VERSION ""

NS_ :

BS_:

BU_: VMCU TECU OBDScanT2 IC3 EMS ECUspare2 ECUspare1 DACU CIOM BBM

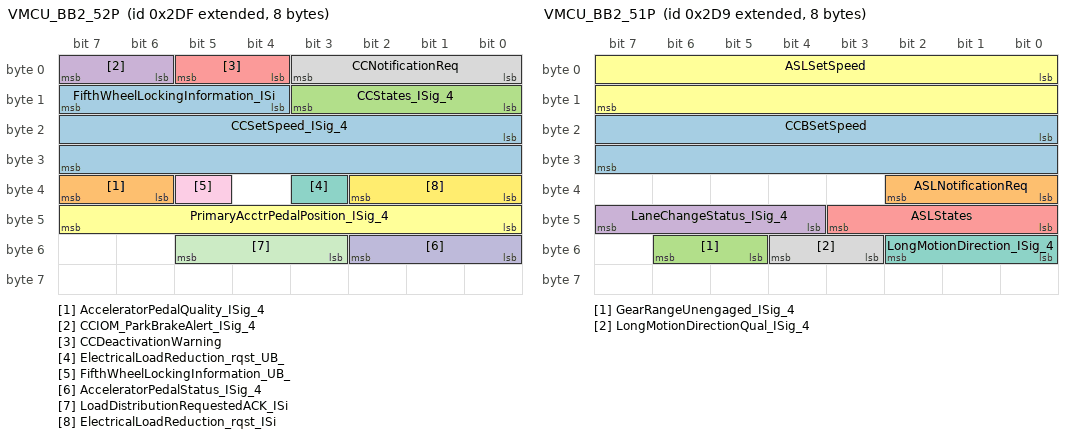
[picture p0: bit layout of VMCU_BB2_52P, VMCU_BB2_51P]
BO_ 2147484383 VMCU_BB2_52P: 8 VMCU
 SG_ CCSetSpeed_ISig_4 : 16|16@1+ (0.00390625,0) [0|255.99609375] "Km_per_h"  TECU,BBM,DACU,IC3
 SG_ AcceleratorPedalQuality_ISig_4 : 38|2@1+ (1,0) [0|0] ""  BBM,IC3
 SG_ CCStates_ISig_4 : 8|4@1+ (1,0) [0|0] ""  CIOM,DACU,IC3,BBM
 SG_ CCIOM_ParkBrakeAlert_ISig_4 : 6|2@1+ (1,0) [0|0] ""  IC3
 SG_ CCDeactivationWarning : 4|2@1+ (1,0) [0|0] ""  DACU
 SG_ PrimaryAcctrPedalPosition_ISig_4 : 40|8@1+ (0.4,0) [0|102] "Percent"  BBM
 SG_ ElectricalLoadReduction_rqst_UB_ : 35|1@1+ (1,0) [0|0] ""  CIOM
 SG_ CCNotificationReq : 0|4@1+ (1,0) [0|0] ""  IC3
 SG_ FifthWheelLockingInformation_UB_ : 37|1@1+ (1,0) [0|0] ""  BBM,IC3
 SG_ AcceleratorPedalStatus_ISig_4 : 48|3@1+ (1,0) [0|0] ""  CIOM,BBM
 SG_ LoadDistributionRequestedACK_ISi : 51|3@1+ (1,0) [0|0] ""  CIOM
 SG_ ElectricalLoadReduction_rqst_ISi : 32|3@1+ (1,0) [0|0] ""  CIOM
 SG_ FifthWheelLockingInformation_ISi : 12|4@1+ (1,0) [0|0] ""  BBM,IC3

BO_ 2147484377 VMCU_BB2_51P: 8 VMCU
 SG_ CCBSetSpeed : 16|16@1+ (0.00390625,0) [0|255.99609375] "Km_per_h"  DACU,TECU
 SG_ ASLNotificationReq : 32|3@1+ (1,0) [0|0] ""  IC3
 SG_ GearRangeUnengaged_ISig_4 : 53|2@1+ (1,0) [0|0] ""  IC3
 SG_ LaneChangeStatus_ISig_4 : 44|4@1+ (1,0) [0|0] ""  DACU,IC3
 SG_ ASLStates : 40|4@1+ (1,0) [0|0] ""  CIOM,IC3
 SG_ ASLSetSpeed : 0|16@1+ (0.00390625,0) [0|255.99609375] "Km_per_h"  IC3
 SG_ LongMotionDirection_ISig_4 : 48|3@1+ (1,0) [0|0] ""  BBM,CIOM
 SG_ LongMotionDirectionQual_ISig_4 : 51|2@1+ (1,0) [0|0] ""  CIOM

BO_ 2147484624 VMCU_BB2_34S_FCM: 8 CIOM
 SG_ VMCU_BB2_34S_FCS : 0|64@1+ (1,0) [0|0] ""  VMCU

BO_ 2147484621 VMCU_BB2_34S: 16 VMCU
 SG_ KeyID_KeyAuthEncrypted : 0|128@1+ (1,0) [0|0] ""  CIOM

BO_ 2147485066 VMCU_BB2_33S_FCM: 8 IC3
 SG_ VMCU_BB2_33S_FCS : 0|64@1+ (1,0) [0|0] ""  VMCU

BO_ 2147485065 VMCU_BB2_33S: 230 VMCU
 SG_ MaintInfoGrp_MaintOption30 : 52|4@1+ (1,0) [0|0] ""  IC3
 SG_ MaintInfoGrp_Unit36 : 363|3@1+ (1,0) [0|0] ""  IC3
 SG_ MaintInfoGrp_MaintOption33 : 40|4@1+ (1,0) [0|0] ""  IC3
 SG_ MaintInfoGrp_ResetAuthorized32 : 506|2@1+ (1,0) [0|0] ""  IC3
 SG_ MaintInfoGrp_Status10 : 395|3@1+ (1,0) [0|0] ""  IC3
 SG_ MaintInfoGrp_Unit2 : 459|3@1+ (1,0) [0|0] ""  IC3
 SG_ MaintInfoGrp_Unit14 : 160|3@1+ (1,0) [0|0] ""  IC3
 SG_ MaintInfoGrp_ResetAuthorized28 : 486|2@1+ (1,0) [0|0] ""  IC3
 SG_ MaintInfoGrp_ResetAuthorized10 : 510|2@1+ (1,0) [0|0] ""  IC3
 SG_ MaintInfoGrp_Status31 : 368|3@1+ (1,0) [0|0] ""  IC3
 SG_ MaintInfoGrp_Unit32 : 427|3@1+ (1,0) [0|0] ""  IC3
 SG_ MaintInfoGrp_Status15 : 251|3@1+ (1,0) [0|0] ""  IC3
 SG_ MaintInfoGrp_Supported19 : 278|2@1+ (1,0) [0|0] ""  IC3
 SG_ MaintInfoGrp_Unit34 : 312|3@1+ (1,0) [0|0] ""  IC3
 SG_ MaintInfoGrp_Data17 : 816|32@1+ (1,0) [0|4294967295] ""  IC3
 SG_ MaintInfoGrp_Unit26 : 179|3@1+ (1,0) [0|0] ""  IC3
 SG_ MaintInfoGrp_Data24 : 848|32@1+ (1,0) [0|4294967295] ""  IC3
 SG_ MaintInfoGrp_ResetAuthorized24 : 502|2@1+ (1,0) [0|0] ""  IC3
 SG_ MaintInfoGrp_ResetAuthorized34 : 454|2@1+ (1,0) [0|0] ""  IC3
 SG_ MaintInfoGrp_Unit28 : 176|3@1+ (1,0) [0|0] ""  IC3
 SG_ MaintInfoGrp_Status26 : 219|3@1+ (1,0) [0|0] ""  IC3
 SG_ MaintInfoGrp_Unit10 : 352|3@1+ (1,0) [0|0] ""  IC3
 SG_ MaintInfoGrp_Data12 : 1616|32@1+ (1,0) [0|4294967295] ""  IC3
 SG_ MaintInfoGrp_ResetAuthorized38 : 230|2@1+ (1,0) [0|0] ""  IC3
 SG_ MaintInfoGrp_MaintOption14 : 128|4@1+ (1,0) [0|0] ""  IC3
 SG_ MaintInfoGrp_MaintOption17 : 0|4@1+ (1,0) [0|0] ""  IC3
 SG_ MaintInfoGrp_Status33 : 360|3@1+ (1,0) [0|0] ""  IC3
 SG_ MaintInfoGrp_Unit6 : 203|3@1+ (1,0) [0|0] ""  IC3
 SG_ MaintInfoGrp_Supported7 : 504|2@1+ (1,0) [0|0] ""  IC3
 SG_ MaintInfoGrp_Status7 : 240|3@1+ (1,0) [0|0] ""  IC3
 SG_ MaintInfoGrp_ResetAuthorized2 : 462|2@1+ (1,0) [0|0] ""  IC3
 SG_ MaintInfoGrp_MaintOption27 : 44|4@1+ (1,0) [0|0] ""  IC3
 SG_ MaintInfoGrp_Supported36 : 492|2@1+ (1,0) [0|0] ""  IC3
 SG_ MaintInfoGrp_Unit22 : 171|3@1+ (1,0) [0|0] ""  IC3
 SG_ MaintInfoGrp_Unit18 : 315|3@1+ (1,0) [0|0] ""  IC3
 SG_ MaintInfoGrp_MaintOption28 : 96|4@1+ (1,0) [0|0] ""  IC3
 SG_ MaintInfoGrp_Supported18 : 526|2@1+ (1,0) [0|0] ""  IC3
 SG_ MaintInfoGrp_Status22 : 304|3@1+ (1,0) [0|0] ""  IC3
 SG_ MaintInfoGrp_Status30 : 200|3@1+ (1,0) [0|0] ""  IC3
 SG_ MaintInfoGrp_Status20 : 467|3@1+ (1,0) [0|0] ""  IC3
 SG_ MaintInfoGrp_Status38 : 419|3@1+ (1,0) [0|0] ""  IC3
 SG_ MaintInfoGrp_Data38 : 688|32@1+ (1,0) [0|4294967295] ""  IC3
 SG_ MaintInfoGrp_ResetAuthorized7 : 190|2@1+ (1,0) [0|0] ""  IC3
 SG_ MaintInfoGrp_Data19 : 1104|32@1+ (1,0) [0|4294967295] ""  IC3
 SG_ MaintInfoGrp_ResetAuthorized19 : 438|2@1+ (1,0) [0|0] ""  IC3
 SG_ MaintInfoGrp_ResetAuthorized12 : 542|2@1+ (1,0) [0|0] ""  IC3
 SG_ MaintInfoGrp_MaintOption8 : 108|4@1+ (1,0) [0|0] ""  IC3
 SG_ MaintInfoGrp_MaintOption9 : 56|4@1+ (1,0) [0|0] ""  IC3
 SG_ MaintInfoGrp_ResetAuthorized13 : 522|2@1+ (1,0) [0|0] ""  IC3
 SG_ MaintInfoGrp_Unit31 : 283|3@1+ (1,0) [0|0] ""  IC3
 SG_ MaintInfoGrp_Status2 : 400|3@1+ (1,0) [0|0] ""  IC3
 SG_ MaintInfoGrp_ResetAuthorized5 : 206|2@1+ (1,0) [0|0] ""  IC3
 SG_ MaintInfoGrp_Supported33 : 350|2@1+ (1,0) [0|0] ""  IC3
 SG_ MaintInfoGrp_Unit7 : 256|3@1+ (1,0) [0|0] ""  IC3
 SG_ MaintInfoGrp_Supported34 : 524|2@1+ (1,0) [0|0] ""  IC3
 SG_ MaintInfoGrp_Data16 : 1392|32@1+ (1,0) [0|4294967295] ""  IC3
 SG_ MaintInfoGrp_Unit19 : 299|3@1+ (1,0) [0|0] ""  IC3
 SG_ MaintInfoGrp_ResetAuthorized21 : 494|2@1+ (1,0) [0|0] ""  IC3
 SG_ MaintInfoGrp_ResetAuthorized31 : 552|2@1+ (1,0) [0|0] ""  IC3
 SG_ MaintInfoGrp_Data28 : 1488|32@1+ (1,0) [0|4294967295] ""  IC3
 SG_ MaintInfoGrp_ResetAuthorized3 : 374|2@1+ (1,0) [0|0] ""  IC3
 SG_ MaintInfoGrp_MaintOption34 : 12|4@1+ (1,0) [0|0] ""  IC3
 SG_ MaintInfoGrp_Status21 : 475|3@1+ (1,0) [0|0] ""  IC3
 SG_ MaintInfoGrp_Unit21 : 235|3@1+ (1,0) [0|0] ""  IC3
 SG_ MaintInfoGrp_MaintOption24 : 116|4@1+ (1,0) [0|0] ""  IC3
 SG_ MaintInfoGrp_Data26 : 976|32@1+ (1,0) [0|4294967295] ""  IC3
 SG_ MaintInfoGrp_Data37 : 752|32@1+ (1,0) [0|4294967295] ""  IC3
 SG_ MaintInfoGrp_Data35 : 1136|32@1+ (1,0) [0|4294967295] ""  IC3
 SG_ MaintInfoGrp_Supported17 : 222|2@1+ (1,0) [0|0] ""  IC3
 SG_ MaintInfoGrp_ResetAuthorized17 : 546|2@1+ (1,0) [0|0] ""  IC3
 SG_ MaintInfoGrp_Unit25 : 248|3@1+ (1,0) [0|0] ""  IC3
 SG_ MaintInfoGrp_Unit37 : 344|3@1+ (1,0) [0|0] ""  IC3
 SG_ MaintInfoGrp_MaintOption2 : 60|4@1+ (1,0) [0|0] ""  IC3
 SG_ MaintInfoGrp_Supported21 : 406|2@1+ (1,0) [0|0] ""  IC3
 SG_ MaintInfoGrp_ResetAuthorized16 : 270|2@1+ (1,0) [0|0] ""  IC3
 SG_ MaintInfoGrp_Supported15 : 528|2@1+ (1,0) [0|0] ""  IC3
 SG_ MaintInfoGrp_ResetAuthorized9 : 540|2@1+ (1,0) [0|0] ""  IC3
 SG_ MaintInfoGrp_MaintOption18 : 36|4@1+ (1,0) [0|0] ""  IC3
 SG_ MaintInfoGrp_Data14 : 1456|32@1+ (1,0) [0|4294967295] ""  IC3
 SG_ MaintInfoGrp_Data8 : 1808|32@1+ (1,0) [0|4294967295] ""  IC3
 SG_ MaintInfoGrp_Supported29 : 484|2@1+ (1,0) [0|0] ""  IC3
 SG_ MaintInfoGrp_ResetAuthorized39 : 558|2@1+ (1,0) [0|0] ""  IC3
 SG_ MaintInfoGrp_Supported32 : 358|2@1+ (1,0) [0|0] ""  IC3
 SG_ MaintInfoGrp_Data33 : 1328|32@1+ (1,0) [0|4294967295] ""  IC3
 SG_ MaintInfoGrp_ResetAuthorized35 : 550|2@1+ (1,0) [0|0] ""  IC3
 SG_ MaintInfoGrp_Data30 : 880|32@1+ (1,0) [0|4294967295] ""  IC3
 SG_ MaintInfoGrp_ResetAuthorized29 : 534|2@1+ (1,0) [0|0] ""  IC3
 SG_ MaintInfoGrp_Supported35 : 310|2@1+ (1,0) [0|0] ""  IC3
 SG_ MaintInfoGrp_ResetAuthorized4 : 530|2@1+ (1,0) [0|0] ""  IC3
 SG_ MaintInfoGrp_Data10 : 624|32@1+ (1,0) [0|4294967295] ""  IC3
 SG_ MaintInfoGrp_Data9 : 1584|32@1+ (1,0) [0|4294967295] ""  IC3
 SG_ MaintInfoGrp_Unit1 : 328|3@1+ (1,0) [0|0] ""  IC3
 SG_ MaintInfoGrp_MaintOption7 : 104|4@1+ (1,0) [0|0] ""  IC3
 SG_ MaintInfoGrp_Supported24 : 390|2@1+ (1,0) [0|0] ""  IC3
 SG_ MaintInfoGrp_Supported25 : 514|2@1+ (1,0) [0|0] ""  IC3
 SG_ MaintInfoGrp_Unit15 : 339|3@1+ (1,0) [0|0] ""  IC3
 SG_ MaintInfoGrp_Supported1 : 446|2@1+ (1,0) [0|0] ""  IC3
 SG_ MaintInfoGrp_ResetAuthorized11 : 254|2@1+ (1,0) [0|0] ""  IC3
 SG_ MaintInfoGrp_Supported13 : 238|2@1+ (1,0) [0|0] ""  IC3
 SG_ MaintInfoGrp_Supported10 : 490|2@1+ (1,0) [0|0] ""  IC3
 SG_ MaintInfoGrp_Data2 : 720|32@1+ (1,0) [0|4294967295] ""  IC3
 SG_ MaintInfoGrp_Unit16 : 243|3@1+ (1,0) [0|0] ""  IC3
 SG_ MaintInfoGrp_MaintOption35 : 144|4@1+ (1,0) [0|0] ""  IC3
 SG_ MaintInfoGrp_MaintOption22 : 156|4@1+ (1,0) [0|0] ""  IC3
 SG_ MaintInfoGrp_MaintOption12 : 8|4@1+ (1,0) [0|0] ""  IC3
 SG_ MaintInfoGrp_Supported9 : 342|2@1+ (1,0) [0|0] ""  IC3
 SG_ MaintInfoGrp_Supported31 : 512|2@1+ (1,0) [0|0] ""  IC3
 SG_ MaintInfoGrp_MaintOption37 : 100|4@1+ (1,0) [0|0] ""  IC3
 SG_ MaintInfoGrp_MaintOption13 : 120|4@1+ (1,0) [0|0] ""  IC3
 SG_ MaintInfoGrp_ResetAuthorized22 : 538|2@1+ (1,0) [0|0] ""  IC3
 SG_ MaintInfoGrp_Status14 : 259|3@1+ (1,0) [0|0] ""  IC3
 SG_ MaintInfoGrp_Status18 : 424|3@1+ (1,0) [0|0] ""  IC3
 SG_ MaintInfoGrp_Unit17 : 187|3@1+ (1,0) [0|0] ""  IC3
 SG_ MaintInfoGrp_Unit12 : 224|3@1+ (1,0) [0|0] ""  IC3
 SG_ MaintInfoGrp_Data22 : 1552|32@1+ (1,0) [0|4294967295] ""  IC3
 SG_ MaintInfoGrp_Supported27 : 262|2@1+ (1,0) [0|0] ""  IC3
 SG_ MaintInfoGrp_Unit4 : 163|3@1+ (1,0) [0|0] ""  IC3
 SG_ MaintInfoGrp_Data13 : 656|32@1+ (1,0) [0|4294967295] ""  IC3
 SG_ MaintInfoGrp_Status27 : 355|3@1+ (1,0) [0|0] ""  IC3
 SG_ MaintInfoGrp_MaintOption29 : 124|4@1+ (1,0) [0|0] ""  IC3
 SG_ MaintInfoGrp_Unit9 : 435|3@1+ (1,0) [0|0] ""  IC3
 SG_ MaintInfoGrp_Unit13 : 387|3@1+ (1,0) [0|0] ""  IC3
 SG_ MaintInfoGrp_Data25 : 560|32@1+ (1,0) [0|4294967295] ""  IC3
 SG_ MaintInfoGrp_Unit3 : 472|3@1+ (1,0) [0|0] ""  IC3
 SG_ MaintInfoGrp_MaintOption15 : 148|4@1+ (1,0) [0|0] ""  IC3
 SG_ MaintInfoGrp_ResetAuthorized15 : 508|2@1+ (1,0) [0|0] ""  IC3
 SG_ MaintInfoGrp_MaintOption11 : 68|4@1+ (1,0) [0|0] ""  IC3
 SG_ MaintInfoGrp_MaintOption25 : 112|4@1+ (1,0) [0|0] ""  IC3
 SG_ MaintInfoGrp_Supported16 : 174|2@1+ (1,0) [0|0] ""  IC3
 SG_ MaintInfoGrp_Supported23 : 544|2@1+ (1,0) [0|0] ""  IC3
 SG_ MaintInfoGrp_Status13 : 267|3@1+ (1,0) [0|0] ""  IC3
 SG_ MaintInfoGrp_Status17 : 307|3@1+ (1,0) [0|0] ""  IC3
 SG_ MaintInfoGrp_Unit8 : 275|3@1+ (1,0) [0|0] ""  IC3
 SG_ MaintInfoGrp_MaintOption38 : 64|4@1+ (1,0) [0|0] ""  IC3
 SG_ MaintInfoGrp_Data4 : 1040|32@1+ (1,0) [0|4294967295] ""  IC3
 SG_ MaintInfoGrp_Supported2 : 198|2@1+ (1,0) [0|0] ""  IC3
 SG_ MaintInfoGrp_ResetAuthorized0 : 516|2@1+ (1,0) [0|0] ""  IC3
 SG_ MaintInfoGrp_Supported5 : 478|2@1+ (1,0) [0|0] ""  IC3
 SG_ MaintInfoGrp_Status6 : 336|3@1+ (1,0) [0|0] ""  IC3
 SG_ MaintInfoGrp_Unit5 : 411|3@1+ (1,0) [0|0] ""  IC3
 SG_ MaintInfoGrp_Data0 : 592|32@1+ (1,0) [0|4294967295] ""  IC3
 SG_ MaintInfoGrp_Data29 : 1776|32@1+ (1,0) [0|4294967295] ""  IC3
 SG_ MaintInfoGrp_Supported28 : 498|2@1+ (1,0) [0|0] ""  IC3
 SG_ MaintInfoGrp_Status32 : 371|3@1+ (1,0) [0|0] ""  IC3
 SG_ MaintInfoGrp_MaintOption0 : 152|4@1+ (1,0) [0|0] ""  IC3
 SG_ MaintInfoGrp_ResetAuthorized25 : 480|2@1+ (1,0) [0|0] ""  IC3
 SG_ MaintInfoGrp_MaintOption32 : 28|4@1+ (1,0) [0|0] ""  IC3
 SG_ MaintInfoGrp_Unit11 : 464|3@1+ (1,0) [0|0] ""  IC3
 SG_ MaintInfoGrp_Data39 : 912|32@1+ (1,0) [0|4294967295] ""  IC3
 SG_ MaintInfoGrp_MaintOption4 : 80|4@1+ (1,0) [0|0] ""  IC3
 SG_ MaintInfoGrp_Supported38 : 302|2@1+ (1,0) [0|0] ""  IC3
 SG_ MaintInfoGrp_MaintOption1 : 136|4@1+ (1,0) [0|0] ""  IC3
 SG_ MaintInfoGrp_Supported30 : 182|2@1+ (1,0) [0|0] ""  IC3
 SG_ MaintInfoGrp_ResetAuthorized33 : 496|2@1+ (1,0) [0|0] ""  IC3
 SG_ MaintInfoGrp_Status0 : 392|3@1+ (1,0) [0|0] ""  IC3
 SG_ MaintInfoGrp_ResetAuthorized20 : 334|2@1+ (1,0) [0|0] ""  IC3
 SG_ MaintInfoGrp_Unit33 : 232|3@1+ (1,0) [0|0] ""  IC3
 SG_ MaintInfoGrp_Supported26 : 500|2@1+ (1,0) [0|0] ""  IC3
 SG_ MaintInfoGrp_ResetAuthorized6 : 532|2@1+ (1,0) [0|0] ""  IC3
 SG_ MaintInfoGrp_Data18 : 1648|32@1+ (1,0) [0|4294967295] ""  IC3
 SG_ MaintInfoGrp_Status16 : 432|3@1+ (1,0) [0|0] ""  IC3
 SG_ MaintInfoGrp_ResetAuthorized18 : 294|2@1+ (1,0) [0|0] ""  IC3
 SG_ MaintInfoGrp_Status4 : 168|3@1+ (1,0) [0|0] ""  IC3
 SG_ MaintInfoGrp_Data3 : 1072|32@1+ (1,0) [0|4294967295] ""  IC3
 SG_ MaintInfoGrp_MaintOption20 : 140|4@1+ (1,0) [0|0] ""  IC3
 SG_ MaintInfoGrp_ResetAuthorized30 : 166|2@1+ (1,0) [0|0] ""  IC3
 SG_ MaintInfoGrp_ResetAuthorized23 : 520|2@1+ (1,0) [0|0] ""  IC3
 SG_ MaintInfoGrp_Unit30 : 408|3@1+ (1,0) [0|0] ""  IC3
 SG_ MaintInfoGrp_Data20 : 944|32@1+ (1,0) [0|4294967295] ""  IC3
 SG_ MaintInfoGrp_MaintOption23 : 132|4@1+ (1,0) [0|0] ""  IC3
 SG_ MaintInfoGrp_Data23 : 1680|32@1+ (1,0) [0|4294967295] ""  IC3
 SG_ MaintInfoGrp_Unit20 : 376|3@1+ (1,0) [0|0] ""  IC3
 SG_ MaintInfoGrp_MaintOption10 : 76|4@1+ (1,0) [0|0] ""  IC3
 SG_ MaintInfoGrp_Status39 : 443|3@1+ (1,0) [0|0] ""  IC3
 SG_ MaintInfoGrp_Data21 : 1424|32@1+ (1,0) [0|4294967295] ""  IC3
 SG_ MaintInfoGrp_Status3 : 451|3@1+ (1,0) [0|0] ""  IC3
 SG_ MaintInfoGrp_Data5 : 784|32@1+ (1,0) [0|4294967295] ""  IC3
 SG_ MaintInfoGrp_ResetAuthorized26 : 556|2@1+ (1,0) [0|0] ""  IC3
 SG_ MaintInfoGrp_Supported12 : 366|2@1+ (1,0) [0|0] ""  IC3
 SG_ MaintInfoGrp_Data32 : 1296|32@1+ (1,0) [0|4294967295] ""  IC3
 SG_ MaintInfoGrp_Status29 : 323|3@1+ (1,0) [0|0] ""  IC3
 SG_ MaintInfoGrp_ResetAuthorized37 : 246|2@1+ (1,0) [0|0] ""  IC3
 SG_ MaintInfoGrp_Status36 : 379|3@1+ (1,0) [0|0] ""  IC3
 SG_ MaintInfoGrp_Supported22 : 326|2@1+ (1,0) [0|0] ""  IC3
 SG_ MaintInfoGrp_Status35 : 331|3@1+ (1,0) [0|0] ""  IC3
 SG_ MaintInfoGrp_Data7 : 1360|32@1+ (1,0) [0|4294967295] ""  IC3
 SG_ MaintInfoGrp_MaintOption26 : 48|4@1+ (1,0) [0|0] ""  IC3
 SG_ MaintInfoGrp_Status23 : 403|3@1+ (1,0) [0|0] ""  IC3
 SG_ MaintInfoGrp_Unit35 : 192|3@1+ (1,0) [0|0] ""  IC3
 SG_ MaintInfoGrp_Supported6 : 398|2@1+ (1,0) [0|0] ""  IC3
 SG_ MaintInfoGrp_Data34 : 1008|32@1+ (1,0) [0|4294967295] ""  IC3
 SG_ MaintInfoGrp_Unit27 : 416|3@1+ (1,0) [0|0] ""  IC3
 SG_ MaintInfoGrp_MaintOption19 : 72|4@1+ (1,0) [0|0] ""  IC3
 SG_ MaintInfoGrp_ResetAuthorized14 : 214|2@1+ (1,0) [0|0] ""  IC3
 SG_ MaintInfoGrp_Status34 : 272|3@1+ (1,0) [0|0] ""  IC3
 SG_ MaintInfoGrp_Supported37 : 286|2@1+ (1,0) [0|0] ""  IC3
 SG_ MaintInfoGrp_MaintOption3 : 20|4@1+ (1,0) [0|0] ""  IC3
 SG_ MaintInfoGrp_Status1 : 384|3@1+ (1,0) [0|0] ""  IC3
 SG_ MaintInfoGrp_Data1 : 1200|32@1+ (1,0) [0|4294967295] ""  IC3
 SG_ MaintInfoGrp_Status25 : 296|3@1+ (1,0) [0|0] ""  IC3
 SG_ MaintInfoGrp_ResetAuthorized1 : 318|2@1+ (1,0) [0|0] ""  IC3
 SG_ MaintInfoGrp_ResetAuthorized27 : 518|2@1+ (1,0) [0|0] ""  IC3
 SG_ MaintInfoGrp_ResetAuthorized36 : 470|2@1+ (1,0) [0|0] ""  IC3
 SG_ MaintInfoGrp_Status28 : 347|3@1+ (1,0) [0|0] ""  IC3
 SG_ MaintInfoGrp_Status24 : 280|3@1+ (1,0) [0|0] ""  IC3
 SG_ MaintInfoGrp_MaintOption31 : 32|4@1+ (1,0) [0|0] ""  IC3
 SG_ MaintInfoGrp_Supported20 : 482|2@1+ (1,0) [0|0] ""  IC3
 SG_ MaintInfoGrp_Unit38 : 195|3@1+ (1,0) [0|0] ""  IC3
 SG_ MaintInfoGrp_Unit24 : 448|3@1+ (1,0) [0|0] ""  IC3
 SG_ MaintInfoGrp_Data15 : 1264|32@1+ (1,0) [0|4294967295] ""  IC3
 SG_ MaintInfoGrp_Status37 : 440|3@1+ (1,0) [0|0] ""  IC3
 SG_ MaintInfoGrp_Supported39 : 414|2@1+ (1,0) [0|0] ""  IC3
 SG_ MaintInfoGrp_MaintOption39 : 4|4@1+ (1,0) [0|0] ""  IC3
 SG_ MaintInfoGrp_Supported4 : 430|2@1+ (1,0) [0|0] ""  IC3
 SG_ MaintInfoGrp_Supported3 : 536|2@1+ (1,0) [0|0] ""  IC3
 SG_ MaintInfoGrp_Data6 : 1520|32@1+ (1,0) [0|4294967295] ""  IC3
 SG_ MaintInfoGrp_Unit39 : 320|3@1+ (1,0) [0|0] ""  IC3
 SG_ MaintInfoGrp_Status5 : 291|3@1+ (1,0) [0|0] ""  IC3
 SG_ MaintInfoGrp_Data36 : 1232|32@1+ (1,0) [0|4294967295] ""  IC3
 SG_ MaintInfoGrp_MaintOption6 : 84|4@1+ (1,0) [0|0] ""  IC3
 SG_ MaintInfoGrp_Status11 : 211|3@1+ (1,0) [0|0] ""  IC3
 SG_ MaintInfoGrp_Status19 : 216|3@1+ (1,0) [0|0] ""  IC3
 SG_ MaintInfoGrp_Status9 : 288|3@1+ (1,0) [0|0] ""  IC3
 SG_ MaintInfoGrp_Supported11 : 548|2@1+ (1,0) [0|0] ""  IC3
 SG_ MaintInfoGrp_Data27 : 1168|32@1+ (1,0) [0|4294967295] ""  IC3
 SG_ MaintInfoGrp_Data31 : 1744|32@1+ (1,0) [0|4294967295] ""  IC3
 SG_ MaintInfoGrp_MaintOption36 : 16|4@1+ (1,0) [0|0] ""  IC3
 SG_ MaintInfoGrp_ResetAuthorized8 : 422|2@1+ (1,0) [0|0] ""  IC3
 SG_ MaintInfoGrp_MaintOption21 : 92|4@1+ (1,0) [0|0] ""  IC3
 SG_ MaintInfoGrp_Unit23 : 227|3@1+ (1,0) [0|0] ""  IC3
 SG_ MaintInfoGrp_MaintOption5 : 88|4@1+ (1,0) [0|0] ""  IC3
 SG_ MaintInfoGrp_MaintOption16 : 24|4@1+ (1,0) [0|0] ""  IC3
 SG_ MaintInfoGrp_Unit29 : 208|3@1+ (1,0) [0|0] ""  IC3
 SG_ MaintInfoGrp_Status12 : 184|3@1+ (1,0) [0|0] ""  IC3
 SG_ MaintInfoGrp_Supported0 : 554|2@1+ (1,0) [0|0] ""  IC3
 SG_ MaintInfoGrp_Status8 : 456|3@1+ (1,0) [0|0] ""  IC3
 SG_ MaintInfoGrp_Data11 : 1712|32@1+ (1,0) [0|4294967295] ""  IC3
 SG_ MaintInfoGrp_Unit0 : 264|3@1+ (1,0) [0|0] ""  IC3
 SG_ MaintInfoGrp_Supported14 : 488|2@1+ (1,0) [0|0] ""  IC3
 SG_ MaintInfoGrp_Supported8 : 382|2@1+ (1,0) [0|0] ""  IC3

BO_ 2147484995 VMCU_BB2_32S_FCM: 8 CIOM
 SG_ VMCU_BB2_32S_FCS : 0|64@1+ (1,0) [0|0] ""  VMCU

BO_ 2147484993 VMCU_BB2_32S: 11 VMCU
 SG_ ECU2VIN_stat_ISig_4 : 0|88@1+ (1,0) [0|0] ""  CIOM

BO_ 2147485021 VMCU_BB2_31S_FCM: 8 CIOM
 SG_ VMCU_BB2_31S_FCS : 0|64@1+ (1,0) [0|0] ""  VMCU

BO_ 2147485020 VMCU_BB2_31S: 11 VMCU
 SG_ ECU1VIN_stat : 0|88@1+ (1,0) [0|0] ""  CIOM

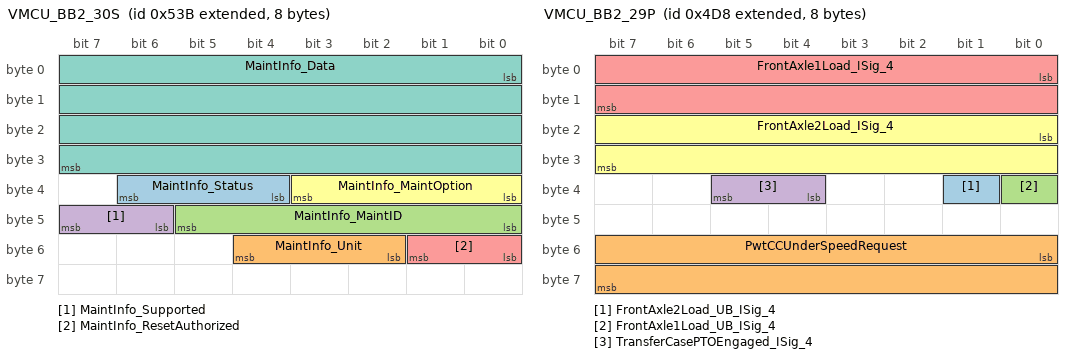
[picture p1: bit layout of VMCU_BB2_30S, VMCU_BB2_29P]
BO_ 2147484987 VMCU_BB2_30S: 8 VMCU
 SG_ MaintInfo_Status : 36|3@1+ (1,0) [0|0] ""  IC3
 SG_ MaintInfo_Unit : 50|3@1+ (1,0) [0|0] ""  IC3
 SG_ MaintInfo_MaintID : 40|6@1+ (1,0) [0|0] ""  IC3
 SG_ MaintInfo_Supported : 46|2@1+ (1,0) [0|0] ""  IC3
 SG_ MaintInfo_ResetAuthorized : 48|2@1+ (1,0) [0|0] ""  IC3
 SG_ MaintInfo_MaintOption : 32|4@1+ (1,0) [0|0] ""  IC3
 SG_ MaintInfo_Data : 0|32@1+ (1,0) [0|4294967295] ""  IC3

BO_ 2147484888 VMCU_BB2_29P: 8 VMCU
 SG_ FrontAxle2Load_UB_ISig_4 : 33|1@1+ (1,0) [0|0] ""  TECU,BBM,DACU,IC3
 SG_ PwtCCUnderSpeedRequest : 48|16@1+ (0.00390625,0) [0|255.99609375] "Km_per_h"  TECU
 SG_ FrontAxle1Load_UB_ISig_4 : 32|1@1+ (1,0) [0|0] ""  TECU,DACU,IC3,BBM
 SG_ TransferCasePTOEngaged_ISig_4 : 36|2@1+ (1,0) [0|0] ""  CIOM
 SG_ FrontAxle1Load_ISig_4 : 0|16@1+ (0.5,0) [0|32767.5] "kg"  DACU,TECU,BBM
 SG_ FrontAxle2Load_ISig_4 : 16|16@1+ (0.5,0) [0|32767.5] "kg"  DACU,BBM,TECU

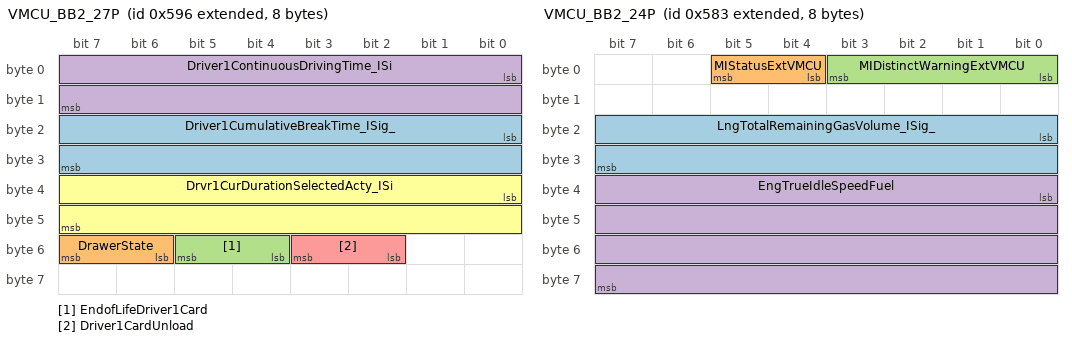
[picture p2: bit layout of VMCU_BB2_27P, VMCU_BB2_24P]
BO_ 2147485078 VMCU_BB2_27P: 8 VMCU
 SG_ Driver1CumulativeBreakTime_ISig_ : 16|16@1+ (1,0) [0|65535] "min"  IC3
 SG_ DrawerState : 54|2@1+ (1,0) [0|0] ""  IC3
 SG_ EndofLifeDriver1Card : 52|2@1+ (1,0) [0|0] ""  IC3
 SG_ Driver1ContinuousDrivingTime_ISi : 0|16@1+ (1,0) [0|65535] "min"  IC3
 SG_ Driver1CardUnload : 50|2@1+ (1,0) [0|0] ""  IC3
 SG_ Drvr1CurDurationSelectedActy_ISi : 32|16@1+ (1,0) [0|65535] "min"  IC3

BO_ 2147485061 VMCU_BB2_26P: 8 VMCU
 SG_ FuelConsumptionPTO : 32|32@1+ (0.01,0) [0|42949672.95] "l"  IC3
 SG_ AtLeastOnePTOActivationTime_ISig : 0|32@1+ (1,0) [0|4294967295] "s"  IC3,BBM

BO_ 2147485060 VMCU_BB2_25P: 8 VMCU
 SG_ EngineGreenAreaOutFuel_ISig_4 : 0|32@1+ (0.01,0) [0|42949672.95] "l"  IC3
 SG_ CCTime : 32|32@1+ (1,0) [0|4294967295] "s"  IC3

BO_ 2147485059 VMCU_BB2_24P: 8 VMCU
 SG_ LngTotalRemainingGasVolume_ISig_ : 16|16@1+ (1,0) [0|65535] "kg"  IC3
 SG_ MIStatusExtVMCU : 4|2@1+ (1,0) [0|0] ""  EMS
 SG_ MIDistinctWarningExtVMCU : 0|4@1+ (1,0) [0|0] ""  EMS
 SG_ EngTrueIdleSpeedFuel : 32|32@1+ (0.01,0) [0|42949672.95] "l"  IC3

BO_ 2147485036 VMCU_BB2_23P: 8 VMCU
 SG_ FuelConsumptionVehicleStopped : 32|32@1+ (0.01,0) [0|42949672.95] "l"  IC3
 SG_ FuelConsumptionVehicleRunning_IS : 0|32@1+ (0.01,0) [0|42949672.95] "l"  IC3

BO_ 2147485037 VMCU_BB2_22P: 8 VMCU
 SG_ AdBlueConsumptVehicleRunning : 0|32@1+ (0.01,0) [0|42949672.95] "l"  IC3
 SG_ AdBlueConsumptVehicleStopped : 32|32@1+ (0.01,0) [0|42949672.95] "l"  IC3

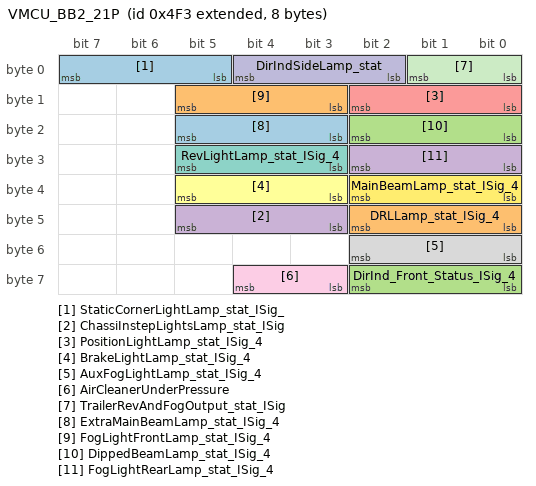
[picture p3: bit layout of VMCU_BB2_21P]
BO_ 2147484915 VMCU_BB2_21P: 8 VMCU
 SG_ StaticCornerLightLamp_stat_ISig_ : 5|3@1+ (1,0) [0|0] ""  IC3
 SG_ DRLLamp_stat_ISig_4 : 40|3@1+ (1,0) [0|0] ""  IC3
 SG_ DirInd_Front_Status_ISig_4 : 56|3@1+ (1,0) [0|0] ""  IC3
 SG_ ChassiInstepLightsLamp_stat_ISig : 43|3@1+ (1,0) [0|0] ""  IC3
 SG_ PositionLightLamp_stat_ISig_4 : 8|3@1+ (1,0) [0|0] ""  IC3
 SG_ BrakeLightLamp_stat_ISig_4 : 35|3@1+ (1,0) [0|0] ""  IC3
 SG_ RevLightLamp_stat_ISig_4 : 27|3@1+ (1,0) [0|0] ""  IC3
 SG_ AuxFogLightLamp_stat_ISig_4 : 48|3@1+ (1,0) [0|0] ""  IC3
 SG_ AirCleanerUnderPressure : 59|2@1+ (1,0) [0|0] ""  IC3
 SG_ DirIndSideLamp_stat : 2|3@1+ (1,0) [0|0] ""  IC3
 SG_ TrailerRevAndFogOutput_stat_ISig : 0|2@1+ (1,0) [0|0] ""  IC3
 SG_ MainBeamLamp_stat_ISig_4 : 32|3@1+ (1,0) [0|0] ""  IC3
 SG_ ExtraMainBeamLamp_stat_ISig_4 : 19|3@1+ (1,0) [0|0] ""  IC3
 SG_ FogLightFrontLamp_stat_ISig_4 : 11|3@1+ (1,0) [0|0] ""  IC3
 SG_ DippedBeamLamp_stat_ISig_4 : 16|3@1+ (1,0) [0|0] ""  IC3
 SG_ FogLightRearLamp_stat_ISig_4 : 24|3@1+ (1,0) [0|0] ""  IC3

CM_ SG_ 2147484383 CCSetSpeed_ISig_4 "65024 - 65279 Error ; 65280 - 65535 Not available";
CM_ SG_ 2147484377 CCBSetSpeed "65024 - 65279 Error ; 65280 - 65535 Not available";
CM_ SG_ 2147484377 ASLSetSpeed "65024 - 65279 Error ; 65280 - 65535 Not available";
CM_ SG_ 2147484888 FrontAxle1Load_ISig_4 "65024 - 65279 Error ; 65280 - 65535 Not available";
CM_ SG_ 2147484888 FrontAxle2Load_ISig_4 "65024 - 65279 Error ; 65280 - 65535 Not available";
CM_ SG_ 2147485078 Driver1CumulativeBreakTime_ISig_ "65024 - 65279 Error ; 65280 - 65535 Not available";
CM_ SG_ 2147485078 Driver1ContinuousDrivingTime_ISi "65024 - 65279 Error ; 65280 - 65535 Not available";
CM_ SG_ 2147485078 Drvr1CurDurationSelectedActy_ISi "65024 - 65279 Error ; 65280 - 65535 Not available";
CM_ SG_ 2147485061 AtLeastOnePTOActivationTime_ISig "4294967295 Not available";
CM_ SG_ 2147485060 EngineGreenAreaOutFuel_ISig_4 "4294967295 Not available";
CM_ SG_ 2147485060 CCTime "4294967295 Not available";
CM_ SG_ 2147485059 EngTrueIdleSpeedFuel "4294967295 Not available";
CM_ SG_ 2147485036 FuelConsumptionVehicleStopped "4294967295 Not available";
CM_ SG_ 2147485036 FuelConsumptionVehicleRunning_IS "4294967295 Not available";
CM_ SG_ 2147485037 AdBlueConsumptVehicleRunning "4294967295 Not available";
CM_ SG_ 2147485037 AdBlueConsumptVehicleStopped "4294967295 Not available";
BA_DEF_ BO_  "GenMsgStartDelayTime" INT 0 0;
BA_DEF_ BO_  "GenMsgDelayTime" INT 0 0;
BA_DEF_ BO_  "GenMsgCycleTime" INT 0 0;
BA_DEF_ BO_  "GenMsgSendType" ENUM  "Cyclic","NotUsed","NotUsed","NotUsed","NotUsed","NotUsed","NotUsed","IfActive","NoMsgSendType","NotUsed";
BA_DEF_ SG_  "GenSigStartValue" INT 0 0;
BA_DEF_ SG_  "GenSigCycleTimeActive" INT 0 0;
BA_DEF_ SG_  "GenSigCycleTime" INT 0 0;
BA_DEF_ SG_  "GenSigSendType" ENUM  "Cyclic","OnWrite","OnWriteWithRepetition","OnChange","OnChangeWithRepetition","IfActive","IfActiveWithRepetition","NoSigSendType","NotUsed","NotUsed","NotUsed","NotUsed","NotUsed";
BA_DEF_ BO_  "VFrameFormat" ENUM  "StandardCAN","ExtendedCAN","reserved","J1939PG";
BA_DEF_ SG_  "SigType" ENUM  "Default","Range","RangeSigned","ASCII","Discrete","Control","ReferencePGN","DTC","StringDelimiter","StringLength","StringLengthControl";
BA_DEF_ SG_  "SeToolVersion_SIGNAL" STRING ;
BA_DEF_ SG_  "SeToolUniqueID_SIGNAL" STRING ;
BA_DEF_ SG_  "SeToolOwnerSigGroup_SIGNAL" STRING ;
BA_DEF_ SG_  "SeToolOwnerSigGroupID_SIGNAL" STRING ;
BA_DEF_ SG_  "SeToolName_SIGNAL" STRING ;
BA_DEF_ SG_  "SeToolItemID_SIGNAL" STRING ;
BA_DEF_ SG_  "SeToolAncestorID_SIGNAL" STRING ;
BA_DEF_ SG_  "Platform_VMCU1_Sig" ENUM  "No","Yes";
BA_DEF_ BO_  "NmAsrMessage" ENUM  "No","Yes";
BA_DEF_ SG_  "NeedsUpdateBit" ENUM  "No","Yes";
BA_DEF_ SG_  "MmAnSignal" ENUM  "No","Yes";
BA_DEF_ SG_  "GenSigMaxLatency" INT 0 65535;
BA_DEF_ SG_  "GenSigILSupport" ENUM  "Yes","No";
BA_DEF_ BO_  "GenMsgRequestable" INT 0 1;
BA_DEF_ BO_  "GenMsgILSupport" ENUM  "No","Yes";
BA_DEF_ BO_  "DiagUUDTResponse" ENUM  "No","Yes";
BA_DEF_ BO_  "DiagState" ENUM  "No","Yes";
BA_DEF_ BO_  "DiagResponse" ENUM  "No","Yes";
BA_DEF_ BO_  "DiagRequest" ENUM  "No","Yes";
BA_DEF_ BO_  "DiagConnection" HEX 0 65535;
BA_DEF_ BO_  "CanTpSTmin" INT 0 255;
BA_DEF_ BO_  "CanTpFcFrameId" HEX 0 2147483647;
BA_DEF_ BO_  "CanTpBs" INT 0 255;
BA_DEF_ SG_  "SystemSignalLongSymbol" STRING ;
BA_DEF_REL_ BU_SG_REL_  "GenSigTimeoutTime" INT 0 65535;
BA_DEF_REL_ BU_SG_REL_  "GenSigFirstTimeoutTime" INT 0 65535;
BA_DEF_DEF_  "GenMsgStartDelayTime" 0;
BA_DEF_DEF_  "GenMsgDelayTime" 0;
BA_DEF_DEF_  "GenMsgCycleTime" 0;
BA_DEF_DEF_  "GenMsgSendType" "Cyclic";
BA_DEF_DEF_  "GenSigStartValue" 0;
BA_DEF_DEF_  "GenSigCycleTimeActive" 0;
BA_DEF_DEF_  "GenSigCycleTime" 0;
BA_DEF_DEF_  "GenSigSendType" "Cyclic";
BA_DEF_DEF_  "VFrameFormat" "ExtendedCAN";
BA_DEF_DEF_  "SigType" "Default";
BA_DEF_DEF_  "SeToolVersion_SIGNAL" "";
BA_DEF_DEF_  "SeToolUniqueID_SIGNAL" "";
BA_DEF_DEF_  "SeToolOwnerSigGroup_SIGNAL" "";
BA_DEF_DEF_  "SeToolOwnerSigGroupID_SIGNAL" "";
BA_DEF_DEF_  "SeToolName_SIGNAL" "";
BA_DEF_DEF_  "SeToolItemID_SIGNAL" "";
BA_DEF_DEF_  "SeToolAncestorID_SIGNAL" "";
BA_DEF_DEF_  "Platform_VMCU1_Sig" "No";
BA_DEF_DEF_  "NmAsrMessage" "No";
BA_DEF_DEF_  "NeedsUpdateBit" "No";
BA_DEF_DEF_  "MmAnSignal" "No";
BA_DEF_DEF_  "GenSigMaxLatency" 0;
BA_DEF_DEF_  "GenSigILSupport" "Yes";
BA_DEF_DEF_  "GenMsgRequestable" 1;
BA_DEF_DEF_  "GenMsgILSupport" "Yes";
BA_DEF_DEF_  "DiagUUDTResponse" "No";
BA_DEF_DEF_  "DiagState" "No";
BA_DEF_DEF_  "DiagResponse" "No";
BA_DEF_DEF_  "DiagRequest" "No";
BA_DEF_DEF_  "DiagConnection" 0;
BA_DEF_DEF_  "CanTpSTmin" 0;
BA_DEF_DEF_  "CanTpFcFrameId" 2147483647;
BA_DEF_DEF_  "CanTpBs" 255;
BA_DEF_DEF_REL_ "GenSigTimeoutTime" 0;
BA_DEF_DEF_REL_ "GenSigFirstTimeoutTime" 0;
BA_DEF_DEF_  "SystemSignalLongSymbol" "";
BA_ "GenMsgCycleTime" BO_ 2147484383 35;
BA_ "GenMsgCycleTime" BO_ 2147484377 30;
BA_ "GenMsgStartDelayTime" BO_ 2147484377 15;
BA_ "GenMsgILSupport" BO_ 2147484624 0;
BA_ "GenMsgSendType" BO_ 2147484624 8;
BA_ "CanTpFcFrameId" BO_ 2147484621 976;
BA_ "GenMsgSendType" BO_ 2147484621 8;
BA_ "GenMsgDelayTime" BO_ 2147484621 80;
BA_ "CanTpSTmin" BO_ 2147485066 5;
BA_ "GenMsgILSupport" BO_ 2147485066 0;
BA_ "GenMsgSendType" BO_ 2147485066 8;
BA_ "CanTpFcFrameId" BO_ 2147485065 1418;
BA_ "CanTpSTmin" BO_ 2147485065 5;
BA_ "GenMsgSendType" BO_ 2147485065 8;
BA_ "GenMsgDelayTime" BO_ 2147485065 2500;
BA_ "GenMsgStartDelayTime" BO_ 2147485065 50;
BA_ "GenMsgILSupport" BO_ 2147484995 0;
BA_ "GenMsgSendType" BO_ 2147484995 8;
BA_ "CanTpFcFrameId" BO_ 2147484993 1347;
BA_ "GenMsgSendType" BO_ 2147484993 8;
BA_ "GenMsgDelayTime" BO_ 2147484993 110;
BA_ "GenMsgILSupport" BO_ 2147485021 0;
BA_ "GenMsgSendType" BO_ 2147485021 8;
BA_ "CanTpFcFrameId" BO_ 2147485020 1373;
BA_ "GenMsgSendType" BO_ 2147485020 8;
BA_ "GenMsgDelayTime" BO_ 2147485020 110;
BA_ "GenMsgSendType" BO_ 2147484987 8;
BA_ "GenMsgDelayTime" BO_ 2147484987 80;
BA_ "GenMsgStartDelayTime" BO_ 2147484987 50;
BA_ "GenMsgCycleTime" BO_ 2147484888 250;
BA_ "GenMsgStartDelayTime" BO_ 2147484888 25;
BA_ "GenMsgCycleTime" BO_ 2147485078 1000;
BA_ "GenMsgStartDelayTime" BO_ 2147485078 295;
BA_ "GenMsgCycleTime" BO_ 2147485061 1000;
BA_ "GenMsgStartDelayTime" BO_ 2147485061 390;
BA_ "GenMsgCycleTime" BO_ 2147485060 1000;
BA_ "GenMsgStartDelayTime" BO_ 2147485060 485;
BA_ "GenMsgCycleTime" BO_ 2147485059 1000;
BA_ "GenMsgStartDelayTime" BO_ 2147485059 580;
BA_ "GenMsgCycleTime" BO_ 2147485036 1000;
BA_ "GenMsgStartDelayTime" BO_ 2147485036 675;
BA_ "GenMsgCycleTime" BO_ 2147485037 1000;
BA_ "GenMsgStartDelayTime" BO_ 2147485037 770;
BA_ "GenMsgCycleTime" BO_ 2147484915 250;
BA_ "GenMsgStartDelayTime" BO_ 2147484915 90;
BA_ "GenSigCycleTime" SG_ 2147484383 CCSetSpeed_ISig_4 100;
BA_ "GenSigCycleTimeActive" SG_ 2147484383 CCSetSpeed_ISig_4 100;
BA_ "GenSigStartValue" SG_ 2147484383 CCSetSpeed_ISig_4 65535;
BA_ "GenSigMaxLatency" SG_ 2147484383 CCSetSpeed_ISig_4 40;
BA_ "Platform_VMCU1_Sig" SG_ 2147484383 CCSetSpeed_ISig_4 1;
BA_ "GenSigCycleTime" SG_ 2147484383 AcceleratorPedalQuality_ISig_4 100;
BA_ "GenSigCycleTimeActive" SG_ 2147484383 AcceleratorPedalQuality_ISig_4 100;
BA_ "GenSigStartValue" SG_ 2147484383 AcceleratorPedalQuality_ISig_4 3;
BA_ "Platform_VMCU1_Sig" SG_ 2147484383 AcceleratorPedalQuality_ISig_4 1;
BA_ "GenSigCycleTime" SG_ 2147484383 CCStates_ISig_4 100;
BA_ "GenSigCycleTimeActive" SG_ 2147484383 CCStates_ISig_4 100;
BA_ "GenSigStartValue" SG_ 2147484383 CCStates_ISig_4 15;
BA_ "GenSigMaxLatency" SG_ 2147484383 CCStates_ISig_4 40;
BA_ "Platform_VMCU1_Sig" SG_ 2147484383 CCStates_ISig_4 1;
BA_ "GenSigCycleTime" SG_ 2147484383 CCIOM_ParkBrakeAlert_ISig_4 100;
BA_ "GenSigCycleTimeActive" SG_ 2147484383 CCIOM_ParkBrakeAlert_ISig_4 100;
BA_ "GenSigStartValue" SG_ 2147484383 CCIOM_ParkBrakeAlert_ISig_4 3;
BA_ "Platform_VMCU1_Sig" SG_ 2147484383 CCIOM_ParkBrakeAlert_ISig_4 1;
BA_ "GenSigCycleTime" SG_ 2147484383 CCDeactivationWarning 100;
BA_ "GenSigCycleTimeActive" SG_ 2147484383 CCDeactivationWarning 100;
BA_ "GenSigStartValue" SG_ 2147484383 CCDeactivationWarning 3;
BA_ "GenSigMaxLatency" SG_ 2147484383 CCDeactivationWarning 40;
BA_ "Platform_VMCU1_Sig" SG_ 2147484383 CCDeactivationWarning 1;
BA_ "SeToolAncestorID_SIGNAL" SG_ 2147484383 CCDeactivationWarning "x0000001D04184560";
BA_ "SeToolItemID_SIGNAL" SG_ 2147484383 CCDeactivationWarning "x0000001D043C571E";
BA_ "SeToolName_SIGNAL" SG_ 2147484383 CCDeactivationWarning "CCDeactivationWarning";
BA_ "SeToolVersion_SIGNAL" SG_ 2147484383 CCDeactivationWarning "2";
BA_ "GenSigCycleTime" SG_ 2147484383 PrimaryAcctrPedalPosition_ISig_4 100;
BA_ "GenSigCycleTimeActive" SG_ 2147484383 PrimaryAcctrPedalPosition_ISig_4 100;
BA_ "GenSigStartValue" SG_ 2147484383 PrimaryAcctrPedalPosition_ISig_4 255;
BA_ "Platform_VMCU1_Sig" SG_ 2147484383 PrimaryAcctrPedalPosition_ISig_4 1;
BA_ "GenSigSendType" SG_ 2147484383 ElectricalLoadReduction_rqst_UB_ 7;
BA_ "Platform_VMCU1_Sig" SG_ 2147484383 ElectricalLoadReduction_rqst_UB_ 1;
BA_ "SystemSignalLongSymbol" SG_ 2147484383 ElectricalLoadReduction_rqst_UB_ "ElectricalLoadReduction_rqst_UB_ISig_4";
BA_ "GenSigCycleTime" SG_ 2147484383 CCNotificationReq 100;
BA_ "GenSigCycleTimeActive" SG_ 2147484383 CCNotificationReq 100;
BA_ "GenSigStartValue" SG_ 2147484383 CCNotificationReq 15;
BA_ "GenSigMaxLatency" SG_ 2147484383 CCNotificationReq 40;
BA_ "Platform_VMCU1_Sig" SG_ 2147484383 CCNotificationReq 1;
BA_ "SeToolAncestorID_SIGNAL" SG_ 2147484383 CCNotificationReq "x0000001D0418455E";
BA_ "SeToolItemID_SIGNAL" SG_ 2147484383 CCNotificationReq "x0000001D043A835E";
BA_ "SeToolName_SIGNAL" SG_ 2147484383 CCNotificationReq "CCInformationMessageRequest";
BA_ "SeToolVersion_SIGNAL" SG_ 2147484383 CCNotificationReq "3";
BA_ "GenSigSendType" SG_ 2147484383 FifthWheelLockingInformation_UB_ 7;
BA_ "Platform_VMCU1_Sig" SG_ 2147484383 FifthWheelLockingInformation_UB_ 1;
BA_ "SystemSignalLongSymbol" SG_ 2147484383 FifthWheelLockingInformation_UB_ "FifthWheelLockingInformation_UB_ISig_4";
BA_ "GenSigCycleTime" SG_ 2147484383 AcceleratorPedalStatus_ISig_4 100;
BA_ "GenSigCycleTimeActive" SG_ 2147484383 AcceleratorPedalStatus_ISig_4 100;
BA_ "GenSigStartValue" SG_ 2147484383 AcceleratorPedalStatus_ISig_4 7;
BA_ "Platform_VMCU1_Sig" SG_ 2147484383 AcceleratorPedalStatus_ISig_4 1;
BA_ "GenSigCycleTime" SG_ 2147484383 LoadDistributionRequestedACK_ISi 100;
BA_ "GenSigCycleTimeActive" SG_ 2147484383 LoadDistributionRequestedACK_ISi 100;
BA_ "GenSigStartValue" SG_ 2147484383 LoadDistributionRequestedACK_ISi 7;
BA_ "Platform_VMCU1_Sig" SG_ 2147484383 LoadDistributionRequestedACK_ISi 1;
BA_ "SystemSignalLongSymbol" SG_ 2147484383 LoadDistributionRequestedACK_ISi "LoadDistributionRequestedACK_ISig_4";
BA_ "GenSigCycleTime" SG_ 2147484383 ElectricalLoadReduction_rqst_ISi 100;
BA_ "GenSigCycleTimeActive" SG_ 2147484383 ElectricalLoadReduction_rqst_ISi 100;
BA_ "GenSigStartValue" SG_ 2147484383 ElectricalLoadReduction_rqst_ISi 7;
BA_ "NeedsUpdateBit" SG_ 2147484383 ElectricalLoadReduction_rqst_ISi 1;
BA_ "Platform_VMCU1_Sig" SG_ 2147484383 ElectricalLoadReduction_rqst_ISi 1;
BA_ "SystemSignalLongSymbol" SG_ 2147484383 ElectricalLoadReduction_rqst_ISi "ElectricalLoadReduction_rqst_ISig_4";
BA_ "GenSigCycleTime" SG_ 2147484383 FifthWheelLockingInformation_ISi 100;
BA_ "GenSigCycleTimeActive" SG_ 2147484383 FifthWheelLockingInformation_ISi 100;
BA_ "GenSigStartValue" SG_ 2147484383 FifthWheelLockingInformation_ISi 15;
BA_ "GenSigMaxLatency" SG_ 2147484383 FifthWheelLockingInformation_ISi 112;
BA_ "NeedsUpdateBit" SG_ 2147484383 FifthWheelLockingInformation_ISi 1;
BA_ "Platform_VMCU1_Sig" SG_ 2147484383 FifthWheelLockingInformation_ISi 1;
BA_ "SystemSignalLongSymbol" SG_ 2147484383 FifthWheelLockingInformation_ISi "FifthWheelLockingInformation_ISig_4";
BA_ "GenSigCycleTime" SG_ 2147484377 CCBSetSpeed 100;
BA_ "GenSigCycleTimeActive" SG_ 2147484377 CCBSetSpeed 100;
BA_ "GenSigStartValue" SG_ 2147484377 CCBSetSpeed 65535;
BA_ "GenSigMaxLatency" SG_ 2147484377 CCBSetSpeed 34;
BA_ "Platform_VMCU1_Sig" SG_ 2147484377 CCBSetSpeed 1;
BA_ "GenSigCycleTime" SG_ 2147484377 ASLNotificationReq 100;
BA_ "GenSigCycleTimeActive" SG_ 2147484377 ASLNotificationReq 100;
BA_ "GenSigStartValue" SG_ 2147484377 ASLNotificationReq 7;
BA_ "GenSigMaxLatency" SG_ 2147484377 ASLNotificationReq 34;
BA_ "Platform_VMCU1_Sig" SG_ 2147484377 ASLNotificationReq 1;
BA_ "GenSigCycleTime" SG_ 2147484377 GearRangeUnengaged_ISig_4 100;
BA_ "GenSigCycleTimeActive" SG_ 2147484377 GearRangeUnengaged_ISig_4 100;
BA_ "GenSigStartValue" SG_ 2147484377 GearRangeUnengaged_ISig_4 3;
BA_ "Platform_VMCU1_Sig" SG_ 2147484377 GearRangeUnengaged_ISig_4 1;
BA_ "GenSigCycleTime" SG_ 2147484377 LaneChangeStatus_ISig_4 100;
BA_ "GenSigCycleTimeActive" SG_ 2147484377 LaneChangeStatus_ISig_4 100;
BA_ "GenSigStartValue" SG_ 2147484377 LaneChangeStatus_ISig_4 15;
BA_ "Platform_VMCU1_Sig" SG_ 2147484377 LaneChangeStatus_ISig_4 1;
BA_ "GenSigCycleTime" SG_ 2147484377 ASLStates 100;
BA_ "GenSigCycleTimeActive" SG_ 2147484377 ASLStates 100;
BA_ "GenSigStartValue" SG_ 2147484377 ASLStates 15;
BA_ "GenSigMaxLatency" SG_ 2147484377 ASLStates 34;
BA_ "Platform_VMCU1_Sig" SG_ 2147484377 ASLStates 1;
BA_ "GenSigCycleTime" SG_ 2147484377 ASLSetSpeed 100;
BA_ "GenSigCycleTimeActive" SG_ 2147484377 ASLSetSpeed 100;
BA_ "GenSigStartValue" SG_ 2147484377 ASLSetSpeed 65535;
BA_ "GenSigMaxLatency" SG_ 2147484377 ASLSetSpeed 34;
BA_ "Platform_VMCU1_Sig" SG_ 2147484377 ASLSetSpeed 1;
BA_ "GenSigCycleTime" SG_ 2147484377 LongMotionDirection_ISig_4 20;
BA_ "GenSigCycleTimeActive" SG_ 2147484377 LongMotionDirection_ISig_4 100;
BA_ "GenSigStartValue" SG_ 2147484377 LongMotionDirection_ISig_4 7;
BA_ "Platform_VMCU1_Sig" SG_ 2147484377 LongMotionDirection_ISig_4 1;
BA_ "GenSigCycleTime" SG_ 2147484377 LongMotionDirectionQual_ISig_4 20;
BA_ "GenSigCycleTimeActive" SG_ 2147484377 LongMotionDirectionQual_ISig_4 100;
BA_ "GenSigStartValue" SG_ 2147484377 LongMotionDirectionQual_ISig_4 3;
BA_ "Platform_VMCU1_Sig" SG_ 2147484377 LongMotionDirectionQual_ISig_4 1;
BA_ "GenSigSendType" SG_ 2147484624 VMCU_BB2_34S_FCS 7;
BA_ "Platform_VMCU1_Sig" SG_ 2147484624 VMCU_BB2_34S_FCS 1;
BA_ "GenSigSendType" SG_ 2147484621 KeyID_KeyAuthEncrypted 1;
BA_ "GenSigMaxLatency" SG_ 2147484621 KeyID_KeyAuthEncrypted 100;
BA_ "Platform_VMCU1_Sig" SG_ 2147484621 KeyID_KeyAuthEncrypted 1;
BA_ "GenSigSendType" SG_ 2147485066 VMCU_BB2_33S_FCS 7;
BA_ "Platform_VMCU1_Sig" SG_ 2147485066 VMCU_BB2_33S_FCS 1;
BA_ "GenSigSendType" SG_ 2147485065 MaintInfoGrp_MaintOption30 1;
BA_ "GenSigStartValue" SG_ 2147485065 MaintInfoGrp_MaintOption30 15;
BA_ "GenSigMaxLatency" SG_ 2147485065 MaintInfoGrp_MaintOption30 3000;
BA_ "Platform_VMCU1_Sig" SG_ 2147485065 MaintInfoGrp_MaintOption30 1;
BA_ "GenSigSendType" SG_ 2147485065 MaintInfoGrp_Unit36 1;
BA_ "GenSigStartValue" SG_ 2147485065 MaintInfoGrp_Unit36 7;
BA_ "GenSigMaxLatency" SG_ 2147485065 MaintInfoGrp_Unit36 3000;
BA_ "Platform_VMCU1_Sig" SG_ 2147485065 MaintInfoGrp_Unit36 1;
BA_ "GenSigSendType" SG_ 2147485065 MaintInfoGrp_MaintOption33 1;
BA_ "GenSigStartValue" SG_ 2147485065 MaintInfoGrp_MaintOption33 15;
BA_ "GenSigMaxLatency" SG_ 2147485065 MaintInfoGrp_MaintOption33 3000;
BA_ "Platform_VMCU1_Sig" SG_ 2147485065 MaintInfoGrp_MaintOption33 1;
BA_ "GenSigSendType" SG_ 2147485065 MaintInfoGrp_ResetAuthorized32 1;
BA_ "GenSigStartValue" SG_ 2147485065 MaintInfoGrp_ResetAuthorized32 3;
BA_ "GenSigMaxLatency" SG_ 2147485065 MaintInfoGrp_ResetAuthorized32 3000;
BA_ "Platform_VMCU1_Sig" SG_ 2147485065 MaintInfoGrp_ResetAuthorized32 1;
BA_ "GenSigSendType" SG_ 2147485065 MaintInfoGrp_Status10 1;
BA_ "GenSigStartValue" SG_ 2147485065 MaintInfoGrp_Status10 7;
BA_ "GenSigMaxLatency" SG_ 2147485065 MaintInfoGrp_Status10 3000;
BA_ "Platform_VMCU1_Sig" SG_ 2147485065 MaintInfoGrp_Status10 1;
BA_ "GenSigSendType" SG_ 2147485065 MaintInfoGrp_Unit2 1;
BA_ "GenSigStartValue" SG_ 2147485065 MaintInfoGrp_Unit2 7;
BA_ "GenSigMaxLatency" SG_ 2147485065 MaintInfoGrp_Unit2 3000;
BA_ "Platform_VMCU1_Sig" SG_ 2147485065 MaintInfoGrp_Unit2 1;
BA_ "GenSigSendType" SG_ 2147485065 MaintInfoGrp_Unit14 1;
BA_ "GenSigStartValue" SG_ 2147485065 MaintInfoGrp_Unit14 7;
BA_ "GenSigMaxLatency" SG_ 2147485065 MaintInfoGrp_Unit14 3000;
BA_ "Platform_VMCU1_Sig" SG_ 2147485065 MaintInfoGrp_Unit14 1;
BA_ "GenSigSendType" SG_ 2147485065 MaintInfoGrp_ResetAuthorized28 1;
BA_ "GenSigStartValue" SG_ 2147485065 MaintInfoGrp_ResetAuthorized28 3;
BA_ "GenSigMaxLatency" SG_ 2147485065 MaintInfoGrp_ResetAuthorized28 3000;
BA_ "Platform_VMCU1_Sig" SG_ 2147485065 MaintInfoGrp_ResetAuthorized28 1;
BA_ "GenSigSendType" SG_ 2147485065 MaintInfoGrp_ResetAuthorized10 1;
BA_ "GenSigStartValue" SG_ 2147485065 MaintInfoGrp_ResetAuthorized10 3;
BA_ "GenSigMaxLatency" SG_ 2147485065 MaintInfoGrp_ResetAuthorized10 3000;
BA_ "Platform_VMCU1_Sig" SG_ 2147485065 MaintInfoGrp_ResetAuthorized10 1;
BA_ "GenSigSendType" SG_ 2147485065 MaintInfoGrp_Status31 1;
BA_ "GenSigStartValue" SG_ 2147485065 MaintInfoGrp_Status31 7;
BA_ "GenSigMaxLatency" SG_ 2147485065 MaintInfoGrp_Status31 3000;
BA_ "Platform_VMCU1_Sig" SG_ 2147485065 MaintInfoGrp_Status31 1;
BA_ "GenSigSendType" SG_ 2147485065 MaintInfoGrp_Unit32 1;
BA_ "GenSigStartValue" SG_ 2147485065 MaintInfoGrp_Unit32 7;
BA_ "GenSigMaxLatency" SG_ 2147485065 MaintInfoGrp_Unit32 3000;
BA_ "Platform_VMCU1_Sig" SG_ 2147485065 MaintInfoGrp_Unit32 1;
BA_ "GenSigSendType" SG_ 2147485065 MaintInfoGrp_Status15 1;
BA_ "GenSigStartValue" SG_ 2147485065 MaintInfoGrp_Status15 7;
BA_ "GenSigMaxLatency" SG_ 2147485065 MaintInfoGrp_Status15 3000;
BA_ "Platform_VMCU1_Sig" SG_ 2147485065 MaintInfoGrp_Status15 1;
BA_ "GenSigSendType" SG_ 2147485065 MaintInfoGrp_Supported19 1;
BA_ "GenSigStartValue" SG_ 2147485065 MaintInfoGrp_Supported19 3;
BA_ "GenSigMaxLatency" SG_ 2147485065 MaintInfoGrp_Supported19 3000;
BA_ "Platform_VMCU1_Sig" SG_ 2147485065 MaintInfoGrp_Supported19 1;
BA_ "GenSigSendType" SG_ 2147485065 MaintInfoGrp_Unit34 1;
BA_ "GenSigStartValue" SG_ 2147485065 MaintInfoGrp_Unit34 7;
BA_ "GenSigMaxLatency" SG_ 2147485065 MaintInfoGrp_Unit34 3000;
BA_ "Platform_VMCU1_Sig" SG_ 2147485065 MaintInfoGrp_Unit34 1;
BA_ "GenSigSendType" SG_ 2147485065 MaintInfoGrp_Data17 1;
BA_ "GenSigStartValue" SG_ 2147485065 MaintInfoGrp_Data17 4294967295;
BA_ "GenSigMaxLatency" SG_ 2147485065 MaintInfoGrp_Data17 3000;
BA_ "Platform_VMCU1_Sig" SG_ 2147485065 MaintInfoGrp_Data17 1;
BA_ "GenSigSendType" SG_ 2147485065 MaintInfoGrp_Unit26 1;
BA_ "GenSigStartValue" SG_ 2147485065 MaintInfoGrp_Unit26 7;
BA_ "GenSigMaxLatency" SG_ 2147485065 MaintInfoGrp_Unit26 3000;
BA_ "Platform_VMCU1_Sig" SG_ 2147485065 MaintInfoGrp_Unit26 1;
BA_ "GenSigSendType" SG_ 2147485065 MaintInfoGrp_Data24 1;
BA_ "GenSigStartValue" SG_ 2147485065 MaintInfoGrp_Data24 4294967295;
BA_ "GenSigMaxLatency" SG_ 2147485065 MaintInfoGrp_Data24 3000;
BA_ "Platform_VMCU1_Sig" SG_ 2147485065 MaintInfoGrp_Data24 1;
BA_ "GenSigSendType" SG_ 2147485065 MaintInfoGrp_ResetAuthorized24 1;
BA_ "GenSigStartValue" SG_ 2147485065 MaintInfoGrp_ResetAuthorized24 3;
BA_ "GenSigMaxLatency" SG_ 2147485065 MaintInfoGrp_ResetAuthorized24 3000;
BA_ "Platform_VMCU1_Sig" SG_ 2147485065 MaintInfoGrp_ResetAuthorized24 1;
BA_ "GenSigSendType" SG_ 2147485065 MaintInfoGrp_ResetAuthorized34 1;
BA_ "GenSigStartValue" SG_ 2147485065 MaintInfoGrp_ResetAuthorized34 3;
BA_ "GenSigMaxLatency" SG_ 2147485065 MaintInfoGrp_ResetAuthorized34 3000;
BA_ "Platform_VMCU1_Sig" SG_ 2147485065 MaintInfoGrp_ResetAuthorized34 1;
BA_ "GenSigSendType" SG_ 2147485065 MaintInfoGrp_Unit28 1;
BA_ "GenSigStartValue" SG_ 2147485065 MaintInfoGrp_Unit28 7;
BA_ "GenSigMaxLatency" SG_ 2147485065 MaintInfoGrp_Unit28 3000;
BA_ "Platform_VMCU1_Sig" SG_ 2147485065 MaintInfoGrp_Unit28 1;
BA_ "GenSigSendType" SG_ 2147485065 MaintInfoGrp_Status26 1;
BA_ "GenSigStartValue" SG_ 2147485065 MaintInfoGrp_Status26 7;
BA_ "GenSigMaxLatency" SG_ 2147485065 MaintInfoGrp_Status26 3000;
BA_ "Platform_VMCU1_Sig" SG_ 2147485065 MaintInfoGrp_Status26 1;
BA_ "GenSigSendType" SG_ 2147485065 MaintInfoGrp_Unit10 1;
BA_ "GenSigStartValue" SG_ 2147485065 MaintInfoGrp_Unit10 7;
BA_ "GenSigMaxLatency" SG_ 2147485065 MaintInfoGrp_Unit10 3000;
BA_ "Platform_VMCU1_Sig" SG_ 2147485065 MaintInfoGrp_Unit10 1;
BA_ "GenSigSendType" SG_ 2147485065 MaintInfoGrp_Data12 1;
BA_ "GenSigStartValue" SG_ 2147485065 MaintInfoGrp_Data12 4294967295;
BA_ "GenSigMaxLatency" SG_ 2147485065 MaintInfoGrp_Data12 3000;
BA_ "Platform_VMCU1_Sig" SG_ 2147485065 MaintInfoGrp_Data12 1;
BA_ "GenSigSendType" SG_ 2147485065 MaintInfoGrp_ResetAuthorized38 1;
BA_ "GenSigStartValue" SG_ 2147485065 MaintInfoGrp_ResetAuthorized38 3;
BA_ "GenSigMaxLatency" SG_ 2147485065 MaintInfoGrp_ResetAuthorized38 3000;
BA_ "Platform_VMCU1_Sig" SG_ 2147485065 MaintInfoGrp_ResetAuthorized38 1;
BA_ "GenSigSendType" SG_ 2147485065 MaintInfoGrp_MaintOption14 1;
BA_ "GenSigStartValue" SG_ 2147485065 MaintInfoGrp_MaintOption14 15;
BA_ "GenSigMaxLatency" SG_ 2147485065 MaintInfoGrp_MaintOption14 3000;
BA_ "Platform_VMCU1_Sig" SG_ 2147485065 MaintInfoGrp_MaintOption14 1;
BA_ "GenSigSendType" SG_ 2147485065 MaintInfoGrp_MaintOption17 1;
BA_ "GenSigStartValue" SG_ 2147485065 MaintInfoGrp_MaintOption17 15;
BA_ "GenSigMaxLatency" SG_ 2147485065 MaintInfoGrp_MaintOption17 3000;
BA_ "Platform_VMCU1_Sig" SG_ 2147485065 MaintInfoGrp_MaintOption17 1;
BA_ "GenSigSendType" SG_ 2147485065 MaintInfoGrp_Status33 1;
BA_ "GenSigStartValue" SG_ 2147485065 MaintInfoGrp_Status33 7;
BA_ "GenSigMaxLatency" SG_ 2147485065 MaintInfoGrp_Status33 3000;
BA_ "Platform_VMCU1_Sig" SG_ 2147485065 MaintInfoGrp_Status33 1;
BA_ "GenSigSendType" SG_ 2147485065 MaintInfoGrp_Unit6 1;
BA_ "GenSigStartValue" SG_ 2147485065 MaintInfoGrp_Unit6 7;
BA_ "GenSigMaxLatency" SG_ 2147485065 MaintInfoGrp_Unit6 3000;
BA_ "Platform_VMCU1_Sig" SG_ 2147485065 MaintInfoGrp_Unit6 1;
BA_ "GenSigSendType" SG_ 2147485065 MaintInfoGrp_Supported7 1;
BA_ "GenSigStartValue" SG_ 2147485065 MaintInfoGrp_Supported7 3;
BA_ "GenSigMaxLatency" SG_ 2147485065 MaintInfoGrp_Supported7 3000;
BA_ "Platform_VMCU1_Sig" SG_ 2147485065 MaintInfoGrp_Supported7 1;
BA_ "GenSigSendType" SG_ 2147485065 MaintInfoGrp_Status7 1;
BA_ "GenSigStartValue" SG_ 2147485065 MaintInfoGrp_Status7 7;
BA_ "GenSigMaxLatency" SG_ 2147485065 MaintInfoGrp_Status7 3000;
BA_ "Platform_VMCU1_Sig" SG_ 2147485065 MaintInfoGrp_Status7 1;
BA_ "GenSigSendType" SG_ 2147485065 MaintInfoGrp_ResetAuthorized2 1;
BA_ "GenSigStartValue" SG_ 2147485065 MaintInfoGrp_ResetAuthorized2 3;
BA_ "GenSigMaxLatency" SG_ 2147485065 MaintInfoGrp_ResetAuthorized2 3000;
BA_ "Platform_VMCU1_Sig" SG_ 2147485065 MaintInfoGrp_ResetAuthorized2 1;
BA_ "GenSigSendType" SG_ 2147485065 MaintInfoGrp_MaintOption27 1;
BA_ "GenSigStartValue" SG_ 2147485065 MaintInfoGrp_MaintOption27 15;
BA_ "GenSigMaxLatency" SG_ 2147485065 MaintInfoGrp_MaintOption27 3000;
BA_ "Platform_VMCU1_Sig" SG_ 2147485065 MaintInfoGrp_MaintOption27 1;
BA_ "GenSigSendType" SG_ 2147485065 MaintInfoGrp_Supported36 1;
BA_ "GenSigStartValue" SG_ 2147485065 MaintInfoGrp_Supported36 3;
BA_ "GenSigMaxLatency" SG_ 2147485065 MaintInfoGrp_Supported36 3000;
BA_ "Platform_VMCU1_Sig" SG_ 2147485065 MaintInfoGrp_Supported36 1;
BA_ "GenSigSendType" SG_ 2147485065 MaintInfoGrp_Unit22 1;
BA_ "GenSigStartValue" SG_ 2147485065 MaintInfoGrp_Unit22 7;
BA_ "GenSigMaxLatency" SG_ 2147485065 MaintInfoGrp_Unit22 3000;
BA_ "Platform_VMCU1_Sig" SG_ 2147485065 MaintInfoGrp_Unit22 1;
BA_ "GenSigSendType" SG_ 2147485065 MaintInfoGrp_Unit18 1;
BA_ "GenSigStartValue" SG_ 2147485065 MaintInfoGrp_Unit18 7;
BA_ "GenSigMaxLatency" SG_ 2147485065 MaintInfoGrp_Unit18 3000;
BA_ "Platform_VMCU1_Sig" SG_ 2147485065 MaintInfoGrp_Unit18 1;
BA_ "GenSigSendType" SG_ 2147485065 MaintInfoGrp_MaintOption28 1;
BA_ "GenSigStartValue" SG_ 2147485065 MaintInfoGrp_MaintOption28 15;
BA_ "GenSigMaxLatency" SG_ 2147485065 MaintInfoGrp_MaintOption28 3000;
BA_ "Platform_VMCU1_Sig" SG_ 2147485065 MaintInfoGrp_MaintOption28 1;
BA_ "GenSigSendType" SG_ 2147485065 MaintInfoGrp_Supported18 1;
BA_ "GenSigStartValue" SG_ 2147485065 MaintInfoGrp_Supported18 3;
BA_ "GenSigMaxLatency" SG_ 2147485065 MaintInfoGrp_Supported18 3000;
BA_ "Platform_VMCU1_Sig" SG_ 2147485065 MaintInfoGrp_Supported18 1;
BA_ "GenSigSendType" SG_ 2147485065 MaintInfoGrp_Status22 1;
BA_ "GenSigStartValue" SG_ 2147485065 MaintInfoGrp_Status22 7;
BA_ "GenSigMaxLatency" SG_ 2147485065 MaintInfoGrp_Status22 3000;
BA_ "Platform_VMCU1_Sig" SG_ 2147485065 MaintInfoGrp_Status22 1;
BA_ "GenSigSendType" SG_ 2147485065 MaintInfoGrp_Status30 1;
BA_ "GenSigStartValue" SG_ 2147485065 MaintInfoGrp_Status30 7;
BA_ "GenSigMaxLatency" SG_ 2147485065 MaintInfoGrp_Status30 3000;
BA_ "Platform_VMCU1_Sig" SG_ 2147485065 MaintInfoGrp_Status30 1;
BA_ "GenSigSendType" SG_ 2147485065 MaintInfoGrp_Status20 1;
BA_ "GenSigStartValue" SG_ 2147485065 MaintInfoGrp_Status20 7;
BA_ "GenSigMaxLatency" SG_ 2147485065 MaintInfoGrp_Status20 3000;
BA_ "Platform_VMCU1_Sig" SG_ 2147485065 MaintInfoGrp_Status20 1;
BA_ "GenSigSendType" SG_ 2147485065 MaintInfoGrp_Status38 1;
BA_ "GenSigStartValue" SG_ 2147485065 MaintInfoGrp_Status38 7;
BA_ "GenSigMaxLatency" SG_ 2147485065 MaintInfoGrp_Status38 3000;
BA_ "Platform_VMCU1_Sig" SG_ 2147485065 MaintInfoGrp_Status38 1;
BA_ "GenSigSendType" SG_ 2147485065 MaintInfoGrp_Data38 1;
BA_ "GenSigStartValue" SG_ 2147485065 MaintInfoGrp_Data38 4294967295;
BA_ "GenSigMaxLatency" SG_ 2147485065 MaintInfoGrp_Data38 3000;
BA_ "Platform_VMCU1_Sig" SG_ 2147485065 MaintInfoGrp_Data38 1;
BA_ "GenSigSendType" SG_ 2147485065 MaintInfoGrp_ResetAuthorized7 1;
BA_ "GenSigStartValue" SG_ 2147485065 MaintInfoGrp_ResetAuthorized7 3;
BA_ "GenSigMaxLatency" SG_ 2147485065 MaintInfoGrp_ResetAuthorized7 3000;
BA_ "Platform_VMCU1_Sig" SG_ 2147485065 MaintInfoGrp_ResetAuthorized7 1;
BA_ "GenSigSendType" SG_ 2147485065 MaintInfoGrp_Data19 1;
BA_ "GenSigStartValue" SG_ 2147485065 MaintInfoGrp_Data19 4294967295;
BA_ "GenSigMaxLatency" SG_ 2147485065 MaintInfoGrp_Data19 3000;
BA_ "Platform_VMCU1_Sig" SG_ 2147485065 MaintInfoGrp_Data19 1;
BA_ "GenSigSendType" SG_ 2147485065 MaintInfoGrp_ResetAuthorized19 1;
BA_ "GenSigStartValue" SG_ 2147485065 MaintInfoGrp_ResetAuthorized19 3;
BA_ "GenSigMaxLatency" SG_ 2147485065 MaintInfoGrp_ResetAuthorized19 3000;
BA_ "Platform_VMCU1_Sig" SG_ 2147485065 MaintInfoGrp_ResetAuthorized19 1;
BA_ "GenSigSendType" SG_ 2147485065 MaintInfoGrp_ResetAuthorized12 1;
BA_ "GenSigStartValue" SG_ 2147485065 MaintInfoGrp_ResetAuthorized12 3;
BA_ "GenSigMaxLatency" SG_ 2147485065 MaintInfoGrp_ResetAuthorized12 3000;
BA_ "Platform_VMCU1_Sig" SG_ 2147485065 MaintInfoGrp_ResetAuthorized12 1;
BA_ "GenSigSendType" SG_ 2147485065 MaintInfoGrp_MaintOption8 1;
BA_ "GenSigStartValue" SG_ 2147485065 MaintInfoGrp_MaintOption8 15;
BA_ "GenSigMaxLatency" SG_ 2147485065 MaintInfoGrp_MaintOption8 3000;
BA_ "Platform_VMCU1_Sig" SG_ 2147485065 MaintInfoGrp_MaintOption8 1;
BA_ "GenSigSendType" SG_ 2147485065 MaintInfoGrp_MaintOption9 1;
BA_ "GenSigStartValue" SG_ 2147485065 MaintInfoGrp_MaintOption9 15;
BA_ "GenSigMaxLatency" SG_ 2147485065 MaintInfoGrp_MaintOption9 3000;
BA_ "Platform_VMCU1_Sig" SG_ 2147485065 MaintInfoGrp_MaintOption9 1;
BA_ "GenSigSendType" SG_ 2147485065 MaintInfoGrp_ResetAuthorized13 1;
BA_ "GenSigStartValue" SG_ 2147485065 MaintInfoGrp_ResetAuthorized13 3;
BA_ "GenSigMaxLatency" SG_ 2147485065 MaintInfoGrp_ResetAuthorized13 3000;
BA_ "Platform_VMCU1_Sig" SG_ 2147485065 MaintInfoGrp_ResetAuthorized13 1;
BA_ "GenSigSendType" SG_ 2147485065 MaintInfoGrp_Unit31 1;
BA_ "GenSigStartValue" SG_ 2147485065 MaintInfoGrp_Unit31 7;
BA_ "GenSigMaxLatency" SG_ 2147485065 MaintInfoGrp_Unit31 3000;
BA_ "Platform_VMCU1_Sig" SG_ 2147485065 MaintInfoGrp_Unit31 1;
BA_ "GenSigSendType" SG_ 2147485065 MaintInfoGrp_Status2 1;
BA_ "GenSigStartValue" SG_ 2147485065 MaintInfoGrp_Status2 7;
BA_ "GenSigMaxLatency" SG_ 2147485065 MaintInfoGrp_Status2 3000;
BA_ "Platform_VMCU1_Sig" SG_ 2147485065 MaintInfoGrp_Status2 1;
BA_ "GenSigSendType" SG_ 2147485065 MaintInfoGrp_ResetAuthorized5 1;
BA_ "GenSigStartValue" SG_ 2147485065 MaintInfoGrp_ResetAuthorized5 3;
BA_ "GenSigMaxLatency" SG_ 2147485065 MaintInfoGrp_ResetAuthorized5 3000;
BA_ "Platform_VMCU1_Sig" SG_ 2147485065 MaintInfoGrp_ResetAuthorized5 1;
BA_ "GenSigSendType" SG_ 2147485065 MaintInfoGrp_Supported33 1;
BA_ "GenSigStartValue" SG_ 2147485065 MaintInfoGrp_Supported33 3;
BA_ "GenSigMaxLatency" SG_ 2147485065 MaintInfoGrp_Supported33 3000;
BA_ "Platform_VMCU1_Sig" SG_ 2147485065 MaintInfoGrp_Supported33 1;
BA_ "GenSigSendType" SG_ 2147485065 MaintInfoGrp_Unit7 1;
BA_ "GenSigStartValue" SG_ 2147485065 MaintInfoGrp_Unit7 7;
BA_ "GenSigMaxLatency" SG_ 2147485065 MaintInfoGrp_Unit7 3000;
BA_ "Platform_VMCU1_Sig" SG_ 2147485065 MaintInfoGrp_Unit7 1;
BA_ "GenSigSendType" SG_ 2147485065 MaintInfoGrp_Supported34 1;
BA_ "GenSigStartValue" SG_ 2147485065 MaintInfoGrp_Supported34 3;
BA_ "GenSigMaxLatency" SG_ 2147485065 MaintInfoGrp_Supported34 3000;
BA_ "Platform_VMCU1_Sig" SG_ 2147485065 MaintInfoGrp_Supported34 1;
BA_ "GenSigSendType" SG_ 2147485065 MaintInfoGrp_Data16 1;
BA_ "GenSigStartValue" SG_ 2147485065 MaintInfoGrp_Data16 4294967295;
BA_ "GenSigMaxLatency" SG_ 2147485065 MaintInfoGrp_Data16 3000;
BA_ "Platform_VMCU1_Sig" SG_ 2147485065 MaintInfoGrp_Data16 1;
BA_ "GenSigSendType" SG_ 2147485065 MaintInfoGrp_Unit19 1;
BA_ "GenSigStartValue" SG_ 2147485065 MaintInfoGrp_Unit19 7;
BA_ "GenSigMaxLatency" SG_ 2147485065 MaintInfoGrp_Unit19 3000;
BA_ "Platform_VMCU1_Sig" SG_ 2147485065 MaintInfoGrp_Unit19 1;
BA_ "GenSigSendType" SG_ 2147485065 MaintInfoGrp_ResetAuthorized21 1;
BA_ "GenSigStartValue" SG_ 2147485065 MaintInfoGrp_ResetAuthorized21 3;
BA_ "GenSigMaxLatency" SG_ 2147485065 MaintInfoGrp_ResetAuthorized21 3000;
BA_ "Platform_VMCU1_Sig" SG_ 2147485065 MaintInfoGrp_ResetAuthorized21 1;
BA_ "GenSigSendType" SG_ 2147485065 MaintInfoGrp_ResetAuthorized31 1;
BA_ "GenSigStartValue" SG_ 2147485065 MaintInfoGrp_ResetAuthorized31 3;
BA_ "GenSigMaxLatency" SG_ 2147485065 MaintInfoGrp_ResetAuthorized31 3000;
BA_ "Platform_VMCU1_Sig" SG_ 2147485065 MaintInfoGrp_ResetAuthorized31 1;
BA_ "GenSigSendType" SG_ 2147485065 MaintInfoGrp_Data28 1;
BA_ "GenSigStartValue" SG_ 2147485065 MaintInfoGrp_Data28 4294967295;
BA_ "GenSigMaxLatency" SG_ 2147485065 MaintInfoGrp_Data28 3000;
BA_ "Platform_VMCU1_Sig" SG_ 2147485065 MaintInfoGrp_Data28 1;
BA_ "GenSigSendType" SG_ 2147485065 MaintInfoGrp_ResetAuthorized3 1;
BA_ "GenSigStartValue" SG_ 2147485065 MaintInfoGrp_ResetAuthorized3 3;
BA_ "GenSigMaxLatency" SG_ 2147485065 MaintInfoGrp_ResetAuthorized3 3000;
BA_ "Platform_VMCU1_Sig" SG_ 2147485065 MaintInfoGrp_ResetAuthorized3 1;
BA_ "GenSigSendType" SG_ 2147485065 MaintInfoGrp_MaintOption34 1;
BA_ "GenSigStartValue" SG_ 2147485065 MaintInfoGrp_MaintOption34 15;
BA_ "GenSigMaxLatency" SG_ 2147485065 MaintInfoGrp_MaintOption34 3000;
BA_ "Platform_VMCU1_Sig" SG_ 2147485065 MaintInfoGrp_MaintOption34 1;
BA_ "GenSigSendType" SG_ 2147485065 MaintInfoGrp_Status21 1;
BA_ "GenSigStartValue" SG_ 2147485065 MaintInfoGrp_Status21 7;
BA_ "GenSigMaxLatency" SG_ 2147485065 MaintInfoGrp_Status21 3000;
BA_ "Platform_VMCU1_Sig" SG_ 2147485065 MaintInfoGrp_Status21 1;
BA_ "GenSigSendType" SG_ 2147485065 MaintInfoGrp_Unit21 1;
BA_ "GenSigStartValue" SG_ 2147485065 MaintInfoGrp_Unit21 7;
BA_ "GenSigMaxLatency" SG_ 2147485065 MaintInfoGrp_Unit21 3000;
BA_ "Platform_VMCU1_Sig" SG_ 2147485065 MaintInfoGrp_Unit21 1;
BA_ "GenSigSendType" SG_ 2147485065 MaintInfoGrp_MaintOption24 1;
BA_ "GenSigStartValue" SG_ 2147485065 MaintInfoGrp_MaintOption24 15;
BA_ "GenSigMaxLatency" SG_ 2147485065 MaintInfoGrp_MaintOption24 3000;
BA_ "Platform_VMCU1_Sig" SG_ 2147485065 MaintInfoGrp_MaintOption24 1;
BA_ "GenSigSendType" SG_ 2147485065 MaintInfoGrp_Data26 1;
BA_ "GenSigStartValue" SG_ 2147485065 MaintInfoGrp_Data26 4294967295;
BA_ "GenSigMaxLatency" SG_ 2147485065 MaintInfoGrp_Data26 3000;
BA_ "Platform_VMCU1_Sig" SG_ 2147485065 MaintInfoGrp_Data26 1;
BA_ "GenSigSendType" SG_ 2147485065 MaintInfoGrp_Data37 1;
BA_ "GenSigStartValue" SG_ 2147485065 MaintInfoGrp_Data37 4294967295;
BA_ "GenSigMaxLatency" SG_ 2147485065 MaintInfoGrp_Data37 3000;
BA_ "Platform_VMCU1_Sig" SG_ 2147485065 MaintInfoGrp_Data37 1;
BA_ "GenSigSendType" SG_ 2147485065 MaintInfoGrp_Data35 1;
BA_ "GenSigStartValue" SG_ 2147485065 MaintInfoGrp_Data35 4294967295;
BA_ "GenSigMaxLatency" SG_ 2147485065 MaintInfoGrp_Data35 3000;
BA_ "Platform_VMCU1_Sig" SG_ 2147485065 MaintInfoGrp_Data35 1;
BA_ "GenSigSendType" SG_ 2147485065 MaintInfoGrp_Supported17 1;
BA_ "GenSigStartValue" SG_ 2147485065 MaintInfoGrp_Supported17 3;
BA_ "GenSigMaxLatency" SG_ 2147485065 MaintInfoGrp_Supported17 3000;
BA_ "Platform_VMCU1_Sig" SG_ 2147485065 MaintInfoGrp_Supported17 1;
BA_ "GenSigSendType" SG_ 2147485065 MaintInfoGrp_ResetAuthorized17 1;
BA_ "GenSigStartValue" SG_ 2147485065 MaintInfoGrp_ResetAuthorized17 3;
BA_ "GenSigMaxLatency" SG_ 2147485065 MaintInfoGrp_ResetAuthorized17 3000;
BA_ "Platform_VMCU1_Sig" SG_ 2147485065 MaintInfoGrp_ResetAuthorized17 1;
BA_ "GenSigSendType" SG_ 2147485065 MaintInfoGrp_Unit25 1;
BA_ "GenSigStartValue" SG_ 2147485065 MaintInfoGrp_Unit25 7;
BA_ "GenSigMaxLatency" SG_ 2147485065 MaintInfoGrp_Unit25 3000;
BA_ "Platform_VMCU1_Sig" SG_ 2147485065 MaintInfoGrp_Unit25 1;
BA_ "GenSigSendType" SG_ 2147485065 MaintInfoGrp_Unit37 1;
BA_ "GenSigStartValue" SG_ 2147485065 MaintInfoGrp_Unit37 7;
BA_ "GenSigMaxLatency" SG_ 2147485065 MaintInfoGrp_Unit37 3000;
BA_ "Platform_VMCU1_Sig" SG_ 2147485065 MaintInfoGrp_Unit37 1;
BA_ "GenSigSendType" SG_ 2147485065 MaintInfoGrp_MaintOption2 1;
BA_ "GenSigStartValue" SG_ 2147485065 MaintInfoGrp_MaintOption2 15;
BA_ "GenSigMaxLatency" SG_ 2147485065 MaintInfoGrp_MaintOption2 3000;
BA_ "Platform_VMCU1_Sig" SG_ 2147485065 MaintInfoGrp_MaintOption2 1;
BA_ "GenSigSendType" SG_ 2147485065 MaintInfoGrp_Supported21 1;
BA_ "GenSigStartValue" SG_ 2147485065 MaintInfoGrp_Supported21 3;
BA_ "GenSigMaxLatency" SG_ 2147485065 MaintInfoGrp_Supported21 3000;
BA_ "Platform_VMCU1_Sig" SG_ 2147485065 MaintInfoGrp_Supported21 1;
BA_ "GenSigSendType" SG_ 2147485065 MaintInfoGrp_ResetAuthorized16 1;
BA_ "GenSigStartValue" SG_ 2147485065 MaintInfoGrp_ResetAuthorized16 3;
BA_ "GenSigMaxLatency" SG_ 2147485065 MaintInfoGrp_ResetAuthorized16 3000;
BA_ "Platform_VMCU1_Sig" SG_ 2147485065 MaintInfoGrp_ResetAuthorized16 1;
BA_ "GenSigSendType" SG_ 2147485065 MaintInfoGrp_Supported15 1;
BA_ "GenSigStartValue" SG_ 2147485065 MaintInfoGrp_Supported15 3;
BA_ "GenSigMaxLatency" SG_ 2147485065 MaintInfoGrp_Supported15 3000;
BA_ "Platform_VMCU1_Sig" SG_ 2147485065 MaintInfoGrp_Supported15 1;
BA_ "GenSigSendType" SG_ 2147485065 MaintInfoGrp_ResetAuthorized9 1;
BA_ "GenSigStartValue" SG_ 2147485065 MaintInfoGrp_ResetAuthorized9 3;
BA_ "GenSigMaxLatency" SG_ 2147485065 MaintInfoGrp_ResetAuthorized9 3000;
BA_ "Platform_VMCU1_Sig" SG_ 2147485065 MaintInfoGrp_ResetAuthorized9 1;
BA_ "GenSigSendType" SG_ 2147485065 MaintInfoGrp_MaintOption18 1;
BA_ "GenSigStartValue" SG_ 2147485065 MaintInfoGrp_MaintOption18 15;
BA_ "GenSigMaxLatency" SG_ 2147485065 MaintInfoGrp_MaintOption18 3000;
BA_ "Platform_VMCU1_Sig" SG_ 2147485065 MaintInfoGrp_MaintOption18 1;
BA_ "GenSigSendType" SG_ 2147485065 MaintInfoGrp_Data14 1;
BA_ "GenSigStartValue" SG_ 2147485065 MaintInfoGrp_Data14 4294967295;
BA_ "GenSigMaxLatency" SG_ 2147485065 MaintInfoGrp_Data14 3000;
BA_ "Platform_VMCU1_Sig" SG_ 2147485065 MaintInfoGrp_Data14 1;
BA_ "GenSigSendType" SG_ 2147485065 MaintInfoGrp_Data8 1;
BA_ "GenSigStartValue" SG_ 2147485065 MaintInfoGrp_Data8 4294967295;
BA_ "GenSigMaxLatency" SG_ 2147485065 MaintInfoGrp_Data8 3000;
BA_ "Platform_VMCU1_Sig" SG_ 2147485065 MaintInfoGrp_Data8 1;
BA_ "GenSigSendType" SG_ 2147485065 MaintInfoGrp_Supported29 1;
BA_ "GenSigStartValue" SG_ 2147485065 MaintInfoGrp_Supported29 3;
BA_ "GenSigMaxLatency" SG_ 2147485065 MaintInfoGrp_Supported29 3000;
BA_ "Platform_VMCU1_Sig" SG_ 2147485065 MaintInfoGrp_Supported29 1;
BA_ "GenSigSendType" SG_ 2147485065 MaintInfoGrp_ResetAuthorized39 1;
BA_ "GenSigStartValue" SG_ 2147485065 MaintInfoGrp_ResetAuthorized39 3;
BA_ "GenSigMaxLatency" SG_ 2147485065 MaintInfoGrp_ResetAuthorized39 3000;
BA_ "Platform_VMCU1_Sig" SG_ 2147485065 MaintInfoGrp_ResetAuthorized39 1;
BA_ "GenSigSendType" SG_ 2147485065 MaintInfoGrp_Supported32 1;
BA_ "GenSigStartValue" SG_ 2147485065 MaintInfoGrp_Supported32 3;
BA_ "GenSigMaxLatency" SG_ 2147485065 MaintInfoGrp_Supported32 3000;
BA_ "Platform_VMCU1_Sig" SG_ 2147485065 MaintInfoGrp_Supported32 1;
BA_ "GenSigSendType" SG_ 2147485065 MaintInfoGrp_Data33 1;
BA_ "GenSigStartValue" SG_ 2147485065 MaintInfoGrp_Data33 4294967295;
BA_ "GenSigMaxLatency" SG_ 2147485065 MaintInfoGrp_Data33 3000;
BA_ "Platform_VMCU1_Sig" SG_ 2147485065 MaintInfoGrp_Data33 1;
BA_ "GenSigSendType" SG_ 2147485065 MaintInfoGrp_ResetAuthorized35 1;
BA_ "GenSigStartValue" SG_ 2147485065 MaintInfoGrp_ResetAuthorized35 3;
BA_ "GenSigMaxLatency" SG_ 2147485065 MaintInfoGrp_ResetAuthorized35 3000;
BA_ "Platform_VMCU1_Sig" SG_ 2147485065 MaintInfoGrp_ResetAuthorized35 1;
BA_ "GenSigSendType" SG_ 2147485065 MaintInfoGrp_Data30 1;
BA_ "GenSigStartValue" SG_ 2147485065 MaintInfoGrp_Data30 4294967295;
BA_ "GenSigMaxLatency" SG_ 2147485065 MaintInfoGrp_Data30 3000;
BA_ "Platform_VMCU1_Sig" SG_ 2147485065 MaintInfoGrp_Data30 1;
BA_ "GenSigSendType" SG_ 2147485065 MaintInfoGrp_ResetAuthorized29 1;
BA_ "GenSigStartValue" SG_ 2147485065 MaintInfoGrp_ResetAuthorized29 3;
BA_ "GenSigMaxLatency" SG_ 2147485065 MaintInfoGrp_ResetAuthorized29 3000;
BA_ "Platform_VMCU1_Sig" SG_ 2147485065 MaintInfoGrp_ResetAuthorized29 1;
BA_ "GenSigSendType" SG_ 2147485065 MaintInfoGrp_Supported35 1;
BA_ "GenSigStartValue" SG_ 2147485065 MaintInfoGrp_Supported35 3;
BA_ "GenSigMaxLatency" SG_ 2147485065 MaintInfoGrp_Supported35 3000;
BA_ "Platform_VMCU1_Sig" SG_ 2147485065 MaintInfoGrp_Supported35 1;
BA_ "GenSigSendType" SG_ 2147485065 MaintInfoGrp_ResetAuthorized4 1;
BA_ "GenSigStartValue" SG_ 2147485065 MaintInfoGrp_ResetAuthorized4 3;
BA_ "GenSigMaxLatency" SG_ 2147485065 MaintInfoGrp_ResetAuthorized4 3000;
BA_ "Platform_VMCU1_Sig" SG_ 2147485065 MaintInfoGrp_ResetAuthorized4 1;
BA_ "GenSigSendType" SG_ 2147485065 MaintInfoGrp_Data10 1;
BA_ "GenSigStartValue" SG_ 2147485065 MaintInfoGrp_Data10 4294967295;
BA_ "GenSigMaxLatency" SG_ 2147485065 MaintInfoGrp_Data10 3000;
BA_ "Platform_VMCU1_Sig" SG_ 2147485065 MaintInfoGrp_Data10 1;
BA_ "GenSigSendType" SG_ 2147485065 MaintInfoGrp_Data9 1;
BA_ "GenSigStartValue" SG_ 2147485065 MaintInfoGrp_Data9 4294967295;
BA_ "GenSigMaxLatency" SG_ 2147485065 MaintInfoGrp_Data9 3000;
BA_ "Platform_VMCU1_Sig" SG_ 2147485065 MaintInfoGrp_Data9 1;
BA_ "GenSigSendType" SG_ 2147485065 MaintInfoGrp_Unit1 1;
BA_ "GenSigStartValue" SG_ 2147485065 MaintInfoGrp_Unit1 7;
BA_ "GenSigMaxLatency" SG_ 2147485065 MaintInfoGrp_Unit1 3000;
BA_ "Platform_VMCU1_Sig" SG_ 2147485065 MaintInfoGrp_Unit1 1;
BA_ "GenSigSendType" SG_ 2147485065 MaintInfoGrp_MaintOption7 1;
BA_ "GenSigStartValue" SG_ 2147485065 MaintInfoGrp_MaintOption7 15;
BA_ "GenSigMaxLatency" SG_ 2147485065 MaintInfoGrp_MaintOption7 3000;
BA_ "Platform_VMCU1_Sig" SG_ 2147485065 MaintInfoGrp_MaintOption7 1;
BA_ "GenSigSendType" SG_ 2147485065 MaintInfoGrp_Supported24 1;
BA_ "GenSigStartValue" SG_ 2147485065 MaintInfoGrp_Supported24 3;
BA_ "GenSigMaxLatency" SG_ 2147485065 MaintInfoGrp_Supported24 3000;
BA_ "Platform_VMCU1_Sig" SG_ 2147485065 MaintInfoGrp_Supported24 1;
BA_ "GenSigSendType" SG_ 2147485065 MaintInfoGrp_Supported25 1;
BA_ "GenSigStartValue" SG_ 2147485065 MaintInfoGrp_Supported25 3;
BA_ "GenSigMaxLatency" SG_ 2147485065 MaintInfoGrp_Supported25 3000;
BA_ "Platform_VMCU1_Sig" SG_ 2147485065 MaintInfoGrp_Supported25 1;
BA_ "GenSigSendType" SG_ 2147485065 MaintInfoGrp_Unit15 1;
BA_ "GenSigStartValue" SG_ 2147485065 MaintInfoGrp_Unit15 7;
BA_ "GenSigMaxLatency" SG_ 2147485065 MaintInfoGrp_Unit15 3000;
BA_ "Platform_VMCU1_Sig" SG_ 2147485065 MaintInfoGrp_Unit15 1;
BA_ "GenSigSendType" SG_ 2147485065 MaintInfoGrp_Supported1 1;
BA_ "GenSigStartValue" SG_ 2147485065 MaintInfoGrp_Supported1 3;
BA_ "GenSigMaxLatency" SG_ 2147485065 MaintInfoGrp_Supported1 3000;
BA_ "Platform_VMCU1_Sig" SG_ 2147485065 MaintInfoGrp_Supported1 1;
BA_ "GenSigSendType" SG_ 2147485065 MaintInfoGrp_ResetAuthorized11 1;
BA_ "GenSigStartValue" SG_ 2147485065 MaintInfoGrp_ResetAuthorized11 3;
BA_ "GenSigMaxLatency" SG_ 2147485065 MaintInfoGrp_ResetAuthorized11 3000;
BA_ "Platform_VMCU1_Sig" SG_ 2147485065 MaintInfoGrp_ResetAuthorized11 1;
BA_ "GenSigSendType" SG_ 2147485065 MaintInfoGrp_Supported13 1;
BA_ "GenSigStartValue" SG_ 2147485065 MaintInfoGrp_Supported13 3;
BA_ "GenSigMaxLatency" SG_ 2147485065 MaintInfoGrp_Supported13 3000;
BA_ "Platform_VMCU1_Sig" SG_ 2147485065 MaintInfoGrp_Supported13 1;
BA_ "GenSigSendType" SG_ 2147485065 MaintInfoGrp_Supported10 1;
BA_ "GenSigStartValue" SG_ 2147485065 MaintInfoGrp_Supported10 3;
BA_ "GenSigMaxLatency" SG_ 2147485065 MaintInfoGrp_Supported10 3000;
BA_ "Platform_VMCU1_Sig" SG_ 2147485065 MaintInfoGrp_Supported10 1;
BA_ "GenSigSendType" SG_ 2147485065 MaintInfoGrp_Data2 1;
BA_ "GenSigStartValue" SG_ 2147485065 MaintInfoGrp_Data2 4294967295;
BA_ "GenSigMaxLatency" SG_ 2147485065 MaintInfoGrp_Data2 3000;
BA_ "Platform_VMCU1_Sig" SG_ 2147485065 MaintInfoGrp_Data2 1;
BA_ "GenSigSendType" SG_ 2147485065 MaintInfoGrp_Unit16 1;
BA_ "GenSigStartValue" SG_ 2147485065 MaintInfoGrp_Unit16 7;
BA_ "GenSigMaxLatency" SG_ 2147485065 MaintInfoGrp_Unit16 3000;
BA_ "Platform_VMCU1_Sig" SG_ 2147485065 MaintInfoGrp_Unit16 1;
BA_ "GenSigSendType" SG_ 2147485065 MaintInfoGrp_MaintOption35 1;
BA_ "GenSigStartValue" SG_ 2147485065 MaintInfoGrp_MaintOption35 15;
BA_ "GenSigMaxLatency" SG_ 2147485065 MaintInfoGrp_MaintOption35 3000;
BA_ "Platform_VMCU1_Sig" SG_ 2147485065 MaintInfoGrp_MaintOption35 1;
BA_ "GenSigSendType" SG_ 2147485065 MaintInfoGrp_MaintOption22 1;
BA_ "GenSigStartValue" SG_ 2147485065 MaintInfoGrp_MaintOption22 15;
BA_ "GenSigMaxLatency" SG_ 2147485065 MaintInfoGrp_MaintOption22 3000;
BA_ "Platform_VMCU1_Sig" SG_ 2147485065 MaintInfoGrp_MaintOption22 1;
BA_ "GenSigSendType" SG_ 2147485065 MaintInfoGrp_MaintOption12 1;
BA_ "GenSigStartValue" SG_ 2147485065 MaintInfoGrp_MaintOption12 15;
BA_ "GenSigMaxLatency" SG_ 2147485065 MaintInfoGrp_MaintOption12 3000;
BA_ "Platform_VMCU1_Sig" SG_ 2147485065 MaintInfoGrp_MaintOption12 1;
BA_ "GenSigSendType" SG_ 2147485065 MaintInfoGrp_Supported9 1;
BA_ "GenSigStartValue" SG_ 2147485065 MaintInfoGrp_Supported9 3;
BA_ "GenSigMaxLatency" SG_ 2147485065 MaintInfoGrp_Supported9 3000;
BA_ "Platform_VMCU1_Sig" SG_ 2147485065 MaintInfoGrp_Supported9 1;
BA_ "GenSigSendType" SG_ 2147485065 MaintInfoGrp_Supported31 1;
BA_ "GenSigStartValue" SG_ 2147485065 MaintInfoGrp_Supported31 3;
BA_ "GenSigMaxLatency" SG_ 2147485065 MaintInfoGrp_Supported31 3000;
BA_ "Platform_VMCU1_Sig" SG_ 2147485065 MaintInfoGrp_Supported31 1;
BA_ "GenSigSendType" SG_ 2147485065 MaintInfoGrp_MaintOption37 1;
BA_ "GenSigStartValue" SG_ 2147485065 MaintInfoGrp_MaintOption37 15;
BA_ "GenSigMaxLatency" SG_ 2147485065 MaintInfoGrp_MaintOption37 3000;
BA_ "Platform_VMCU1_Sig" SG_ 2147485065 MaintInfoGrp_MaintOption37 1;
BA_ "GenSigSendType" SG_ 2147485065 MaintInfoGrp_MaintOption13 1;
BA_ "GenSigStartValue" SG_ 2147485065 MaintInfoGrp_MaintOption13 15;
BA_ "GenSigMaxLatency" SG_ 2147485065 MaintInfoGrp_MaintOption13 3000;
BA_ "Platform_VMCU1_Sig" SG_ 2147485065 MaintInfoGrp_MaintOption13 1;
BA_ "GenSigSendType" SG_ 2147485065 MaintInfoGrp_ResetAuthorized22 1;
BA_ "GenSigStartValue" SG_ 2147485065 MaintInfoGrp_ResetAuthorized22 3;
BA_ "GenSigMaxLatency" SG_ 2147485065 MaintInfoGrp_ResetAuthorized22 3000;
BA_ "Platform_VMCU1_Sig" SG_ 2147485065 MaintInfoGrp_ResetAuthorized22 1;
BA_ "GenSigSendType" SG_ 2147485065 MaintInfoGrp_Status14 1;
BA_ "GenSigStartValue" SG_ 2147485065 MaintInfoGrp_Status14 7;
BA_ "GenSigMaxLatency" SG_ 2147485065 MaintInfoGrp_Status14 3000;
BA_ "Platform_VMCU1_Sig" SG_ 2147485065 MaintInfoGrp_Status14 1;
BA_ "GenSigSendType" SG_ 2147485065 MaintInfoGrp_Status18 1;
BA_ "GenSigStartValue" SG_ 2147485065 MaintInfoGrp_Status18 7;
BA_ "GenSigMaxLatency" SG_ 2147485065 MaintInfoGrp_Status18 3000;
BA_ "Platform_VMCU1_Sig" SG_ 2147485065 MaintInfoGrp_Status18 1;
BA_ "GenSigSendType" SG_ 2147485065 MaintInfoGrp_Unit17 1;
BA_ "GenSigStartValue" SG_ 2147485065 MaintInfoGrp_Unit17 7;
BA_ "GenSigMaxLatency" SG_ 2147485065 MaintInfoGrp_Unit17 3000;
BA_ "Platform_VMCU1_Sig" SG_ 2147485065 MaintInfoGrp_Unit17 1;
BA_ "GenSigSendType" SG_ 2147485065 MaintInfoGrp_Unit12 1;
BA_ "GenSigStartValue" SG_ 2147485065 MaintInfoGrp_Unit12 7;
BA_ "GenSigMaxLatency" SG_ 2147485065 MaintInfoGrp_Unit12 3000;
BA_ "Platform_VMCU1_Sig" SG_ 2147485065 MaintInfoGrp_Unit12 1;
BA_ "GenSigSendType" SG_ 2147485065 MaintInfoGrp_Data22 1;
BA_ "GenSigStartValue" SG_ 2147485065 MaintInfoGrp_Data22 4294967295;
BA_ "GenSigMaxLatency" SG_ 2147485065 MaintInfoGrp_Data22 3000;
BA_ "Platform_VMCU1_Sig" SG_ 2147485065 MaintInfoGrp_Data22 1;
BA_ "GenSigSendType" SG_ 2147485065 MaintInfoGrp_Supported27 1;
BA_ "GenSigStartValue" SG_ 2147485065 MaintInfoGrp_Supported27 3;
BA_ "GenSigMaxLatency" SG_ 2147485065 MaintInfoGrp_Supported27 3000;
BA_ "Platform_VMCU1_Sig" SG_ 2147485065 MaintInfoGrp_Supported27 1;
BA_ "GenSigSendType" SG_ 2147485065 MaintInfoGrp_Unit4 1;
BA_ "GenSigStartValue" SG_ 2147485065 MaintInfoGrp_Unit4 7;
BA_ "GenSigMaxLatency" SG_ 2147485065 MaintInfoGrp_Unit4 3000;
BA_ "Platform_VMCU1_Sig" SG_ 2147485065 MaintInfoGrp_Unit4 1;
BA_ "GenSigSendType" SG_ 2147485065 MaintInfoGrp_Data13 1;
BA_ "GenSigStartValue" SG_ 2147485065 MaintInfoGrp_Data13 4294967295;
BA_ "GenSigMaxLatency" SG_ 2147485065 MaintInfoGrp_Data13 3000;
BA_ "Platform_VMCU1_Sig" SG_ 2147485065 MaintInfoGrp_Data13 1;
BA_ "GenSigSendType" SG_ 2147485065 MaintInfoGrp_Status27 1;
BA_ "GenSigStartValue" SG_ 2147485065 MaintInfoGrp_Status27 7;
BA_ "GenSigMaxLatency" SG_ 2147485065 MaintInfoGrp_Status27 3000;
BA_ "Platform_VMCU1_Sig" SG_ 2147485065 MaintInfoGrp_Status27 1;
BA_ "GenSigSendType" SG_ 2147485065 MaintInfoGrp_MaintOption29 1;
BA_ "GenSigStartValue" SG_ 2147485065 MaintInfoGrp_MaintOption29 15;
BA_ "GenSigMaxLatency" SG_ 2147485065 MaintInfoGrp_MaintOption29 3000;
BA_ "Platform_VMCU1_Sig" SG_ 2147485065 MaintInfoGrp_MaintOption29 1;
BA_ "GenSigSendType" SG_ 2147485065 MaintInfoGrp_Unit9 1;
BA_ "GenSigStartValue" SG_ 2147485065 MaintInfoGrp_Unit9 7;
BA_ "GenSigMaxLatency" SG_ 2147485065 MaintInfoGrp_Unit9 3000;
BA_ "Platform_VMCU1_Sig" SG_ 2147485065 MaintInfoGrp_Unit9 1;
BA_ "GenSigSendType" SG_ 2147485065 MaintInfoGrp_Unit13 1;
BA_ "GenSigStartValue" SG_ 2147485065 MaintInfoGrp_Unit13 7;
BA_ "GenSigMaxLatency" SG_ 2147485065 MaintInfoGrp_Unit13 3000;
BA_ "Platform_VMCU1_Sig" SG_ 2147485065 MaintInfoGrp_Unit13 1;
BA_ "GenSigSendType" SG_ 2147485065 MaintInfoGrp_Data25 1;
BA_ "GenSigStartValue" SG_ 2147485065 MaintInfoGrp_Data25 4294967295;
BA_ "GenSigMaxLatency" SG_ 2147485065 MaintInfoGrp_Data25 3000;
BA_ "Platform_VMCU1_Sig" SG_ 2147485065 MaintInfoGrp_Data25 1;
BA_ "GenSigSendType" SG_ 2147485065 MaintInfoGrp_Unit3 1;
BA_ "GenSigStartValue" SG_ 2147485065 MaintInfoGrp_Unit3 7;
BA_ "GenSigMaxLatency" SG_ 2147485065 MaintInfoGrp_Unit3 3000;
BA_ "Platform_VMCU1_Sig" SG_ 2147485065 MaintInfoGrp_Unit3 1;
BA_ "GenSigSendType" SG_ 2147485065 MaintInfoGrp_MaintOption15 1;
BA_ "GenSigStartValue" SG_ 2147485065 MaintInfoGrp_MaintOption15 15;
BA_ "GenSigMaxLatency" SG_ 2147485065 MaintInfoGrp_MaintOption15 3000;
BA_ "Platform_VMCU1_Sig" SG_ 2147485065 MaintInfoGrp_MaintOption15 1;
BA_ "GenSigSendType" SG_ 2147485065 MaintInfoGrp_ResetAuthorized15 1;
BA_ "GenSigStartValue" SG_ 2147485065 MaintInfoGrp_ResetAuthorized15 3;
BA_ "GenSigMaxLatency" SG_ 2147485065 MaintInfoGrp_ResetAuthorized15 3000;
BA_ "Platform_VMCU1_Sig" SG_ 2147485065 MaintInfoGrp_ResetAuthorized15 1;
BA_ "GenSigSendType" SG_ 2147485065 MaintInfoGrp_MaintOption11 1;
BA_ "GenSigStartValue" SG_ 2147485065 MaintInfoGrp_MaintOption11 15;
BA_ "GenSigMaxLatency" SG_ 2147485065 MaintInfoGrp_MaintOption11 3000;
BA_ "Platform_VMCU1_Sig" SG_ 2147485065 MaintInfoGrp_MaintOption11 1;
BA_ "GenSigSendType" SG_ 2147485065 MaintInfoGrp_MaintOption25 1;
BA_ "GenSigStartValue" SG_ 2147485065 MaintInfoGrp_MaintOption25 15;
BA_ "GenSigMaxLatency" SG_ 2147485065 MaintInfoGrp_MaintOption25 3000;
BA_ "Platform_VMCU1_Sig" SG_ 2147485065 MaintInfoGrp_MaintOption25 1;
BA_ "GenSigSendType" SG_ 2147485065 MaintInfoGrp_Supported16 1;
BA_ "GenSigStartValue" SG_ 2147485065 MaintInfoGrp_Supported16 3;
BA_ "GenSigMaxLatency" SG_ 2147485065 MaintInfoGrp_Supported16 3000;
BA_ "Platform_VMCU1_Sig" SG_ 2147485065 MaintInfoGrp_Supported16 1;
BA_ "GenSigSendType" SG_ 2147485065 MaintInfoGrp_Supported23 1;
BA_ "GenSigStartValue" SG_ 2147485065 MaintInfoGrp_Supported23 3;
BA_ "GenSigMaxLatency" SG_ 2147485065 MaintInfoGrp_Supported23 3000;
BA_ "Platform_VMCU1_Sig" SG_ 2147485065 MaintInfoGrp_Supported23 1;
BA_ "GenSigSendType" SG_ 2147485065 MaintInfoGrp_Status13 1;
BA_ "GenSigStartValue" SG_ 2147485065 MaintInfoGrp_Status13 7;
BA_ "GenSigMaxLatency" SG_ 2147485065 MaintInfoGrp_Status13 3000;
BA_ "Platform_VMCU1_Sig" SG_ 2147485065 MaintInfoGrp_Status13 1;
BA_ "GenSigSendType" SG_ 2147485065 MaintInfoGrp_Status17 1;
BA_ "GenSigStartValue" SG_ 2147485065 MaintInfoGrp_Status17 7;
BA_ "GenSigMaxLatency" SG_ 2147485065 MaintInfoGrp_Status17 3000;
BA_ "Platform_VMCU1_Sig" SG_ 2147485065 MaintInfoGrp_Status17 1;
BA_ "GenSigSendType" SG_ 2147485065 MaintInfoGrp_Unit8 1;
BA_ "GenSigStartValue" SG_ 2147485065 MaintInfoGrp_Unit8 7;
BA_ "GenSigMaxLatency" SG_ 2147485065 MaintInfoGrp_Unit8 3000;
BA_ "Platform_VMCU1_Sig" SG_ 2147485065 MaintInfoGrp_Unit8 1;
BA_ "GenSigSendType" SG_ 2147485065 MaintInfoGrp_MaintOption38 1;
BA_ "GenSigStartValue" SG_ 2147485065 MaintInfoGrp_MaintOption38 15;
BA_ "GenSigMaxLatency" SG_ 2147485065 MaintInfoGrp_MaintOption38 3000;
BA_ "Platform_VMCU1_Sig" SG_ 2147485065 MaintInfoGrp_MaintOption38 1;
BA_ "GenSigSendType" SG_ 2147485065 MaintInfoGrp_Data4 1;
BA_ "GenSigStartValue" SG_ 2147485065 MaintInfoGrp_Data4 4294967295;
BA_ "GenSigMaxLatency" SG_ 2147485065 MaintInfoGrp_Data4 3000;
BA_ "Platform_VMCU1_Sig" SG_ 2147485065 MaintInfoGrp_Data4 1;
BA_ "GenSigSendType" SG_ 2147485065 MaintInfoGrp_Supported2 1;
BA_ "GenSigStartValue" SG_ 2147485065 MaintInfoGrp_Supported2 3;
BA_ "GenSigMaxLatency" SG_ 2147485065 MaintInfoGrp_Supported2 3000;
BA_ "Platform_VMCU1_Sig" SG_ 2147485065 MaintInfoGrp_Supported2 1;
BA_ "GenSigSendType" SG_ 2147485065 MaintInfoGrp_ResetAuthorized0 1;
BA_ "GenSigStartValue" SG_ 2147485065 MaintInfoGrp_ResetAuthorized0 3;
BA_ "GenSigMaxLatency" SG_ 2147485065 MaintInfoGrp_ResetAuthorized0 3000;
BA_ "Platform_VMCU1_Sig" SG_ 2147485065 MaintInfoGrp_ResetAuthorized0 1;
BA_ "GenSigSendType" SG_ 2147485065 MaintInfoGrp_Supported5 1;
BA_ "GenSigStartValue" SG_ 2147485065 MaintInfoGrp_Supported5 3;
BA_ "GenSigMaxLatency" SG_ 2147485065 MaintInfoGrp_Supported5 3000;
BA_ "Platform_VMCU1_Sig" SG_ 2147485065 MaintInfoGrp_Supported5 1;
BA_ "GenSigSendType" SG_ 2147485065 MaintInfoGrp_Status6 1;
BA_ "GenSigStartValue" SG_ 2147485065 MaintInfoGrp_Status6 7;
BA_ "GenSigMaxLatency" SG_ 2147485065 MaintInfoGrp_Status6 3000;
BA_ "Platform_VMCU1_Sig" SG_ 2147485065 MaintInfoGrp_Status6 1;
BA_ "GenSigSendType" SG_ 2147485065 MaintInfoGrp_Unit5 1;
BA_ "GenSigStartValue" SG_ 2147485065 MaintInfoGrp_Unit5 7;
BA_ "GenSigMaxLatency" SG_ 2147485065 MaintInfoGrp_Unit5 3000;
BA_ "Platform_VMCU1_Sig" SG_ 2147485065 MaintInfoGrp_Unit5 1;
BA_ "GenSigSendType" SG_ 2147485065 MaintInfoGrp_Data0 1;
BA_ "GenSigStartValue" SG_ 2147485065 MaintInfoGrp_Data0 4294967295;
BA_ "GenSigMaxLatency" SG_ 2147485065 MaintInfoGrp_Data0 3000;
BA_ "Platform_VMCU1_Sig" SG_ 2147485065 MaintInfoGrp_Data0 1;
BA_ "GenSigSendType" SG_ 2147485065 MaintInfoGrp_Data29 1;
BA_ "GenSigStartValue" SG_ 2147485065 MaintInfoGrp_Data29 4294967295;
BA_ "GenSigMaxLatency" SG_ 2147485065 MaintInfoGrp_Data29 3000;
BA_ "Platform_VMCU1_Sig" SG_ 2147485065 MaintInfoGrp_Data29 1;
BA_ "GenSigSendType" SG_ 2147485065 MaintInfoGrp_Supported28 1;
BA_ "GenSigStartValue" SG_ 2147485065 MaintInfoGrp_Supported28 3;
BA_ "GenSigMaxLatency" SG_ 2147485065 MaintInfoGrp_Supported28 3000;
BA_ "Platform_VMCU1_Sig" SG_ 2147485065 MaintInfoGrp_Supported28 1;
BA_ "GenSigSendType" SG_ 2147485065 MaintInfoGrp_Status32 1;
BA_ "GenSigStartValue" SG_ 2147485065 MaintInfoGrp_Status32 7;
BA_ "GenSigMaxLatency" SG_ 2147485065 MaintInfoGrp_Status32 3000;
BA_ "Platform_VMCU1_Sig" SG_ 2147485065 MaintInfoGrp_Status32 1;
BA_ "GenSigSendType" SG_ 2147485065 MaintInfoGrp_MaintOption0 1;
BA_ "GenSigStartValue" SG_ 2147485065 MaintInfoGrp_MaintOption0 15;
BA_ "GenSigMaxLatency" SG_ 2147485065 MaintInfoGrp_MaintOption0 3000;
BA_ "Platform_VMCU1_Sig" SG_ 2147485065 MaintInfoGrp_MaintOption0 1;
BA_ "GenSigSendType" SG_ 2147485065 MaintInfoGrp_ResetAuthorized25 1;
BA_ "GenSigStartValue" SG_ 2147485065 MaintInfoGrp_ResetAuthorized25 3;
BA_ "GenSigMaxLatency" SG_ 2147485065 MaintInfoGrp_ResetAuthorized25 3000;
BA_ "Platform_VMCU1_Sig" SG_ 2147485065 MaintInfoGrp_ResetAuthorized25 1;
BA_ "GenSigSendType" SG_ 2147485065 MaintInfoGrp_MaintOption32 1;
BA_ "GenSigStartValue" SG_ 2147485065 MaintInfoGrp_MaintOption32 15;
BA_ "GenSigMaxLatency" SG_ 2147485065 MaintInfoGrp_MaintOption32 3000;
BA_ "Platform_VMCU1_Sig" SG_ 2147485065 MaintInfoGrp_MaintOption32 1;
BA_ "GenSigSendType" SG_ 2147485065 MaintInfoGrp_Unit11 1;
BA_ "GenSigStartValue" SG_ 2147485065 MaintInfoGrp_Unit11 7;
BA_ "GenSigMaxLatency" SG_ 2147485065 MaintInfoGrp_Unit11 3000;
BA_ "Platform_VMCU1_Sig" SG_ 2147485065 MaintInfoGrp_Unit11 1;
BA_ "GenSigSendType" SG_ 2147485065 MaintInfoGrp_Data39 1;
BA_ "GenSigStartValue" SG_ 2147485065 MaintInfoGrp_Data39 4294967295;
BA_ "GenSigMaxLatency" SG_ 2147485065 MaintInfoGrp_Data39 3000;
BA_ "Platform_VMCU1_Sig" SG_ 2147485065 MaintInfoGrp_Data39 1;
BA_ "GenSigSendType" SG_ 2147485065 MaintInfoGrp_MaintOption4 1;
BA_ "GenSigStartValue" SG_ 2147485065 MaintInfoGrp_MaintOption4 15;
BA_ "GenSigMaxLatency" SG_ 2147485065 MaintInfoGrp_MaintOption4 3000;
BA_ "Platform_VMCU1_Sig" SG_ 2147485065 MaintInfoGrp_MaintOption4 1;
BA_ "GenSigSendType" SG_ 2147485065 MaintInfoGrp_Supported38 1;
BA_ "GenSigStartValue" SG_ 2147485065 MaintInfoGrp_Supported38 3;
BA_ "GenSigMaxLatency" SG_ 2147485065 MaintInfoGrp_Supported38 3000;
BA_ "Platform_VMCU1_Sig" SG_ 2147485065 MaintInfoGrp_Supported38 1;
BA_ "GenSigSendType" SG_ 2147485065 MaintInfoGrp_MaintOption1 1;
BA_ "GenSigStartValue" SG_ 2147485065 MaintInfoGrp_MaintOption1 15;
BA_ "GenSigMaxLatency" SG_ 2147485065 MaintInfoGrp_MaintOption1 3000;
BA_ "Platform_VMCU1_Sig" SG_ 2147485065 MaintInfoGrp_MaintOption1 1;
BA_ "GenSigSendType" SG_ 2147485065 MaintInfoGrp_Supported30 1;
BA_ "GenSigStartValue" SG_ 2147485065 MaintInfoGrp_Supported30 3;
BA_ "GenSigMaxLatency" SG_ 2147485065 MaintInfoGrp_Supported30 3000;
BA_ "Platform_VMCU1_Sig" SG_ 2147485065 MaintInfoGrp_Supported30 1;
BA_ "GenSigSendType" SG_ 2147485065 MaintInfoGrp_ResetAuthorized33 1;
BA_ "GenSigStartValue" SG_ 2147485065 MaintInfoGrp_ResetAuthorized33 3;
BA_ "GenSigMaxLatency" SG_ 2147485065 MaintInfoGrp_ResetAuthorized33 3000;
BA_ "Platform_VMCU1_Sig" SG_ 2147485065 MaintInfoGrp_ResetAuthorized33 1;
BA_ "GenSigSendType" SG_ 2147485065 MaintInfoGrp_Status0 1;
BA_ "GenSigStartValue" SG_ 2147485065 MaintInfoGrp_Status0 7;
BA_ "GenSigMaxLatency" SG_ 2147485065 MaintInfoGrp_Status0 3000;
BA_ "Platform_VMCU1_Sig" SG_ 2147485065 MaintInfoGrp_Status0 1;
BA_ "GenSigSendType" SG_ 2147485065 MaintInfoGrp_ResetAuthorized20 1;
BA_ "GenSigStartValue" SG_ 2147485065 MaintInfoGrp_ResetAuthorized20 3;
BA_ "GenSigMaxLatency" SG_ 2147485065 MaintInfoGrp_ResetAuthorized20 3000;
BA_ "Platform_VMCU1_Sig" SG_ 2147485065 MaintInfoGrp_ResetAuthorized20 1;
BA_ "GenSigSendType" SG_ 2147485065 MaintInfoGrp_Unit33 1;
BA_ "GenSigStartValue" SG_ 2147485065 MaintInfoGrp_Unit33 7;
BA_ "GenSigMaxLatency" SG_ 2147485065 MaintInfoGrp_Unit33 3000;
BA_ "Platform_VMCU1_Sig" SG_ 2147485065 MaintInfoGrp_Unit33 1;
BA_ "GenSigSendType" SG_ 2147485065 MaintInfoGrp_Supported26 1;
BA_ "GenSigStartValue" SG_ 2147485065 MaintInfoGrp_Supported26 3;
BA_ "GenSigMaxLatency" SG_ 2147485065 MaintInfoGrp_Supported26 3000;
BA_ "Platform_VMCU1_Sig" SG_ 2147485065 MaintInfoGrp_Supported26 1;
BA_ "GenSigSendType" SG_ 2147485065 MaintInfoGrp_ResetAuthorized6 1;
BA_ "GenSigStartValue" SG_ 2147485065 MaintInfoGrp_ResetAuthorized6 3;
BA_ "GenSigMaxLatency" SG_ 2147485065 MaintInfoGrp_ResetAuthorized6 3000;
BA_ "Platform_VMCU1_Sig" SG_ 2147485065 MaintInfoGrp_ResetAuthorized6 1;
BA_ "GenSigSendType" SG_ 2147485065 MaintInfoGrp_Data18 1;
BA_ "GenSigStartValue" SG_ 2147485065 MaintInfoGrp_Data18 4294967295;
BA_ "GenSigMaxLatency" SG_ 2147485065 MaintInfoGrp_Data18 3000;
BA_ "Platform_VMCU1_Sig" SG_ 2147485065 MaintInfoGrp_Data18 1;
BA_ "GenSigSendType" SG_ 2147485065 MaintInfoGrp_Status16 1;
BA_ "GenSigStartValue" SG_ 2147485065 MaintInfoGrp_Status16 7;
BA_ "GenSigMaxLatency" SG_ 2147485065 MaintInfoGrp_Status16 3000;
BA_ "Platform_VMCU1_Sig" SG_ 2147485065 MaintInfoGrp_Status16 1;
BA_ "GenSigSendType" SG_ 2147485065 MaintInfoGrp_ResetAuthorized18 1;
BA_ "GenSigStartValue" SG_ 2147485065 MaintInfoGrp_ResetAuthorized18 3;
BA_ "GenSigMaxLatency" SG_ 2147485065 MaintInfoGrp_ResetAuthorized18 3000;
BA_ "Platform_VMCU1_Sig" SG_ 2147485065 MaintInfoGrp_ResetAuthorized18 1;
BA_ "GenSigSendType" SG_ 2147485065 MaintInfoGrp_Status4 1;
BA_ "GenSigStartValue" SG_ 2147485065 MaintInfoGrp_Status4 7;
BA_ "GenSigMaxLatency" SG_ 2147485065 MaintInfoGrp_Status4 3000;
BA_ "Platform_VMCU1_Sig" SG_ 2147485065 MaintInfoGrp_Status4 1;
BA_ "GenSigSendType" SG_ 2147485065 MaintInfoGrp_Data3 1;
BA_ "GenSigStartValue" SG_ 2147485065 MaintInfoGrp_Data3 4294967295;
BA_ "GenSigMaxLatency" SG_ 2147485065 MaintInfoGrp_Data3 3000;
BA_ "Platform_VMCU1_Sig" SG_ 2147485065 MaintInfoGrp_Data3 1;
BA_ "GenSigSendType" SG_ 2147485065 MaintInfoGrp_MaintOption20 1;
BA_ "GenSigStartValue" SG_ 2147485065 MaintInfoGrp_MaintOption20 15;
BA_ "GenSigMaxLatency" SG_ 2147485065 MaintInfoGrp_MaintOption20 3000;
BA_ "Platform_VMCU1_Sig" SG_ 2147485065 MaintInfoGrp_MaintOption20 1;
BA_ "GenSigSendType" SG_ 2147485065 MaintInfoGrp_ResetAuthorized30 1;
BA_ "GenSigStartValue" SG_ 2147485065 MaintInfoGrp_ResetAuthorized30 3;
BA_ "GenSigMaxLatency" SG_ 2147485065 MaintInfoGrp_ResetAuthorized30 3000;
BA_ "Platform_VMCU1_Sig" SG_ 2147485065 MaintInfoGrp_ResetAuthorized30 1;
BA_ "GenSigSendType" SG_ 2147485065 MaintInfoGrp_ResetAuthorized23 1;
BA_ "GenSigStartValue" SG_ 2147485065 MaintInfoGrp_ResetAuthorized23 3;
BA_ "GenSigMaxLatency" SG_ 2147485065 MaintInfoGrp_ResetAuthorized23 3000;
BA_ "Platform_VMCU1_Sig" SG_ 2147485065 MaintInfoGrp_ResetAuthorized23 1;
BA_ "GenSigSendType" SG_ 2147485065 MaintInfoGrp_Unit30 1;
BA_ "GenSigStartValue" SG_ 2147485065 MaintInfoGrp_Unit30 7;
BA_ "GenSigMaxLatency" SG_ 2147485065 MaintInfoGrp_Unit30 3000;
BA_ "Platform_VMCU1_Sig" SG_ 2147485065 MaintInfoGrp_Unit30 1;
BA_ "GenSigSendType" SG_ 2147485065 MaintInfoGrp_Data20 1;
BA_ "GenSigStartValue" SG_ 2147485065 MaintInfoGrp_Data20 4294967295;
BA_ "GenSigMaxLatency" SG_ 2147485065 MaintInfoGrp_Data20 3000;
BA_ "Platform_VMCU1_Sig" SG_ 2147485065 MaintInfoGrp_Data20 1;
BA_ "GenSigSendType" SG_ 2147485065 MaintInfoGrp_MaintOption23 1;
BA_ "GenSigStartValue" SG_ 2147485065 MaintInfoGrp_MaintOption23 15;
BA_ "GenSigMaxLatency" SG_ 2147485065 MaintInfoGrp_MaintOption23 3000;
BA_ "Platform_VMCU1_Sig" SG_ 2147485065 MaintInfoGrp_MaintOption23 1;
BA_ "GenSigSendType" SG_ 2147485065 MaintInfoGrp_Data23 1;
BA_ "GenSigStartValue" SG_ 2147485065 MaintInfoGrp_Data23 4294967295;
BA_ "GenSigMaxLatency" SG_ 2147485065 MaintInfoGrp_Data23 3000;
BA_ "Platform_VMCU1_Sig" SG_ 2147485065 MaintInfoGrp_Data23 1;
BA_ "GenSigSendType" SG_ 2147485065 MaintInfoGrp_Unit20 1;
BA_ "GenSigStartValue" SG_ 2147485065 MaintInfoGrp_Unit20 7;
BA_ "GenSigMaxLatency" SG_ 2147485065 MaintInfoGrp_Unit20 3000;
BA_ "Platform_VMCU1_Sig" SG_ 2147485065 MaintInfoGrp_Unit20 1;
BA_ "GenSigSendType" SG_ 2147485065 MaintInfoGrp_MaintOption10 1;
BA_ "GenSigStartValue" SG_ 2147485065 MaintInfoGrp_MaintOption10 15;
BA_ "GenSigMaxLatency" SG_ 2147485065 MaintInfoGrp_MaintOption10 3000;
BA_ "Platform_VMCU1_Sig" SG_ 2147485065 MaintInfoGrp_MaintOption10 1;
BA_ "GenSigSendType" SG_ 2147485065 MaintInfoGrp_Status39 1;
BA_ "GenSigStartValue" SG_ 2147485065 MaintInfoGrp_Status39 7;
BA_ "GenSigMaxLatency" SG_ 2147485065 MaintInfoGrp_Status39 3000;
BA_ "Platform_VMCU1_Sig" SG_ 2147485065 MaintInfoGrp_Status39 1;
BA_ "GenSigSendType" SG_ 2147485065 MaintInfoGrp_Data21 1;
BA_ "GenSigStartValue" SG_ 2147485065 MaintInfoGrp_Data21 4294967295;
BA_ "GenSigMaxLatency" SG_ 2147485065 MaintInfoGrp_Data21 3000;
BA_ "Platform_VMCU1_Sig" SG_ 2147485065 MaintInfoGrp_Data21 1;
BA_ "GenSigSendType" SG_ 2147485065 MaintInfoGrp_Status3 1;
BA_ "GenSigStartValue" SG_ 2147485065 MaintInfoGrp_Status3 7;
BA_ "GenSigMaxLatency" SG_ 2147485065 MaintInfoGrp_Status3 3000;
BA_ "Platform_VMCU1_Sig" SG_ 2147485065 MaintInfoGrp_Status3 1;
BA_ "GenSigSendType" SG_ 2147485065 MaintInfoGrp_Data5 1;
BA_ "GenSigStartValue" SG_ 2147485065 MaintInfoGrp_Data5 4294967295;
BA_ "GenSigMaxLatency" SG_ 2147485065 MaintInfoGrp_Data5 3000;
BA_ "Platform_VMCU1_Sig" SG_ 2147485065 MaintInfoGrp_Data5 1;
BA_ "GenSigSendType" SG_ 2147485065 MaintInfoGrp_ResetAuthorized26 1;
BA_ "GenSigStartValue" SG_ 2147485065 MaintInfoGrp_ResetAuthorized26 3;
BA_ "GenSigMaxLatency" SG_ 2147485065 MaintInfoGrp_ResetAuthorized26 3000;
BA_ "Platform_VMCU1_Sig" SG_ 2147485065 MaintInfoGrp_ResetAuthorized26 1;
BA_ "GenSigSendType" SG_ 2147485065 MaintInfoGrp_Supported12 1;
BA_ "GenSigStartValue" SG_ 2147485065 MaintInfoGrp_Supported12 3;
BA_ "GenSigMaxLatency" SG_ 2147485065 MaintInfoGrp_Supported12 3000;
BA_ "Platform_VMCU1_Sig" SG_ 2147485065 MaintInfoGrp_Supported12 1;
BA_ "GenSigSendType" SG_ 2147485065 MaintInfoGrp_Data32 1;
BA_ "GenSigStartValue" SG_ 2147485065 MaintInfoGrp_Data32 4294967295;
BA_ "GenSigMaxLatency" SG_ 2147485065 MaintInfoGrp_Data32 3000;
BA_ "Platform_VMCU1_Sig" SG_ 2147485065 MaintInfoGrp_Data32 1;
BA_ "GenSigSendType" SG_ 2147485065 MaintInfoGrp_Status29 1;
BA_ "GenSigStartValue" SG_ 2147485065 MaintInfoGrp_Status29 7;
BA_ "GenSigMaxLatency" SG_ 2147485065 MaintInfoGrp_Status29 3000;
BA_ "Platform_VMCU1_Sig" SG_ 2147485065 MaintInfoGrp_Status29 1;
BA_ "GenSigSendType" SG_ 2147485065 MaintInfoGrp_ResetAuthorized37 1;
BA_ "GenSigStartValue" SG_ 2147485065 MaintInfoGrp_ResetAuthorized37 3;
BA_ "GenSigMaxLatency" SG_ 2147485065 MaintInfoGrp_ResetAuthorized37 3000;
BA_ "Platform_VMCU1_Sig" SG_ 2147485065 MaintInfoGrp_ResetAuthorized37 1;
BA_ "GenSigSendType" SG_ 2147485065 MaintInfoGrp_Status36 1;
BA_ "GenSigStartValue" SG_ 2147485065 MaintInfoGrp_Status36 7;
BA_ "GenSigMaxLatency" SG_ 2147485065 MaintInfoGrp_Status36 3000;
BA_ "Platform_VMCU1_Sig" SG_ 2147485065 MaintInfoGrp_Status36 1;
BA_ "GenSigSendType" SG_ 2147485065 MaintInfoGrp_Supported22 1;
BA_ "GenSigStartValue" SG_ 2147485065 MaintInfoGrp_Supported22 3;
BA_ "GenSigMaxLatency" SG_ 2147485065 MaintInfoGrp_Supported22 3000;
BA_ "Platform_VMCU1_Sig" SG_ 2147485065 MaintInfoGrp_Supported22 1;
BA_ "GenSigSendType" SG_ 2147485065 MaintInfoGrp_Status35 1;
BA_ "GenSigStartValue" SG_ 2147485065 MaintInfoGrp_Status35 7;
BA_ "GenSigMaxLatency" SG_ 2147485065 MaintInfoGrp_Status35 3000;
BA_ "Platform_VMCU1_Sig" SG_ 2147485065 MaintInfoGrp_Status35 1;
BA_ "GenSigSendType" SG_ 2147485065 MaintInfoGrp_Data7 1;
BA_ "GenSigStartValue" SG_ 2147485065 MaintInfoGrp_Data7 4294967295;
BA_ "GenSigMaxLatency" SG_ 2147485065 MaintInfoGrp_Data7 3000;
BA_ "Platform_VMCU1_Sig" SG_ 2147485065 MaintInfoGrp_Data7 1;
BA_ "GenSigSendType" SG_ 2147485065 MaintInfoGrp_MaintOption26 1;
BA_ "GenSigStartValue" SG_ 2147485065 MaintInfoGrp_MaintOption26 15;
BA_ "GenSigMaxLatency" SG_ 2147485065 MaintInfoGrp_MaintOption26 3000;
BA_ "Platform_VMCU1_Sig" SG_ 2147485065 MaintInfoGrp_MaintOption26 1;
BA_ "GenSigSendType" SG_ 2147485065 MaintInfoGrp_Status23 1;
BA_ "GenSigStartValue" SG_ 2147485065 MaintInfoGrp_Status23 7;
BA_ "GenSigMaxLatency" SG_ 2147485065 MaintInfoGrp_Status23 3000;
BA_ "Platform_VMCU1_Sig" SG_ 2147485065 MaintInfoGrp_Status23 1;
BA_ "GenSigSendType" SG_ 2147485065 MaintInfoGrp_Unit35 1;
BA_ "GenSigStartValue" SG_ 2147485065 MaintInfoGrp_Unit35 7;
BA_ "GenSigMaxLatency" SG_ 2147485065 MaintInfoGrp_Unit35 3000;
BA_ "Platform_VMCU1_Sig" SG_ 2147485065 MaintInfoGrp_Unit35 1;
BA_ "GenSigSendType" SG_ 2147485065 MaintInfoGrp_Supported6 1;
BA_ "GenSigStartValue" SG_ 2147485065 MaintInfoGrp_Supported6 3;
BA_ "GenSigMaxLatency" SG_ 2147485065 MaintInfoGrp_Supported6 3000;
BA_ "Platform_VMCU1_Sig" SG_ 2147485065 MaintInfoGrp_Supported6 1;
BA_ "GenSigSendType" SG_ 2147485065 MaintInfoGrp_Data34 1;
BA_ "GenSigStartValue" SG_ 2147485065 MaintInfoGrp_Data34 4294967295;
BA_ "GenSigMaxLatency" SG_ 2147485065 MaintInfoGrp_Data34 3000;
BA_ "Platform_VMCU1_Sig" SG_ 2147485065 MaintInfoGrp_Data34 1;
BA_ "GenSigSendType" SG_ 2147485065 MaintInfoGrp_Unit27 1;
BA_ "GenSigStartValue" SG_ 2147485065 MaintInfoGrp_Unit27 7;
BA_ "GenSigMaxLatency" SG_ 2147485065 MaintInfoGrp_Unit27 3000;
BA_ "Platform_VMCU1_Sig" SG_ 2147485065 MaintInfoGrp_Unit27 1;
BA_ "GenSigSendType" SG_ 2147485065 MaintInfoGrp_MaintOption19 1;
BA_ "GenSigStartValue" SG_ 2147485065 MaintInfoGrp_MaintOption19 15;
BA_ "GenSigMaxLatency" SG_ 2147485065 MaintInfoGrp_MaintOption19 3000;
BA_ "Platform_VMCU1_Sig" SG_ 2147485065 MaintInfoGrp_MaintOption19 1;
BA_ "GenSigSendType" SG_ 2147485065 MaintInfoGrp_ResetAuthorized14 1;
BA_ "GenSigStartValue" SG_ 2147485065 MaintInfoGrp_ResetAuthorized14 3;
BA_ "GenSigMaxLatency" SG_ 2147485065 MaintInfoGrp_ResetAuthorized14 3000;
BA_ "Platform_VMCU1_Sig" SG_ 2147485065 MaintInfoGrp_ResetAuthorized14 1;
BA_ "GenSigSendType" SG_ 2147485065 MaintInfoGrp_Status34 1;
BA_ "GenSigStartValue" SG_ 2147485065 MaintInfoGrp_Status34 7;
BA_ "GenSigMaxLatency" SG_ 2147485065 MaintInfoGrp_Status34 3000;
BA_ "Platform_VMCU1_Sig" SG_ 2147485065 MaintInfoGrp_Status34 1;
BA_ "GenSigSendType" SG_ 2147485065 MaintInfoGrp_Supported37 1;
BA_ "GenSigStartValue" SG_ 2147485065 MaintInfoGrp_Supported37 3;
BA_ "GenSigMaxLatency" SG_ 2147485065 MaintInfoGrp_Supported37 3000;
BA_ "Platform_VMCU1_Sig" SG_ 2147485065 MaintInfoGrp_Supported37 1;
BA_ "GenSigSendType" SG_ 2147485065 MaintInfoGrp_MaintOption3 1;
BA_ "GenSigStartValue" SG_ 2147485065 MaintInfoGrp_MaintOption3 15;
BA_ "GenSigMaxLatency" SG_ 2147485065 MaintInfoGrp_MaintOption3 3000;
BA_ "Platform_VMCU1_Sig" SG_ 2147485065 MaintInfoGrp_MaintOption3 1;
BA_ "GenSigSendType" SG_ 2147485065 MaintInfoGrp_Status1 1;
BA_ "GenSigStartValue" SG_ 2147485065 MaintInfoGrp_Status1 7;
BA_ "GenSigMaxLatency" SG_ 2147485065 MaintInfoGrp_Status1 3000;
BA_ "Platform_VMCU1_Sig" SG_ 2147485065 MaintInfoGrp_Status1 1;
BA_ "GenSigSendType" SG_ 2147485065 MaintInfoGrp_Data1 1;
BA_ "GenSigStartValue" SG_ 2147485065 MaintInfoGrp_Data1 4294967295;
BA_ "GenSigMaxLatency" SG_ 2147485065 MaintInfoGrp_Data1 3000;
BA_ "Platform_VMCU1_Sig" SG_ 2147485065 MaintInfoGrp_Data1 1;
BA_ "GenSigSendType" SG_ 2147485065 MaintInfoGrp_Status25 1;
BA_ "GenSigStartValue" SG_ 2147485065 MaintInfoGrp_Status25 7;
BA_ "GenSigMaxLatency" SG_ 2147485065 MaintInfoGrp_Status25 3000;
BA_ "Platform_VMCU1_Sig" SG_ 2147485065 MaintInfoGrp_Status25 1;
BA_ "GenSigSendType" SG_ 2147485065 MaintInfoGrp_ResetAuthorized1 1;
BA_ "GenSigStartValue" SG_ 2147485065 MaintInfoGrp_ResetAuthorized1 3;
BA_ "GenSigMaxLatency" SG_ 2147485065 MaintInfoGrp_ResetAuthorized1 3000;
BA_ "Platform_VMCU1_Sig" SG_ 2147485065 MaintInfoGrp_ResetAuthorized1 1;
BA_ "GenSigSendType" SG_ 2147485065 MaintInfoGrp_ResetAuthorized27 1;
BA_ "GenSigStartValue" SG_ 2147485065 MaintInfoGrp_ResetAuthorized27 3;
BA_ "GenSigMaxLatency" SG_ 2147485065 MaintInfoGrp_ResetAuthorized27 3000;
BA_ "Platform_VMCU1_Sig" SG_ 2147485065 MaintInfoGrp_ResetAuthorized27 1;
BA_ "GenSigSendType" SG_ 2147485065 MaintInfoGrp_ResetAuthorized36 1;
BA_ "GenSigStartValue" SG_ 2147485065 MaintInfoGrp_ResetAuthorized36 3;
BA_ "GenSigMaxLatency" SG_ 2147485065 MaintInfoGrp_ResetAuthorized36 3000;
BA_ "Platform_VMCU1_Sig" SG_ 2147485065 MaintInfoGrp_ResetAuthorized36 1;
BA_ "GenSigSendType" SG_ 2147485065 MaintInfoGrp_Status28 1;
BA_ "GenSigStartValue" SG_ 2147485065 MaintInfoGrp_Status28 7;
BA_ "GenSigMaxLatency" SG_ 2147485065 MaintInfoGrp_Status28 3000;
BA_ "Platform_VMCU1_Sig" SG_ 2147485065 MaintInfoGrp_Status28 1;
BA_ "GenSigSendType" SG_ 2147485065 MaintInfoGrp_Status24 1;
BA_ "GenSigStartValue" SG_ 2147485065 MaintInfoGrp_Status24 7;
BA_ "GenSigMaxLatency" SG_ 2147485065 MaintInfoGrp_Status24 3000;
BA_ "Platform_VMCU1_Sig" SG_ 2147485065 MaintInfoGrp_Status24 1;
BA_ "GenSigSendType" SG_ 2147485065 MaintInfoGrp_MaintOption31 1;
BA_ "GenSigStartValue" SG_ 2147485065 MaintInfoGrp_MaintOption31 15;
BA_ "GenSigMaxLatency" SG_ 2147485065 MaintInfoGrp_MaintOption31 3000;
BA_ "Platform_VMCU1_Sig" SG_ 2147485065 MaintInfoGrp_MaintOption31 1;
BA_ "GenSigSendType" SG_ 2147485065 MaintInfoGrp_Supported20 1;
BA_ "GenSigStartValue" SG_ 2147485065 MaintInfoGrp_Supported20 3;
BA_ "GenSigMaxLatency" SG_ 2147485065 MaintInfoGrp_Supported20 3000;
BA_ "Platform_VMCU1_Sig" SG_ 2147485065 MaintInfoGrp_Supported20 1;
BA_ "GenSigSendType" SG_ 2147485065 MaintInfoGrp_Unit38 1;
BA_ "GenSigStartValue" SG_ 2147485065 MaintInfoGrp_Unit38 7;
BA_ "GenSigMaxLatency" SG_ 2147485065 MaintInfoGrp_Unit38 3000;
BA_ "Platform_VMCU1_Sig" SG_ 2147485065 MaintInfoGrp_Unit38 1;
BA_ "GenSigSendType" SG_ 2147485065 MaintInfoGrp_Unit24 1;
BA_ "GenSigStartValue" SG_ 2147485065 MaintInfoGrp_Unit24 7;
BA_ "GenSigMaxLatency" SG_ 2147485065 MaintInfoGrp_Unit24 3000;
BA_ "Platform_VMCU1_Sig" SG_ 2147485065 MaintInfoGrp_Unit24 1;
BA_ "GenSigSendType" SG_ 2147485065 MaintInfoGrp_Data15 1;
BA_ "GenSigStartValue" SG_ 2147485065 MaintInfoGrp_Data15 4294967295;
BA_ "GenSigMaxLatency" SG_ 2147485065 MaintInfoGrp_Data15 3000;
BA_ "Platform_VMCU1_Sig" SG_ 2147485065 MaintInfoGrp_Data15 1;
BA_ "GenSigSendType" SG_ 2147485065 MaintInfoGrp_Status37 1;
BA_ "GenSigStartValue" SG_ 2147485065 MaintInfoGrp_Status37 7;
BA_ "GenSigMaxLatency" SG_ 2147485065 MaintInfoGrp_Status37 3000;
BA_ "Platform_VMCU1_Sig" SG_ 2147485065 MaintInfoGrp_Status37 1;
BA_ "GenSigSendType" SG_ 2147485065 MaintInfoGrp_Supported39 1;
BA_ "GenSigStartValue" SG_ 2147485065 MaintInfoGrp_Supported39 3;
BA_ "GenSigMaxLatency" SG_ 2147485065 MaintInfoGrp_Supported39 3000;
BA_ "Platform_VMCU1_Sig" SG_ 2147485065 MaintInfoGrp_Supported39 1;
BA_ "GenSigSendType" SG_ 2147485065 MaintInfoGrp_MaintOption39 1;
BA_ "GenSigStartValue" SG_ 2147485065 MaintInfoGrp_MaintOption39 15;
BA_ "GenSigMaxLatency" SG_ 2147485065 MaintInfoGrp_MaintOption39 3000;
BA_ "Platform_VMCU1_Sig" SG_ 2147485065 MaintInfoGrp_MaintOption39 1;
BA_ "GenSigSendType" SG_ 2147485065 MaintInfoGrp_Supported4 1;
BA_ "GenSigStartValue" SG_ 2147485065 MaintInfoGrp_Supported4 3;
BA_ "GenSigMaxLatency" SG_ 2147485065 MaintInfoGrp_Supported4 3000;
BA_ "Platform_VMCU1_Sig" SG_ 2147485065 MaintInfoGrp_Supported4 1;
BA_ "GenSigSendType" SG_ 2147485065 MaintInfoGrp_Supported3 1;
BA_ "GenSigStartValue" SG_ 2147485065 MaintInfoGrp_Supported3 3;
BA_ "GenSigMaxLatency" SG_ 2147485065 MaintInfoGrp_Supported3 3000;
BA_ "Platform_VMCU1_Sig" SG_ 2147485065 MaintInfoGrp_Supported3 1;
BA_ "GenSigSendType" SG_ 2147485065 MaintInfoGrp_Data6 1;
BA_ "GenSigStartValue" SG_ 2147485065 MaintInfoGrp_Data6 4294967295;
BA_ "GenSigMaxLatency" SG_ 2147485065 MaintInfoGrp_Data6 3000;
BA_ "Platform_VMCU1_Sig" SG_ 2147485065 MaintInfoGrp_Data6 1;
BA_ "GenSigSendType" SG_ 2147485065 MaintInfoGrp_Unit39 1;
BA_ "GenSigStartValue" SG_ 2147485065 MaintInfoGrp_Unit39 7;
BA_ "GenSigMaxLatency" SG_ 2147485065 MaintInfoGrp_Unit39 3000;
BA_ "Platform_VMCU1_Sig" SG_ 2147485065 MaintInfoGrp_Unit39 1;
BA_ "GenSigSendType" SG_ 2147485065 MaintInfoGrp_Status5 1;
BA_ "GenSigStartValue" SG_ 2147485065 MaintInfoGrp_Status5 7;
BA_ "GenSigMaxLatency" SG_ 2147485065 MaintInfoGrp_Status5 3000;
BA_ "Platform_VMCU1_Sig" SG_ 2147485065 MaintInfoGrp_Status5 1;
BA_ "GenSigSendType" SG_ 2147485065 MaintInfoGrp_Data36 1;
BA_ "GenSigStartValue" SG_ 2147485065 MaintInfoGrp_Data36 4294967295;
BA_ "GenSigMaxLatency" SG_ 2147485065 MaintInfoGrp_Data36 3000;
BA_ "Platform_VMCU1_Sig" SG_ 2147485065 MaintInfoGrp_Data36 1;
BA_ "GenSigSendType" SG_ 2147485065 MaintInfoGrp_MaintOption6 1;
BA_ "GenSigStartValue" SG_ 2147485065 MaintInfoGrp_MaintOption6 15;
BA_ "GenSigMaxLatency" SG_ 2147485065 MaintInfoGrp_MaintOption6 3000;
BA_ "Platform_VMCU1_Sig" SG_ 2147485065 MaintInfoGrp_MaintOption6 1;
BA_ "GenSigSendType" SG_ 2147485065 MaintInfoGrp_Status11 1;
BA_ "GenSigStartValue" SG_ 2147485065 MaintInfoGrp_Status11 7;
BA_ "GenSigMaxLatency" SG_ 2147485065 MaintInfoGrp_Status11 3000;
BA_ "Platform_VMCU1_Sig" SG_ 2147485065 MaintInfoGrp_Status11 1;
BA_ "GenSigSendType" SG_ 2147485065 MaintInfoGrp_Status19 1;
BA_ "GenSigStartValue" SG_ 2147485065 MaintInfoGrp_Status19 7;
BA_ "GenSigMaxLatency" SG_ 2147485065 MaintInfoGrp_Status19 3000;
BA_ "Platform_VMCU1_Sig" SG_ 2147485065 MaintInfoGrp_Status19 1;
BA_ "GenSigSendType" SG_ 2147485065 MaintInfoGrp_Status9 1;
BA_ "GenSigStartValue" SG_ 2147485065 MaintInfoGrp_Status9 7;
BA_ "GenSigMaxLatency" SG_ 2147485065 MaintInfoGrp_Status9 3000;
BA_ "Platform_VMCU1_Sig" SG_ 2147485065 MaintInfoGrp_Status9 1;
BA_ "GenSigSendType" SG_ 2147485065 MaintInfoGrp_Supported11 1;
BA_ "GenSigStartValue" SG_ 2147485065 MaintInfoGrp_Supported11 3;
BA_ "GenSigMaxLatency" SG_ 2147485065 MaintInfoGrp_Supported11 3000;
BA_ "Platform_VMCU1_Sig" SG_ 2147485065 MaintInfoGrp_Supported11 1;
BA_ "GenSigSendType" SG_ 2147485065 MaintInfoGrp_Data27 1;
BA_ "GenSigStartValue" SG_ 2147485065 MaintInfoGrp_Data27 4294967295;
BA_ "GenSigMaxLatency" SG_ 2147485065 MaintInfoGrp_Data27 3000;
BA_ "Platform_VMCU1_Sig" SG_ 2147485065 MaintInfoGrp_Data27 1;
BA_ "GenSigSendType" SG_ 2147485065 MaintInfoGrp_Data31 1;
BA_ "GenSigStartValue" SG_ 2147485065 MaintInfoGrp_Data31 4294967295;
BA_ "GenSigMaxLatency" SG_ 2147485065 MaintInfoGrp_Data31 3000;
BA_ "Platform_VMCU1_Sig" SG_ 2147485065 MaintInfoGrp_Data31 1;
BA_ "GenSigSendType" SG_ 2147485065 MaintInfoGrp_MaintOption36 1;
BA_ "GenSigStartValue" SG_ 2147485065 MaintInfoGrp_MaintOption36 15;
BA_ "GenSigMaxLatency" SG_ 2147485065 MaintInfoGrp_MaintOption36 3000;
BA_ "Platform_VMCU1_Sig" SG_ 2147485065 MaintInfoGrp_MaintOption36 1;
BA_ "GenSigSendType" SG_ 2147485065 MaintInfoGrp_ResetAuthorized8 1;
BA_ "GenSigStartValue" SG_ 2147485065 MaintInfoGrp_ResetAuthorized8 3;
BA_ "GenSigMaxLatency" SG_ 2147485065 MaintInfoGrp_ResetAuthorized8 3000;
BA_ "Platform_VMCU1_Sig" SG_ 2147485065 MaintInfoGrp_ResetAuthorized8 1;
BA_ "GenSigSendType" SG_ 2147485065 MaintInfoGrp_MaintOption21 1;
BA_ "GenSigStartValue" SG_ 2147485065 MaintInfoGrp_MaintOption21 15;
BA_ "GenSigMaxLatency" SG_ 2147485065 MaintInfoGrp_MaintOption21 3000;
BA_ "Platform_VMCU1_Sig" SG_ 2147485065 MaintInfoGrp_MaintOption21 1;
BA_ "GenSigSendType" SG_ 2147485065 MaintInfoGrp_Unit23 1;
BA_ "GenSigStartValue" SG_ 2147485065 MaintInfoGrp_Unit23 7;
BA_ "GenSigMaxLatency" SG_ 2147485065 MaintInfoGrp_Unit23 3000;
BA_ "Platform_VMCU1_Sig" SG_ 2147485065 MaintInfoGrp_Unit23 1;
BA_ "GenSigSendType" SG_ 2147485065 MaintInfoGrp_MaintOption5 1;
BA_ "GenSigStartValue" SG_ 2147485065 MaintInfoGrp_MaintOption5 15;
BA_ "GenSigMaxLatency" SG_ 2147485065 MaintInfoGrp_MaintOption5 3000;
BA_ "Platform_VMCU1_Sig" SG_ 2147485065 MaintInfoGrp_MaintOption5 1;
BA_ "GenSigSendType" SG_ 2147485065 MaintInfoGrp_MaintOption16 1;
BA_ "GenSigStartValue" SG_ 2147485065 MaintInfoGrp_MaintOption16 15;
BA_ "GenSigMaxLatency" SG_ 2147485065 MaintInfoGrp_MaintOption16 3000;
BA_ "Platform_VMCU1_Sig" SG_ 2147485065 MaintInfoGrp_MaintOption16 1;
BA_ "GenSigSendType" SG_ 2147485065 MaintInfoGrp_Unit29 1;
BA_ "GenSigStartValue" SG_ 2147485065 MaintInfoGrp_Unit29 7;
BA_ "GenSigMaxLatency" SG_ 2147485065 MaintInfoGrp_Unit29 3000;
BA_ "Platform_VMCU1_Sig" SG_ 2147485065 MaintInfoGrp_Unit29 1;
BA_ "GenSigSendType" SG_ 2147485065 MaintInfoGrp_Status12 1;
BA_ "GenSigStartValue" SG_ 2147485065 MaintInfoGrp_Status12 7;
BA_ "GenSigMaxLatency" SG_ 2147485065 MaintInfoGrp_Status12 3000;
BA_ "Platform_VMCU1_Sig" SG_ 2147485065 MaintInfoGrp_Status12 1;
BA_ "GenSigSendType" SG_ 2147485065 MaintInfoGrp_Supported0 1;
BA_ "GenSigStartValue" SG_ 2147485065 MaintInfoGrp_Supported0 3;
BA_ "GenSigMaxLatency" SG_ 2147485065 MaintInfoGrp_Supported0 3000;
BA_ "Platform_VMCU1_Sig" SG_ 2147485065 MaintInfoGrp_Supported0 1;
BA_ "GenSigSendType" SG_ 2147485065 MaintInfoGrp_Status8 1;
BA_ "GenSigStartValue" SG_ 2147485065 MaintInfoGrp_Status8 7;
BA_ "GenSigMaxLatency" SG_ 2147485065 MaintInfoGrp_Status8 3000;
BA_ "Platform_VMCU1_Sig" SG_ 2147485065 MaintInfoGrp_Status8 1;
BA_ "GenSigSendType" SG_ 2147485065 MaintInfoGrp_Data11 1;
BA_ "GenSigStartValue" SG_ 2147485065 MaintInfoGrp_Data11 4294967295;
BA_ "GenSigMaxLatency" SG_ 2147485065 MaintInfoGrp_Data11 3000;
BA_ "Platform_VMCU1_Sig" SG_ 2147485065 MaintInfoGrp_Data11 1;
BA_ "GenSigSendType" SG_ 2147485065 MaintInfoGrp_Unit0 1;
BA_ "GenSigStartValue" SG_ 2147485065 MaintInfoGrp_Unit0 7;
BA_ "GenSigMaxLatency" SG_ 2147485065 MaintInfoGrp_Unit0 3000;
BA_ "Platform_VMCU1_Sig" SG_ 2147485065 MaintInfoGrp_Unit0 1;
BA_ "GenSigSendType" SG_ 2147485065 MaintInfoGrp_Supported14 1;
BA_ "GenSigStartValue" SG_ 2147485065 MaintInfoGrp_Supported14 3;
BA_ "GenSigMaxLatency" SG_ 2147485065 MaintInfoGrp_Supported14 3000;
BA_ "Platform_VMCU1_Sig" SG_ 2147485065 MaintInfoGrp_Supported14 1;
BA_ "GenSigSendType" SG_ 2147485065 MaintInfoGrp_Supported8 1;
BA_ "GenSigStartValue" SG_ 2147485065 MaintInfoGrp_Supported8 3;
BA_ "GenSigMaxLatency" SG_ 2147485065 MaintInfoGrp_Supported8 3000;
BA_ "Platform_VMCU1_Sig" SG_ 2147485065 MaintInfoGrp_Supported8 1;
BA_ "GenSigSendType" SG_ 2147484995 VMCU_BB2_32S_FCS 7;
BA_ "Platform_VMCU1_Sig" SG_ 2147484995 VMCU_BB2_32S_FCS 1;
BA_ "GenSigSendType" SG_ 2147484993 ECU2VIN_stat_ISig_4 1;
BA_ "GenSigMaxLatency" SG_ 2147484993 ECU2VIN_stat_ISig_4 137;
BA_ "Platform_VMCU1_Sig" SG_ 2147484993 ECU2VIN_stat_ISig_4 1;
BA_ "GenSigSendType" SG_ 2147485021 VMCU_BB2_31S_FCS 7;
BA_ "Platform_VMCU1_Sig" SG_ 2147485021 VMCU_BB2_31S_FCS 1;
BA_ "GenSigSendType" SG_ 2147485020 ECU1VIN_stat 1;
BA_ "GenSigMaxLatency" SG_ 2147485020 ECU1VIN_stat 137;
BA_ "Platform_VMCU1_Sig" SG_ 2147485020 ECU1VIN_stat 1;
BA_ "GenSigSendType" SG_ 2147484987 MaintInfo_Status 1;
BA_ "GenSigStartValue" SG_ 2147484987 MaintInfo_Status 7;
BA_ "GenSigMaxLatency" SG_ 2147484987 MaintInfo_Status 107;
BA_ "Platform_VMCU1_Sig" SG_ 2147484987 MaintInfo_Status 1;
BA_ "GenSigSendType" SG_ 2147484987 MaintInfo_Unit 1;
BA_ "GenSigStartValue" SG_ 2147484987 MaintInfo_Unit 7;
BA_ "GenSigMaxLatency" SG_ 2147484987 MaintInfo_Unit 107;
BA_ "Platform_VMCU1_Sig" SG_ 2147484987 MaintInfo_Unit 1;
BA_ "GenSigSendType" SG_ 2147484987 MaintInfo_MaintID 1;
BA_ "GenSigStartValue" SG_ 2147484987 MaintInfo_MaintID 63;
BA_ "GenSigMaxLatency" SG_ 2147484987 MaintInfo_MaintID 107;
BA_ "Platform_VMCU1_Sig" SG_ 2147484987 MaintInfo_MaintID 1;
BA_ "GenSigSendType" SG_ 2147484987 MaintInfo_Supported 1;
BA_ "GenSigStartValue" SG_ 2147484987 MaintInfo_Supported 3;
BA_ "GenSigMaxLatency" SG_ 2147484987 MaintInfo_Supported 107;
BA_ "Platform_VMCU1_Sig" SG_ 2147484987 MaintInfo_Supported 1;
BA_ "GenSigSendType" SG_ 2147484987 MaintInfo_ResetAuthorized 1;
BA_ "GenSigStartValue" SG_ 2147484987 MaintInfo_ResetAuthorized 3;
BA_ "GenSigMaxLatency" SG_ 2147484987 MaintInfo_ResetAuthorized 107;
BA_ "Platform_VMCU1_Sig" SG_ 2147484987 MaintInfo_ResetAuthorized 1;
BA_ "GenSigSendType" SG_ 2147484987 MaintInfo_MaintOption 1;
BA_ "GenSigStartValue" SG_ 2147484987 MaintInfo_MaintOption 15;
BA_ "GenSigMaxLatency" SG_ 2147484987 MaintInfo_MaintOption 107;
BA_ "Platform_VMCU1_Sig" SG_ 2147484987 MaintInfo_MaintOption 1;
BA_ "GenSigSendType" SG_ 2147484987 MaintInfo_Data 1;
BA_ "GenSigStartValue" SG_ 2147484987 MaintInfo_Data 4294967295;
BA_ "GenSigMaxLatency" SG_ 2147484987 MaintInfo_Data 107;
BA_ "Platform_VMCU1_Sig" SG_ 2147484987 MaintInfo_Data 1;
BA_ "GenSigSendType" SG_ 2147484888 FrontAxle2Load_UB_ISig_4 7;
BA_ "Platform_VMCU1_Sig" SG_ 2147484888 FrontAxle2Load_UB_ISig_4 1;
BA_ "GenSigCycleTime" SG_ 2147484888 PwtCCUnderSpeedRequest 100;
BA_ "GenSigCycleTimeActive" SG_ 2147484888 PwtCCUnderSpeedRequest 100;
BA_ "GenSigStartValue" SG_ 2147484888 PwtCCUnderSpeedRequest 65535;
BA_ "GenSigSendType" SG_ 2147484888 FrontAxle1Load_UB_ISig_4 7;
BA_ "Platform_VMCU1_Sig" SG_ 2147484888 FrontAxle1Load_UB_ISig_4 1;
BA_ "GenSigCycleTime" SG_ 2147484888 TransferCasePTOEngaged_ISig_4 100;
BA_ "GenSigCycleTimeActive" SG_ 2147484888 TransferCasePTOEngaged_ISig_4 100;
BA_ "GenSigStartValue" SG_ 2147484888 TransferCasePTOEngaged_ISig_4 3;
BA_ "Platform_VMCU1_Sig" SG_ 2147484888 TransferCasePTOEngaged_ISig_4 1;
BA_ "GenSigCycleTime" SG_ 2147484888 FrontAxle1Load_ISig_4 100;
BA_ "GenSigCycleTimeActive" SG_ 2147484888 FrontAxle1Load_ISig_4 100;
BA_ "GenSigStartValue" SG_ 2147484888 FrontAxle1Load_ISig_4 65535;
BA_ "NeedsUpdateBit" SG_ 2147484888 FrontAxle1Load_ISig_4 1;
BA_ "Platform_VMCU1_Sig" SG_ 2147484888 FrontAxle1Load_ISig_4 1;
BA_ "SeToolAncestorID_SIGNAL" SG_ 2147484888 FrontAxle1Load_ISig_4 "x0000001D0412EB1E";
BA_ "SeToolItemID_SIGNAL" SG_ 2147484888 FrontAxle1Load_ISig_4 "x0000001D04274C69";
BA_ "SeToolName_SIGNAL" SG_ 2147484888 FrontAxle1Load_ISig_4 "FrontAxle1Load";
BA_ "SeToolVersion_SIGNAL" SG_ 2147484888 FrontAxle1Load_ISig_4 "3";
BA_ "GenSigCycleTime" SG_ 2147484888 FrontAxle2Load_ISig_4 100;
BA_ "GenSigCycleTimeActive" SG_ 2147484888 FrontAxle2Load_ISig_4 100;
BA_ "GenSigStartValue" SG_ 2147484888 FrontAxle2Load_ISig_4 65535;
BA_ "NeedsUpdateBit" SG_ 2147484888 FrontAxle2Load_ISig_4 1;
BA_ "Platform_VMCU1_Sig" SG_ 2147484888 FrontAxle2Load_ISig_4 1;
BA_ "SeToolAncestorID_SIGNAL" SG_ 2147484888 FrontAxle2Load_ISig_4 "x0000001D0412EB1E";
BA_ "SeToolItemID_SIGNAL" SG_ 2147484888 FrontAxle2Load_ISig_4 "x0000001D04274C69";
BA_ "SeToolName_SIGNAL" SG_ 2147484888 FrontAxle2Load_ISig_4 "FrontAxle2Load";
BA_ "SeToolVersion_SIGNAL" SG_ 2147484888 FrontAxle2Load_ISig_4 "3";
BA_ "GenSigCycleTime" SG_ 2147485078 Driver1CumulativeBreakTime_ISig_ 100;
BA_ "GenSigCycleTimeActive" SG_ 2147485078 Driver1CumulativeBreakTime_ISig_ 100;
BA_ "GenSigStartValue" SG_ 2147485078 Driver1CumulativeBreakTime_ISig_ 65535;
BA_ "GenSigMaxLatency" SG_ 2147485078 Driver1CumulativeBreakTime_ISig_ 1054;
BA_ "Platform_VMCU1_Sig" SG_ 2147485078 Driver1CumulativeBreakTime_ISig_ 1;
BA_ "SeToolAncestorID_SIGNAL" SG_ 2147485078 Driver1CumulativeBreakTime_ISig_ "x0000001D042CB4DF";
BA_ "SeToolItemID_SIGNAL" SG_ 2147485078 Driver1CumulativeBreakTime_ISig_ "x0000001D042CB4DF";
BA_ "SeToolName_SIGNAL" SG_ 2147485078 Driver1CumulativeBreakTime_ISig_ "Driver1CumulativeBreakTime";
BA_ "SeToolVersion_SIGNAL" SG_ 2147485078 Driver1CumulativeBreakTime_ISig_ "1";
BA_ "SystemSignalLongSymbol" SG_ 2147485078 Driver1CumulativeBreakTime_ISig_ "Driver1CumulativeBreakTime_ISig_4";
BA_ "GenSigCycleTime" SG_ 2147485078 DrawerState 100;
BA_ "GenSigCycleTimeActive" SG_ 2147485078 DrawerState 100;
BA_ "GenSigStartValue" SG_ 2147485078 DrawerState 3;
BA_ "Platform_VMCU1_Sig" SG_ 2147485078 DrawerState 1;
BA_ "SeToolAncestorID_SIGNAL" SG_ 2147485078 DrawerState "x0000001D042CB4F2";
BA_ "SeToolItemID_SIGNAL" SG_ 2147485078 DrawerState "x0000001D042CB4F2";
BA_ "SeToolName_SIGNAL" SG_ 2147485078 DrawerState "DrawerState";
BA_ "SeToolVersion_SIGNAL" SG_ 2147485078 DrawerState "1";
BA_ "GenSigCycleTime" SG_ 2147485078 EndofLifeDriver1Card 100;
BA_ "GenSigCycleTimeActive" SG_ 2147485078 EndofLifeDriver1Card 100;
BA_ "GenSigStartValue" SG_ 2147485078 EndofLifeDriver1Card 3;
BA_ "Platform_VMCU1_Sig" SG_ 2147485078 EndofLifeDriver1Card 1;
BA_ "SeToolAncestorID_SIGNAL" SG_ 2147485078 EndofLifeDriver1Card "x0000001D043F3E2C";
BA_ "SeToolItemID_SIGNAL" SG_ 2147485078 EndofLifeDriver1Card "x0000001D043F3E2C";
BA_ "SeToolName_SIGNAL" SG_ 2147485078 EndofLifeDriver1Card "EndofLifeDriver1Card";
BA_ "SeToolVersion_SIGNAL" SG_ 2147485078 EndofLifeDriver1Card "1";
BA_ "GenSigCycleTime" SG_ 2147485078 Driver1ContinuousDrivingTime_ISi 100;
BA_ "GenSigCycleTimeActive" SG_ 2147485078 Driver1ContinuousDrivingTime_ISi 100;
BA_ "GenSigStartValue" SG_ 2147485078 Driver1ContinuousDrivingTime_ISi 65535;
BA_ "GenSigMaxLatency" SG_ 2147485078 Driver1ContinuousDrivingTime_ISi 1054;
BA_ "Platform_VMCU1_Sig" SG_ 2147485078 Driver1ContinuousDrivingTime_ISi 1;
BA_ "SeToolAncestorID_SIGNAL" SG_ 2147485078 Driver1ContinuousDrivingTime_ISi "x0000001D042D24E3";
BA_ "SeToolItemID_SIGNAL" SG_ 2147485078 Driver1ContinuousDrivingTime_ISi "x0000001D042D24E3";
BA_ "SeToolName_SIGNAL" SG_ 2147485078 Driver1ContinuousDrivingTime_ISi "Driver1ContinuousDrivingTime ";
BA_ "SeToolVersion_SIGNAL" SG_ 2147485078 Driver1ContinuousDrivingTime_ISi "1";
BA_ "SystemSignalLongSymbol" SG_ 2147485078 Driver1ContinuousDrivingTime_ISi "Driver1ContinuousDrivingTime_ISig_4";
BA_ "GenSigCycleTime" SG_ 2147485078 Driver1CardUnload 100;
BA_ "GenSigCycleTimeActive" SG_ 2147485078 Driver1CardUnload 100;
BA_ "GenSigStartValue" SG_ 2147485078 Driver1CardUnload 3;
BA_ "GenSigMaxLatency" SG_ 2147485078 Driver1CardUnload 1054;
BA_ "Platform_VMCU1_Sig" SG_ 2147485078 Driver1CardUnload 1;
BA_ "SeToolAncestorID_SIGNAL" SG_ 2147485078 Driver1CardUnload "x0000001D043F99B9";
BA_ "SeToolItemID_SIGNAL" SG_ 2147485078 Driver1CardUnload "x0000001D043F99B9";
BA_ "SeToolName_SIGNAL" SG_ 2147485078 Driver1CardUnload "Driver1CardUnload";
BA_ "SeToolVersion_SIGNAL" SG_ 2147485078 Driver1CardUnload "1";
BA_ "GenSigCycleTime" SG_ 2147485078 Drvr1CurDurationSelectedActy_ISi 100;
BA_ "GenSigCycleTimeActive" SG_ 2147485078 Drvr1CurDurationSelectedActy_ISi 100;
BA_ "GenSigStartValue" SG_ 2147485078 Drvr1CurDurationSelectedActy_ISi 65535;
BA_ "GenSigMaxLatency" SG_ 2147485078 Drvr1CurDurationSelectedActy_ISi 1054;
BA_ "Platform_VMCU1_Sig" SG_ 2147485078 Drvr1CurDurationSelectedActy_ISi 1;
BA_ "SeToolAncestorID_SIGNAL" SG_ 2147485078 Drvr1CurDurationSelectedActy_ISi "x0000001D042CB4EB";
BA_ "SeToolItemID_SIGNAL" SG_ 2147485078 Drvr1CurDurationSelectedActy_ISi "x0000001D042CB4EB";
BA_ "SeToolName_SIGNAL" SG_ 2147485078 Drvr1CurDurationSelectedActy_ISi "Driver1CurrentDurationOfSelectedActivity";
BA_ "SeToolVersion_SIGNAL" SG_ 2147485078 Drvr1CurDurationSelectedActy_ISi "1";
BA_ "SystemSignalLongSymbol" SG_ 2147485078 Drvr1CurDurationSelectedActy_ISi "Drvr1CurDurationSelectedActy_ISig_4";
BA_ "GenSigCycleTime" SG_ 2147485061 FuelConsumptionPTO 100;
BA_ "GenSigCycleTimeActive" SG_ 2147485061 FuelConsumptionPTO 100;
BA_ "GenSigStartValue" SG_ 2147485061 FuelConsumptionPTO 4294967295;
BA_ "Platform_VMCU1_Sig" SG_ 2147485061 FuelConsumptionPTO 1;
BA_ "GenSigCycleTime" SG_ 2147485061 AtLeastOnePTOActivationTime_ISig 100;
BA_ "GenSigCycleTimeActive" SG_ 2147485061 AtLeastOnePTOActivationTime_ISig 100;
BA_ "GenSigStartValue" SG_ 2147485061 AtLeastOnePTOActivationTime_ISig 4294967295;
BA_ "GenSigMaxLatency" SG_ 2147485061 AtLeastOnePTOActivationTime_ISig 1021;
BA_ "Platform_VMCU1_Sig" SG_ 2147485061 AtLeastOnePTOActivationTime_ISig 1;
BA_ "SystemSignalLongSymbol" SG_ 2147485061 AtLeastOnePTOActivationTime_ISig "AtLeastOnePTOActivationTime_ISig_4";
BA_ "GenSigCycleTime" SG_ 2147485060 EngineGreenAreaOutFuel_ISig_4 100;
BA_ "GenSigCycleTimeActive" SG_ 2147485060 EngineGreenAreaOutFuel_ISig_4 100;
BA_ "GenSigStartValue" SG_ 2147485060 EngineGreenAreaOutFuel_ISig_4 4294967295;
BA_ "GenSigMaxLatency" SG_ 2147485060 EngineGreenAreaOutFuel_ISig_4 1019;
BA_ "Platform_VMCU1_Sig" SG_ 2147485060 EngineGreenAreaOutFuel_ISig_4 1;
BA_ "GenSigCycleTime" SG_ 2147485060 CCTime 100;
BA_ "GenSigCycleTimeActive" SG_ 2147485060 CCTime 100;
BA_ "GenSigStartValue" SG_ 2147485060 CCTime 4294967295;
BA_ "GenSigMaxLatency" SG_ 2147485060 CCTime 1019;
BA_ "Platform_VMCU1_Sig" SG_ 2147485060 CCTime 1;
BA_ "GenSigCycleTime" SG_ 2147485059 LngTotalRemainingGasVolume_ISig_ 100;
BA_ "GenSigCycleTimeActive" SG_ 2147485059 LngTotalRemainingGasVolume_ISig_ 100;
BA_ "GenSigStartValue" SG_ 2147485059 LngTotalRemainingGasVolume_ISig_ 65535;
BA_ "GenSigMaxLatency" SG_ 2147485059 LngTotalRemainingGasVolume_ISig_ 1000;
BA_ "SystemSignalLongSymbol" SG_ 2147485059 LngTotalRemainingGasVolume_ISig_ "LngTotalRemainingGasVolume_ISig_4";
BA_ "GenSigCycleTime" SG_ 2147485059 MIStatusExtVMCU 100;
BA_ "GenSigCycleTimeActive" SG_ 2147485059 MIStatusExtVMCU 100;
BA_ "GenSigStartValue" SG_ 2147485059 MIStatusExtVMCU 3;
BA_ "Platform_VMCU1_Sig" SG_ 2147485059 MIStatusExtVMCU 1;
BA_ "GenSigCycleTime" SG_ 2147485059 MIDistinctWarningExtVMCU 100;
BA_ "GenSigCycleTimeActive" SG_ 2147485059 MIDistinctWarningExtVMCU 100;
BA_ "GenSigStartValue" SG_ 2147485059 MIDistinctWarningExtVMCU 15;
BA_ "Platform_VMCU1_Sig" SG_ 2147485059 MIDistinctWarningExtVMCU 1;
BA_ "GenSigCycleTime" SG_ 2147485059 EngTrueIdleSpeedFuel 100;
BA_ "GenSigCycleTimeActive" SG_ 2147485059 EngTrueIdleSpeedFuel 100;
BA_ "GenSigStartValue" SG_ 2147485059 EngTrueIdleSpeedFuel 4294967295;
BA_ "GenSigMaxLatency" SG_ 2147485059 EngTrueIdleSpeedFuel 1018;
BA_ "Platform_VMCU1_Sig" SG_ 2147485059 EngTrueIdleSpeedFuel 1;
BA_ "GenSigCycleTime" SG_ 2147485036 FuelConsumptionVehicleStopped 100;
BA_ "GenSigCycleTimeActive" SG_ 2147485036 FuelConsumptionVehicleStopped 100;
BA_ "GenSigStartValue" SG_ 2147485036 FuelConsumptionVehicleStopped 4294967295;
BA_ "GenSigMaxLatency" SG_ 2147485036 FuelConsumptionVehicleStopped 1017;
BA_ "Platform_VMCU1_Sig" SG_ 2147485036 FuelConsumptionVehicleStopped 1;
BA_ "GenSigCycleTime" SG_ 2147485036 FuelConsumptionVehicleRunning_IS 100;
BA_ "GenSigCycleTimeActive" SG_ 2147485036 FuelConsumptionVehicleRunning_IS 100;
BA_ "GenSigStartValue" SG_ 2147485036 FuelConsumptionVehicleRunning_IS 4294967295;
BA_ "GenSigMaxLatency" SG_ 2147485036 FuelConsumptionVehicleRunning_IS 1017;
BA_ "Platform_VMCU1_Sig" SG_ 2147485036 FuelConsumptionVehicleRunning_IS 1;
BA_ "SystemSignalLongSymbol" SG_ 2147485036 FuelConsumptionVehicleRunning_IS "FuelConsumptionVehicleRunning_ISig_4";
BA_ "GenSigCycleTime" SG_ 2147485037 AdBlueConsumptVehicleRunning 100;
BA_ "GenSigCycleTimeActive" SG_ 2147485037 AdBlueConsumptVehicleRunning 100;
BA_ "GenSigStartValue" SG_ 2147485037 AdBlueConsumptVehicleRunning 4294967295;
BA_ "GenSigMaxLatency" SG_ 2147485037 AdBlueConsumptVehicleRunning 1014;
BA_ "Platform_VMCU1_Sig" SG_ 2147485037 AdBlueConsumptVehicleRunning 1;
BA_ "GenSigCycleTime" SG_ 2147485037 AdBlueConsumptVehicleStopped 100;
BA_ "GenSigCycleTimeActive" SG_ 2147485037 AdBlueConsumptVehicleStopped 100;
BA_ "GenSigStartValue" SG_ 2147485037 AdBlueConsumptVehicleStopped 4294967295;
BA_ "GenSigMaxLatency" SG_ 2147485037 AdBlueConsumptVehicleStopped 1014;
BA_ "Platform_VMCU1_Sig" SG_ 2147485037 AdBlueConsumptVehicleStopped 1;
BA_ "GenSigCycleTime" SG_ 2147484915 StaticCornerLightLamp_stat_ISig_ 100;
BA_ "GenSigCycleTimeActive" SG_ 2147484915 StaticCornerLightLamp_stat_ISig_ 100;
BA_ "GenSigStartValue" SG_ 2147484915 StaticCornerLightLamp_stat_ISig_ 7;
BA_ "GenSigMaxLatency" SG_ 2147484915 StaticCornerLightLamp_stat_ISig_ 258;
BA_ "Platform_VMCU1_Sig" SG_ 2147484915 StaticCornerLightLamp_stat_ISig_ 1;
BA_ "SystemSignalLongSymbol" SG_ 2147484915 StaticCornerLightLamp_stat_ISig_ "StaticCornerLightLamp_stat_ISig_4";
BA_ "GenSigCycleTime" SG_ 2147484915 DRLLamp_stat_ISig_4 100;
BA_ "GenSigCycleTimeActive" SG_ 2147484915 DRLLamp_stat_ISig_4 100;
BA_ "GenSigStartValue" SG_ 2147484915 DRLLamp_stat_ISig_4 7;
BA_ "GenSigMaxLatency" SG_ 2147484915 DRLLamp_stat_ISig_4 258;
BA_ "Platform_VMCU1_Sig" SG_ 2147484915 DRLLamp_stat_ISig_4 1;
BA_ "GenSigCycleTime" SG_ 2147484915 DirInd_Front_Status_ISig_4 100;
BA_ "GenSigCycleTimeActive" SG_ 2147484915 DirInd_Front_Status_ISig_4 100;
BA_ "GenSigStartValue" SG_ 2147484915 DirInd_Front_Status_ISig_4 7;
BA_ "GenSigMaxLatency" SG_ 2147484915 DirInd_Front_Status_ISig_4 258;
BA_ "Platform_VMCU1_Sig" SG_ 2147484915 DirInd_Front_Status_ISig_4 1;
BA_ "SeToolAncestorID_SIGNAL" SG_ 2147484915 DirInd_Front_Status_ISig_4 "x0000001D041661B2";
BA_ "SeToolItemID_SIGNAL" SG_ 2147484915 DirInd_Front_Status_ISig_4 "x0000001D042DBCE4";
BA_ "SeToolName_SIGNAL" SG_ 2147484915 DirInd_Front_Status_ISig_4 "DirInd_Front_Status";
BA_ "SeToolVersion_SIGNAL" SG_ 2147484915 DirInd_Front_Status_ISig_4 "2";
BA_ "GenSigCycleTime" SG_ 2147484915 ChassiInstepLightsLamp_stat_ISig 100;
BA_ "GenSigCycleTimeActive" SG_ 2147484915 ChassiInstepLightsLamp_stat_ISig 100;
BA_ "GenSigStartValue" SG_ 2147484915 ChassiInstepLightsLamp_stat_ISig 7;
BA_ "GenSigMaxLatency" SG_ 2147484915 ChassiInstepLightsLamp_stat_ISig 258;
BA_ "Platform_VMCU1_Sig" SG_ 2147484915 ChassiInstepLightsLamp_stat_ISig 1;
BA_ "SystemSignalLongSymbol" SG_ 2147484915 ChassiInstepLightsLamp_stat_ISig "ChassiInstepLightsLamp_stat_ISig_4";
BA_ "GenSigCycleTime" SG_ 2147484915 PositionLightLamp_stat_ISig_4 100;
BA_ "GenSigCycleTimeActive" SG_ 2147484915 PositionLightLamp_stat_ISig_4 100;
BA_ "GenSigStartValue" SG_ 2147484915 PositionLightLamp_stat_ISig_4 7;
BA_ "GenSigMaxLatency" SG_ 2147484915 PositionLightLamp_stat_ISig_4 258;
BA_ "Platform_VMCU1_Sig" SG_ 2147484915 PositionLightLamp_stat_ISig_4 1;
BA_ "GenSigCycleTime" SG_ 2147484915 BrakeLightLamp_stat_ISig_4 100;
BA_ "GenSigCycleTimeActive" SG_ 2147484915 BrakeLightLamp_stat_ISig_4 100;
BA_ "GenSigStartValue" SG_ 2147484915 BrakeLightLamp_stat_ISig_4 7;
BA_ "GenSigMaxLatency" SG_ 2147484915 BrakeLightLamp_stat_ISig_4 258;
BA_ "Platform_VMCU1_Sig" SG_ 2147484915 BrakeLightLamp_stat_ISig_4 1;
BA_ "GenSigCycleTime" SG_ 2147484915 RevLightLamp_stat_ISig_4 100;
BA_ "GenSigCycleTimeActive" SG_ 2147484915 RevLightLamp_stat_ISig_4 100;
BA_ "GenSigStartValue" SG_ 2147484915 RevLightLamp_stat_ISig_4 7;
BA_ "GenSigMaxLatency" SG_ 2147484915 RevLightLamp_stat_ISig_4 258;
BA_ "Platform_VMCU1_Sig" SG_ 2147484915 RevLightLamp_stat_ISig_4 1;
BA_ "GenSigCycleTime" SG_ 2147484915 AuxFogLightLamp_stat_ISig_4 100;
BA_ "GenSigCycleTimeActive" SG_ 2147484915 AuxFogLightLamp_stat_ISig_4 100;
BA_ "GenSigStartValue" SG_ 2147484915 AuxFogLightLamp_stat_ISig_4 7;
BA_ "GenSigMaxLatency" SG_ 2147484915 AuxFogLightLamp_stat_ISig_4 258;
BA_ "Platform_VMCU1_Sig" SG_ 2147484915 AuxFogLightLamp_stat_ISig_4 1;
BA_ "GenSigCycleTime" SG_ 2147484915 AirCleanerUnderPressure 100;
BA_ "GenSigCycleTimeActive" SG_ 2147484915 AirCleanerUnderPressure 100;
BA_ "GenSigStartValue" SG_ 2147484915 AirCleanerUnderPressure 3;
BA_ "GenSigCycleTime" SG_ 2147484915 DirIndSideLamp_stat 100;
BA_ "GenSigCycleTimeActive" SG_ 2147484915 DirIndSideLamp_stat 100;
BA_ "GenSigStartValue" SG_ 2147484915 DirIndSideLamp_stat 7;
BA_ "GenSigMaxLatency" SG_ 2147484915 DirIndSideLamp_stat 258;
BA_ "Platform_VMCU1_Sig" SG_ 2147484915 DirIndSideLamp_stat 1;
BA_ "GenSigCycleTime" SG_ 2147484915 TrailerRevAndFogOutput_stat_ISig 100;
BA_ "GenSigCycleTimeActive" SG_ 2147484915 TrailerRevAndFogOutput_stat_ISig 100;
BA_ "GenSigStartValue" SG_ 2147484915 TrailerRevAndFogOutput_stat_ISig 3;
BA_ "SystemSignalLongSymbol" SG_ 2147484915 TrailerRevAndFogOutput_stat_ISig "TrailerRevAndFogOutput_stat_ISig_4";
BA_ "GenSigCycleTime" SG_ 2147484915 MainBeamLamp_stat_ISig_4 100;
BA_ "GenSigCycleTimeActive" SG_ 2147484915 MainBeamLamp_stat_ISig_4 100;
BA_ "GenSigStartValue" SG_ 2147484915 MainBeamLamp_stat_ISig_4 7;
BA_ "GenSigCycleTime" SG_ 2147484915 ExtraMainBeamLamp_stat_ISig_4 100;
BA_ "GenSigCycleTimeActive" SG_ 2147484915 ExtraMainBeamLamp_stat_ISig_4 100;
BA_ "GenSigStartValue" SG_ 2147484915 ExtraMainBeamLamp_stat_ISig_4 7;
BA_ "GenSigMaxLatency" SG_ 2147484915 ExtraMainBeamLamp_stat_ISig_4 258;
BA_ "Platform_VMCU1_Sig" SG_ 2147484915 ExtraMainBeamLamp_stat_ISig_4 1;
BA_ "GenSigCycleTime" SG_ 2147484915 FogLightFrontLamp_stat_ISig_4 100;
BA_ "GenSigCycleTimeActive" SG_ 2147484915 FogLightFrontLamp_stat_ISig_4 100;
BA_ "GenSigStartValue" SG_ 2147484915 FogLightFrontLamp_stat_ISig_4 7;
BA_ "GenSigMaxLatency" SG_ 2147484915 FogLightFrontLamp_stat_ISig_4 258;
BA_ "Platform_VMCU1_Sig" SG_ 2147484915 FogLightFrontLamp_stat_ISig_4 1;
BA_ "GenSigCycleTime" SG_ 2147484915 DippedBeamLamp_stat_ISig_4 100;
BA_ "GenSigCycleTimeActive" SG_ 2147484915 DippedBeamLamp_stat_ISig_4 100;
BA_ "GenSigStartValue" SG_ 2147484915 DippedBeamLamp_stat_ISig_4 7;
BA_ "GenSigMaxLatency" SG_ 2147484915 DippedBeamLamp_stat_ISig_4 258;
BA_ "Platform_VMCU1_Sig" SG_ 2147484915 DippedBeamLamp_stat_ISig_4 1;
BA_ "GenSigCycleTime" SG_ 2147484915 FogLightRearLamp_stat_ISig_4 100;
BA_ "GenSigCycleTimeActive" SG_ 2147484915 FogLightRearLamp_stat_ISig_4 100;
BA_ "GenSigStartValue" SG_ 2147484915 FogLightRearLamp_stat_ISig_4 7;
BA_ "GenSigMaxLatency" SG_ 2147484915 FogLightRearLamp_stat_ISig_4 258;
BA_ "Platform_VMCU1_Sig" SG_ 2147484915 FogLightRearLamp_stat_ISig_4 1;
BA_REL_ "GenSigFirstTimeoutTime" BU_SG_REL_ TECU SG_ 2147484383 CCSetSpeed_ISig_4 3000;
BA_REL_ "GenSigTimeoutTime" BU_SG_REL_ TECU SG_ 2147484383 CCSetSpeed_ISig_4 210;
BA_REL_ "GenSigFirstTimeoutTime" BU_SG_REL_ BBM SG_ 2147484383 CCSetSpeed_ISig_4 3000;
BA_REL_ "GenSigTimeoutTime" BU_SG_REL_ BBM SG_ 2147484383 CCSetSpeed_ISig_4 210;
BA_REL_ "GenSigFirstTimeoutTime" BU_SG_REL_ DACU SG_ 2147484383 CCSetSpeed_ISig_4 3000;
BA_REL_ "GenSigTimeoutTime" BU_SG_REL_ DACU SG_ 2147484383 CCSetSpeed_ISig_4 600;
BA_REL_ "GenSigFirstTimeoutTime" BU_SG_REL_ IC3 SG_ 2147484383 CCSetSpeed_ISig_4 3000;
BA_REL_ "GenSigTimeoutTime" BU_SG_REL_ IC3 SG_ 2147484383 CCSetSpeed_ISig_4 210;
BA_REL_ "GenSigFirstTimeoutTime" BU_SG_REL_ BBM SG_ 2147484383 AcceleratorPedalQuality_ISig_4 3000;
BA_REL_ "GenSigTimeoutTime" BU_SG_REL_ BBM SG_ 2147484383 AcceleratorPedalQuality_ISig_4 210;
BA_REL_ "GenSigFirstTimeoutTime" BU_SG_REL_ IC3 SG_ 2147484383 AcceleratorPedalQuality_ISig_4 3000;
BA_REL_ "GenSigTimeoutTime" BU_SG_REL_ IC3 SG_ 2147484383 AcceleratorPedalQuality_ISig_4 210;
BA_REL_ "GenSigFirstTimeoutTime" BU_SG_REL_ CIOM SG_ 2147484383 CCStates_ISig_4 3000;
BA_REL_ "GenSigTimeoutTime" BU_SG_REL_ CIOM SG_ 2147484383 CCStates_ISig_4 210;
BA_REL_ "GenSigFirstTimeoutTime" BU_SG_REL_ DACU SG_ 2147484383 CCStates_ISig_4 3000;
BA_REL_ "GenSigTimeoutTime" BU_SG_REL_ DACU SG_ 2147484383 CCStates_ISig_4 210;
BA_REL_ "GenSigFirstTimeoutTime" BU_SG_REL_ IC3 SG_ 2147484383 CCStates_ISig_4 3000;
BA_REL_ "GenSigTimeoutTime" BU_SG_REL_ IC3 SG_ 2147484383 CCStates_ISig_4 210;
BA_REL_ "GenSigFirstTimeoutTime" BU_SG_REL_ BBM SG_ 2147484383 CCStates_ISig_4 3000;
BA_REL_ "GenSigTimeoutTime" BU_SG_REL_ BBM SG_ 2147484383 CCStates_ISig_4 210;
BA_REL_ "GenSigFirstTimeoutTime" BU_SG_REL_ IC3 SG_ 2147484383 CCIOM_ParkBrakeAlert_ISig_4 3000;
BA_REL_ "GenSigTimeoutTime" BU_SG_REL_ IC3 SG_ 2147484383 CCIOM_ParkBrakeAlert_ISig_4 210;
BA_REL_ "GenSigFirstTimeoutTime" BU_SG_REL_ DACU SG_ 2147484383 CCDeactivationWarning 3000;
BA_REL_ "GenSigTimeoutTime" BU_SG_REL_ DACU SG_ 2147484383 CCDeactivationWarning 210;
BA_REL_ "GenSigFirstTimeoutTime" BU_SG_REL_ BBM SG_ 2147484383 PrimaryAcctrPedalPosition_ISig_4 3000;
BA_REL_ "GenSigTimeoutTime" BU_SG_REL_ BBM SG_ 2147484383 PrimaryAcctrPedalPosition_ISig_4 210;
BA_REL_ "GenSigFirstTimeoutTime" BU_SG_REL_ IC3 SG_ 2147484383 CCNotificationReq 3000;
BA_REL_ "GenSigTimeoutTime" BU_SG_REL_ IC3 SG_ 2147484383 CCNotificationReq 210;
BA_REL_ "GenSigFirstTimeoutTime" BU_SG_REL_ CIOM SG_ 2147484383 AcceleratorPedalStatus_ISig_4 3000;
BA_REL_ "GenSigTimeoutTime" BU_SG_REL_ CIOM SG_ 2147484383 AcceleratorPedalStatus_ISig_4 210;
BA_REL_ "GenSigFirstTimeoutTime" BU_SG_REL_ BBM SG_ 2147484383 AcceleratorPedalStatus_ISig_4 3000;
BA_REL_ "GenSigTimeoutTime" BU_SG_REL_ BBM SG_ 2147484383 AcceleratorPedalStatus_ISig_4 210;
BA_REL_ "GenSigFirstTimeoutTime" BU_SG_REL_ CIOM SG_ 2147484383 LoadDistributionRequestedACK_ISi 3000;
BA_REL_ "GenSigTimeoutTime" BU_SG_REL_ CIOM SG_ 2147484383 LoadDistributionRequestedACK_ISi 210;
BA_REL_ "GenSigFirstTimeoutTime" BU_SG_REL_ CIOM SG_ 2147484383 ElectricalLoadReduction_rqst_ISi 3000;
BA_REL_ "GenSigTimeoutTime" BU_SG_REL_ CIOM SG_ 2147484383 ElectricalLoadReduction_rqst_ISi 500;
BA_REL_ "GenSigFirstTimeoutTime" BU_SG_REL_ BBM SG_ 2147484383 FifthWheelLockingInformation_ISi 3000;
BA_REL_ "GenSigTimeoutTime" BU_SG_REL_ BBM SG_ 2147484383 FifthWheelLockingInformation_ISi 500;
BA_REL_ "GenSigFirstTimeoutTime" BU_SG_REL_ IC3 SG_ 2147484383 FifthWheelLockingInformation_ISi 3000;
BA_REL_ "GenSigTimeoutTime" BU_SG_REL_ IC3 SG_ 2147484383 FifthWheelLockingInformation_ISi 500;
BA_REL_ "GenSigFirstTimeoutTime" BU_SG_REL_ DACU SG_ 2147484377 CCBSetSpeed 3000;
BA_REL_ "GenSigTimeoutTime" BU_SG_REL_ DACU SG_ 2147484377 CCBSetSpeed 180;
BA_REL_ "GenSigFirstTimeoutTime" BU_SG_REL_ TECU SG_ 2147484377 CCBSetSpeed 3000;
BA_REL_ "GenSigTimeoutTime" BU_SG_REL_ TECU SG_ 2147484377 CCBSetSpeed 180;
BA_REL_ "GenSigFirstTimeoutTime" BU_SG_REL_ IC3 SG_ 2147484377 ASLNotificationReq 3000;
BA_REL_ "GenSigTimeoutTime" BU_SG_REL_ IC3 SG_ 2147484377 ASLNotificationReq 180;
BA_REL_ "GenSigFirstTimeoutTime" BU_SG_REL_ IC3 SG_ 2147484377 GearRangeUnengaged_ISig_4 3000;
BA_REL_ "GenSigTimeoutTime" BU_SG_REL_ IC3 SG_ 2147484377 GearRangeUnengaged_ISig_4 180;
BA_REL_ "GenSigFirstTimeoutTime" BU_SG_REL_ DACU SG_ 2147484377 LaneChangeStatus_ISig_4 3000;
BA_REL_ "GenSigTimeoutTime" BU_SG_REL_ DACU SG_ 2147484377 LaneChangeStatus_ISig_4 180;
BA_REL_ "GenSigFirstTimeoutTime" BU_SG_REL_ IC3 SG_ 2147484377 LaneChangeStatus_ISig_4 3000;
BA_REL_ "GenSigTimeoutTime" BU_SG_REL_ IC3 SG_ 2147484377 LaneChangeStatus_ISig_4 180;
BA_REL_ "GenSigFirstTimeoutTime" BU_SG_REL_ CIOM SG_ 2147484377 ASLStates 3000;
BA_REL_ "GenSigTimeoutTime" BU_SG_REL_ CIOM SG_ 2147484377 ASLStates 180;
BA_REL_ "GenSigFirstTimeoutTime" BU_SG_REL_ IC3 SG_ 2147484377 ASLStates 3000;
BA_REL_ "GenSigTimeoutTime" BU_SG_REL_ IC3 SG_ 2147484377 ASLStates 180;
BA_REL_ "GenSigFirstTimeoutTime" BU_SG_REL_ IC3 SG_ 2147484377 ASLSetSpeed 3000;
BA_REL_ "GenSigTimeoutTime" BU_SG_REL_ IC3 SG_ 2147484377 ASLSetSpeed 180;
BA_REL_ "GenSigFirstTimeoutTime" BU_SG_REL_ BBM SG_ 2147484377 LongMotionDirection_ISig_4 3000;
BA_REL_ "GenSigTimeoutTime" BU_SG_REL_ BBM SG_ 2147484377 LongMotionDirection_ISig_4 180;
BA_REL_ "GenSigFirstTimeoutTime" BU_SG_REL_ CIOM SG_ 2147484377 LongMotionDirection_ISig_4 3000;
BA_REL_ "GenSigTimeoutTime" BU_SG_REL_ CIOM SG_ 2147484377 LongMotionDirection_ISig_4 120;
BA_REL_ "GenSigFirstTimeoutTime" BU_SG_REL_ CIOM SG_ 2147484377 LongMotionDirectionQual_ISig_4 3000;
BA_REL_ "GenSigTimeoutTime" BU_SG_REL_ CIOM SG_ 2147484377 LongMotionDirectionQual_ISig_4 120;
BA_REL_ "GenSigFirstTimeoutTime" BU_SG_REL_ TECU SG_ 2147484888 PwtCCUnderSpeedRequest 6000;
BA_REL_ "GenSigTimeoutTime" BU_SG_REL_ TECU SG_ 2147484888 PwtCCUnderSpeedRequest 1500;
BA_REL_ "GenSigFirstTimeoutTime" BU_SG_REL_ CIOM SG_ 2147484888 TransferCasePTOEngaged_ISig_4 6000;
BA_REL_ "GenSigTimeoutTime" BU_SG_REL_ CIOM SG_ 2147484888 TransferCasePTOEngaged_ISig_4 1500;
BA_REL_ "GenSigFirstTimeoutTime" BU_SG_REL_ DACU SG_ 2147484888 FrontAxle1Load_ISig_4 6000;
BA_REL_ "GenSigTimeoutTime" BU_SG_REL_ DACU SG_ 2147484888 FrontAxle1Load_ISig_4 1500;
BA_REL_ "GenSigFirstTimeoutTime" BU_SG_REL_ TECU SG_ 2147484888 FrontAxle1Load_ISig_4 6000;
BA_REL_ "GenSigTimeoutTime" BU_SG_REL_ TECU SG_ 2147484888 FrontAxle1Load_ISig_4 1500;
BA_REL_ "GenSigFirstTimeoutTime" BU_SG_REL_ BBM SG_ 2147484888 FrontAxle1Load_ISig_4 6000;
BA_REL_ "GenSigTimeoutTime" BU_SG_REL_ BBM SG_ 2147484888 FrontAxle1Load_ISig_4 1500;
BA_REL_ "GenSigFirstTimeoutTime" BU_SG_REL_ DACU SG_ 2147484888 FrontAxle2Load_ISig_4 6000;
BA_REL_ "GenSigTimeoutTime" BU_SG_REL_ DACU SG_ 2147484888 FrontAxle2Load_ISig_4 1500;
BA_REL_ "GenSigFirstTimeoutTime" BU_SG_REL_ BBM SG_ 2147484888 FrontAxle2Load_ISig_4 6000;
BA_REL_ "GenSigTimeoutTime" BU_SG_REL_ BBM SG_ 2147484888 FrontAxle2Load_ISig_4 1500;
BA_REL_ "GenSigFirstTimeoutTime" BU_SG_REL_ TECU SG_ 2147484888 FrontAxle2Load_ISig_4 6000;
BA_REL_ "GenSigTimeoutTime" BU_SG_REL_ TECU SG_ 2147484888 FrontAxle2Load_ISig_4 1500;
BA_REL_ "GenSigFirstTimeoutTime" BU_SG_REL_ IC3 SG_ 2147485078 Driver1CumulativeBreakTime_ISig_ 24000;
BA_REL_ "GenSigTimeoutTime" BU_SG_REL_ IC3 SG_ 2147485078 Driver1CumulativeBreakTime_ISig_ 6000;
BA_REL_ "GenSigFirstTimeoutTime" BU_SG_REL_ IC3 SG_ 2147485078 DrawerState 24000;
BA_REL_ "GenSigTimeoutTime" BU_SG_REL_ IC3 SG_ 2147485078 DrawerState 6000;
BA_REL_ "GenSigFirstTimeoutTime" BU_SG_REL_ IC3 SG_ 2147485078 EndofLifeDriver1Card 24000;
BA_REL_ "GenSigTimeoutTime" BU_SG_REL_ IC3 SG_ 2147485078 EndofLifeDriver1Card 6000;
BA_REL_ "GenSigFirstTimeoutTime" BU_SG_REL_ IC3 SG_ 2147485078 Driver1ContinuousDrivingTime_ISi 24000;
BA_REL_ "GenSigTimeoutTime" BU_SG_REL_ IC3 SG_ 2147485078 Driver1ContinuousDrivingTime_ISi 6000;
BA_REL_ "GenSigFirstTimeoutTime" BU_SG_REL_ IC3 SG_ 2147485078 Driver1CardUnload 24000;
BA_REL_ "GenSigTimeoutTime" BU_SG_REL_ IC3 SG_ 2147485078 Driver1CardUnload 6000;
BA_REL_ "GenSigFirstTimeoutTime" BU_SG_REL_ IC3 SG_ 2147485078 Drvr1CurDurationSelectedActy_ISi 24000;
BA_REL_ "GenSigTimeoutTime" BU_SG_REL_ IC3 SG_ 2147485078 Drvr1CurDurationSelectedActy_ISi 6000;
BA_REL_ "GenSigFirstTimeoutTime" BU_SG_REL_ IC3 SG_ 2147485061 FuelConsumptionPTO 24000;
BA_REL_ "GenSigTimeoutTime" BU_SG_REL_ IC3 SG_ 2147485061 FuelConsumptionPTO 6000;
BA_REL_ "GenSigFirstTimeoutTime" BU_SG_REL_ IC3 SG_ 2147485061 AtLeastOnePTOActivationTime_ISig 24000;
BA_REL_ "GenSigTimeoutTime" BU_SG_REL_ IC3 SG_ 2147485061 AtLeastOnePTOActivationTime_ISig 6000;
BA_REL_ "GenSigFirstTimeoutTime" BU_SG_REL_ BBM SG_ 2147485061 AtLeastOnePTOActivationTime_ISig 24000;
BA_REL_ "GenSigTimeoutTime" BU_SG_REL_ BBM SG_ 2147485061 AtLeastOnePTOActivationTime_ISig 6000;
BA_REL_ "GenSigFirstTimeoutTime" BU_SG_REL_ IC3 SG_ 2147485060 EngineGreenAreaOutFuel_ISig_4 24000;
BA_REL_ "GenSigTimeoutTime" BU_SG_REL_ IC3 SG_ 2147485060 EngineGreenAreaOutFuel_ISig_4 6000;
BA_REL_ "GenSigFirstTimeoutTime" BU_SG_REL_ IC3 SG_ 2147485060 CCTime 24000;
BA_REL_ "GenSigTimeoutTime" BU_SG_REL_ IC3 SG_ 2147485060 CCTime 6000;
BA_REL_ "GenSigFirstTimeoutTime" BU_SG_REL_ IC3 SG_ 2147485059 LngTotalRemainingGasVolume_ISig_ 24000;
BA_REL_ "GenSigTimeoutTime" BU_SG_REL_ IC3 SG_ 2147485059 LngTotalRemainingGasVolume_ISig_ 6000;
BA_REL_ "GenSigFirstTimeoutTime" BU_SG_REL_ EMS SG_ 2147485059 MIStatusExtVMCU 24000;
BA_REL_ "GenSigTimeoutTime" BU_SG_REL_ EMS SG_ 2147485059 MIStatusExtVMCU 6000;
BA_REL_ "GenSigFirstTimeoutTime" BU_SG_REL_ EMS SG_ 2147485059 MIDistinctWarningExtVMCU 24000;
BA_REL_ "GenSigTimeoutTime" BU_SG_REL_ EMS SG_ 2147485059 MIDistinctWarningExtVMCU 6000;
BA_REL_ "GenSigFirstTimeoutTime" BU_SG_REL_ IC3 SG_ 2147485059 EngTrueIdleSpeedFuel 24000;
BA_REL_ "GenSigTimeoutTime" BU_SG_REL_ IC3 SG_ 2147485059 EngTrueIdleSpeedFuel 6000;
BA_REL_ "GenSigFirstTimeoutTime" BU_SG_REL_ IC3 SG_ 2147485036 FuelConsumptionVehicleStopped 24000;
BA_REL_ "GenSigTimeoutTime" BU_SG_REL_ IC3 SG_ 2147485036 FuelConsumptionVehicleStopped 6000;
BA_REL_ "GenSigFirstTimeoutTime" BU_SG_REL_ IC3 SG_ 2147485036 FuelConsumptionVehicleRunning_IS 24000;
BA_REL_ "GenSigTimeoutTime" BU_SG_REL_ IC3 SG_ 2147485036 FuelConsumptionVehicleRunning_IS 6000;
BA_REL_ "GenSigFirstTimeoutTime" BU_SG_REL_ IC3 SG_ 2147485037 AdBlueConsumptVehicleRunning 24000;
BA_REL_ "GenSigTimeoutTime" BU_SG_REL_ IC3 SG_ 2147485037 AdBlueConsumptVehicleRunning 6000;
BA_REL_ "GenSigFirstTimeoutTime" BU_SG_REL_ IC3 SG_ 2147485037 AdBlueConsumptVehicleStopped 24000;
BA_REL_ "GenSigTimeoutTime" BU_SG_REL_ IC3 SG_ 2147485037 AdBlueConsumptVehicleStopped 6000;
BA_REL_ "GenSigFirstTimeoutTime" BU_SG_REL_ IC3 SG_ 2147484915 StaticCornerLightLamp_stat_ISig_ 6000;
BA_REL_ "GenSigTimeoutTime" BU_SG_REL_ IC3 SG_ 2147484915 StaticCornerLightLamp_stat_ISig_ 1500;
BA_REL_ "GenSigFirstTimeoutTime" BU_SG_REL_ IC3 SG_ 2147484915 DRLLamp_stat_ISig_4 6000;
BA_REL_ "GenSigTimeoutTime" BU_SG_REL_ IC3 SG_ 2147484915 DRLLamp_stat_ISig_4 1500;
BA_REL_ "GenSigFirstTimeoutTime" BU_SG_REL_ IC3 SG_ 2147484915 DirInd_Front_Status_ISig_4 6000;
BA_REL_ "GenSigTimeoutTime" BU_SG_REL_ IC3 SG_ 2147484915 DirInd_Front_Status_ISig_4 1500;
BA_REL_ "GenSigFirstTimeoutTime" BU_SG_REL_ IC3 SG_ 2147484915 ChassiInstepLightsLamp_stat_ISig 6000;
BA_REL_ "GenSigTimeoutTime" BU_SG_REL_ IC3 SG_ 2147484915 ChassiInstepLightsLamp_stat_ISig 1500;
BA_REL_ "GenSigFirstTimeoutTime" BU_SG_REL_ IC3 SG_ 2147484915 PositionLightLamp_stat_ISig_4 6000;
BA_REL_ "GenSigTimeoutTime" BU_SG_REL_ IC3 SG_ 2147484915 PositionLightLamp_stat_ISig_4 1500;
BA_REL_ "GenSigFirstTimeoutTime" BU_SG_REL_ IC3 SG_ 2147484915 BrakeLightLamp_stat_ISig_4 6000;
BA_REL_ "GenSigTimeoutTime" BU_SG_REL_ IC3 SG_ 2147484915 BrakeLightLamp_stat_ISig_4 1500;
BA_REL_ "GenSigFirstTimeoutTime" BU_SG_REL_ IC3 SG_ 2147484915 RevLightLamp_stat_ISig_4 6000;
BA_REL_ "GenSigTimeoutTime" BU_SG_REL_ IC3 SG_ 2147484915 RevLightLamp_stat_ISig_4 1500;
BA_REL_ "GenSigFirstTimeoutTime" BU_SG_REL_ IC3 SG_ 2147484915 AuxFogLightLamp_stat_ISig_4 6000;
BA_REL_ "GenSigTimeoutTime" BU_SG_REL_ IC3 SG_ 2147484915 AuxFogLightLamp_stat_ISig_4 1500;
BA_REL_ "GenSigFirstTimeoutTime" BU_SG_REL_ IC3 SG_ 2147484915 AirCleanerUnderPressure 6000;
BA_REL_ "GenSigTimeoutTime" BU_SG_REL_ IC3 SG_ 2147484915 AirCleanerUnderPressure 1500;
BA_REL_ "GenSigFirstTimeoutTime" BU_SG_REL_ IC3 SG_ 2147484915 DirIndSideLamp_stat 6000;
BA_REL_ "GenSigTimeoutTime" BU_SG_REL_ IC3 SG_ 2147484915 DirIndSideLamp_stat 1500;
BA_REL_ "GenSigFirstTimeoutTime" BU_SG_REL_ IC3 SG_ 2147484915 TrailerRevAndFogOutput_stat_ISig 6000;
BA_REL_ "GenSigTimeoutTime" BU_SG_REL_ IC3 SG_ 2147484915 TrailerRevAndFogOutput_stat_ISig 1500;
BA_REL_ "GenSigFirstTimeoutTime" BU_SG_REL_ IC3 SG_ 2147484915 MainBeamLamp_stat_ISig_4 6000;
BA_REL_ "GenSigTimeoutTime" BU_SG_REL_ IC3 SG_ 2147484915 MainBeamLamp_stat_ISig_4 1500;
BA_REL_ "GenSigFirstTimeoutTime" BU_SG_REL_ IC3 SG_ 2147484915 ExtraMainBeamLamp_stat_ISig_4 6000;
BA_REL_ "GenSigTimeoutTime" BU_SG_REL_ IC3 SG_ 2147484915 ExtraMainBeamLamp_stat_ISig_4 1500;
BA_REL_ "GenSigFirstTimeoutTime" BU_SG_REL_ IC3 SG_ 2147484915 FogLightFrontLamp_stat_ISig_4 6000;
BA_REL_ "GenSigTimeoutTime" BU_SG_REL_ IC3 SG_ 2147484915 FogLightFrontLamp_stat_ISig_4 1500;
BA_REL_ "GenSigFirstTimeoutTime" BU_SG_REL_ IC3 SG_ 2147484915 DippedBeamLamp_stat_ISig_4 6000;
BA_REL_ "GenSigTimeoutTime" BU_SG_REL_ IC3 SG_ 2147484915 DippedBeamLamp_stat_ISig_4 1500;
BA_REL_ "GenSigFirstTimeoutTime" BU_SG_REL_ IC3 SG_ 2147484915 FogLightRearLamp_stat_ISig_4 6000;
BA_REL_ "GenSigTimeoutTime" BU_SG_REL_ IC3 SG_ 2147484915 FogLightRearLamp_stat_ISig_4 1500;
VAL_ 2147484383 AcceleratorPedalQuality_ISig_4 3 "PrimaryAcceleratorPedalQuality_NotAvailable" 2 "PrimaryAcceleratorPedalQuality_ErrorMode" 1 "PrimaryAcceleratorPedalQuality_DowngradedMode" 0 "PrimaryAcceleratorPedalQuality_NormalMode" ;
VAL_ 2147484383 CCStates_ISig_4 15 "CCStates_NotAvailable" 14 "CCStates_Error" 13 "CCStates_Spare_7" 12 "CCStates_Spare_6" 11 "CCStates_Spare_5" 10 "CCStates_Spare_4" 9 "CCStates_Spare_3" 8 "CCStates_Spare_2" 7 "CCStates_Spare_1" 6 "CCStates_Driver_Override" 5 "CCStates_Set" 4 "CCStates_Resume" 3 "CCStates_Decelerate" 2 "CCStates_Accelerate" 1 "CCStates_Hold" 0 "CCStates_OffDisabled" ;
VAL_ 2147484383 CCIOM_ParkBrakeAlert_ISig_4 3 "Alert_NotAvailable" 2 "Alert_Error" 1 "Alert_Alert" 0 "Alert_NoAlert" ;
VAL_ 2147484383 CCDeactivationWarning 3 "OffOn_NotAvailable" 2 "OffOn_Error" 1 "OffOn_On" 0 "OffOn_Off" ;
VAL_ 2147484383 CCNotificationReq 15 "CCNotificationReq_NotAvailable" 14 "CCNotificationReq_Error" 13 "CCNotificationReq_Spare_6" 12 "CCNotificationReq_Spare_5" 11 "CCNotificationReq_Spare_4" 10 "CCNotificationReq_Spare_3" 9 "CCNotificationReq_Spare_2" 8 "CCNotificationReq_activation_failed_brake_pedal_check" 7 "CCNotificationReq_Deactivation_warning" 6 "CCNotificationReq_Activation_failed_error" 5 "CCNotificationReq_Activation_stop_braking" 4 "CCNotificationReq_Activation_failed_low_speed" 3 "CCNotificationReq_Overridden_manual_braking" 2 "CCNotificationReq_Overridden_manual_acceleration" 1 "CCNotificationReq_Overspeed_warning" 0 "CCNotificationReq_No_request" ;
VAL_ 2147484383 AcceleratorPedalStatus_ISig_4 7 "AcceleratorPedalStatus_NotAvailable" 6 "AcceleratorPedalStatus_Error" 5 "AcceleratorPedalStatus_Spare3" 4 "AcceleratorPedalStatus_Spare2" 3 "AcceleratorPedalStatus_Spare1" 2 "AcceleratorPedalStatus_PrimAndSecPedalInhibited" 1 "AcceleratorPedalStatus_SecPedActPrimPedNotAct" 0 "AcceleratorPedalStatus_SecPedNotActPrimPedAct" ;
VAL_ 2147484383 LoadDistributionRequestedACK_ISi 7 "LoadDistributionRequestedACK_NotAvailable" 6 "LoadDistributionRequestedACK_Error" 5 "LoadDistributionRequestedACK_SystemDeniedVersatile" 4 "LoadDistributionRequestedACK_Reserved2" 3 "LoadDistributionRequestedACK_Reserved1" 2 "LoadDistributionRequestedACK_LoadShiftDeniedFALIMOverload" 1 "LoadDistributionRequestedACK_ChangeAcknowledged" 0 "LoadDistributionRequestedACK_NoAction" ;
VAL_ 2147484383 ElectricalLoadReduction_rqst_ISi 7 "ElectricalLoadReduction_rqst_NotAvailable" 6 "ElectricalLoadReduction_rqst_Error" 5 "ElectricalLoadReduction_rqst_SpareValue_02" 4 "ElectricalLoadReduction_rqst_SpareValue_01" 3 "ElectricalLoadReduction_rqst_SpareValue" 2 "ElectricalLoadReduction_rqst_Level2Request" 1 "ElectricalLoadReduction_rqst_Level1Request" 0 "ElectricalLoadReduction_rqst_NoRequest" ;
VAL_ 2147484383 FifthWheelLockingInformation_ISi 15 "FifthWheelLockingInformation_NotAvailable" 14 "FifthWheelLockingInformation_Error" 13 "FifthWheelLockingInformation_Spare_07" 12 "FifthWheelLockingInformation_Spare_06" 11 "FifthWheelLockingInformation_Spare_05" 10 "FifthWheelLockingInformation_Spare_04" 9 "FifthWheelLockingInformation_Spare_03" 8 "FifthWheelLockingInformation_Spare_02" 7 "FifthWheelLockingInformation_Spare_01" 6 "FifthWheelLockingInformation_Spare" 5 "FifthWheelLockingInformation_5thWheelSystemError" 4 "FifthWheelLockingInformation_TrailerNotCorrectlyCoupled" 3 "FifthWheelLockingInformation_HandleLockedTrailerRightConnected" 2 "FifthWheelLockingInformation_KingPinEndPosTrailerPlateInContact" 1 "FifthWheelLockingInformation_TrailerPlateInContactW_semitrailer" 0 "FifthWheelLockingInformation_TractorAlone" ;
VAL_ 2147484377 ASLNotificationReq 7 "ASLNotificationReq_NotAvailable" 6 "ASLNotificationReq_Error" 5 "ASLNotificationReq_Spare" 4 "ASLNotificationReq_DeactivationWarning" 3 "ASLNotificationReq_DeactivationFailedError" 2 "ASLNotificationReq_ActivationFailedLowSpeed" 1 "ASLNotificationReq_OverspeedWarning" 0 "ASLNotificationReq_NoRequest" ;
VAL_ 2147484377 GearRangeUnengaged_ISig_4 3 "GearInhibation_NotAvailable" 2 "GearInhibation_Error" 1 "GearInhibation_GearChangeInhibited" 0 "GearInhibation_NoInhibation" ;
VAL_ 2147484377 LaneChangeStatus_ISig_4 15 "LaneChangeStatus_NotAvailable" 14 "LaneChangeStatus_Error" 13 "LaneChangeStatus_Spare11" 12 "LaneChangeStatus_Spare10" 11 "LaneChangeStatus_Spare9" 10 "LaneChangeStatus_Spare8" 9 "LaneChangeStatus_Spare7" 8 "LaneChangeStatus_Spare6" 7 "LaneChangeStatus_Spare5" 6 "LaneChangeStatus_Spare4" 5 "LaneChangeStatus_Spare3" 4 "LaneChangeStatus_Spare2" 3 "LaneChangeStatus_Spare1" 2 "LaneChangeStatus_RightLaneChangeIntention" 1 "LaneChangeStatus_LeftLaneChangeIntention" 0 "LaneChangeStatus_NotActive" ;
VAL_ 2147484377 ASLStates 15 "ASLStates_NotAvailable" 14 "ASLStates_Error" 6 "ASLStates_Driver_override" 5 "ASLStates_Set" 4 "ASLStates_Resume" 3 "ASLStates_Decelerate" 2 "ASLStates_Accelerate" 1 "ASLStates_Hold" 0 "ASLStates_Off_disabled" ;
VAL_ 2147484377 LongMotionDirection_ISig_4 7 "LongMotionDirection_NotAvailable" 6 "LongMotionDirection_Error" 5 "LongMotionDirection_Spare3" 4 "LongMotionDirection_Spare2" 3 "LongMotionDirection_Undetermined" 2 "LongMotionDirection_Backward" 1 "LongMotionDirection_Forward" 0 "LongMotionDirection_Stationary" ;
VAL_ 2147484377 LongMotionDirectionQual_ISig_4 3 "LongMotionDirectionQual_NotAvailable" 2 "LongMotionDirectionQual_OEM_Reserved2" 1 "LongMotionDirectionQual_OEM_Reserved1" 0 "LongMotionDirectionQual_UsingGearbox" ;
VAL_ 2147485065 MaintInfoGrp_MaintOption30 15 "MaintOption_NotAvailable" 14 "MaintOption_Error" 13 "MaintOption_13" 12 "MaintOption_12" 11 "MaintOption_11" 10 "MaintOption_10" 9 "MaintOption_9" 8 "MaintOption_8" 7 "MaintOption_7" 6 "MaintOption_6" 5 "MaintOption_5" 4 "MaintOption_4" 3 "MaintOption_3" 2 "MaintOption_2" 1 "MaintOption_1" 0 "MaintOption_0" ;
VAL_ 2147485065 MaintInfoGrp_Unit36 7 "MaintenanceUnit_NotAvailable" 6 "MaintenanceUnit_Error" 5 "MaintenanceUnit_None" 4 "MaintenanceUnit_AxleNumber" 3 "MaintenanceUnit_Percentage" 2 "MaintenanceUnit_Date" 1 "MaintenanceUnit_Distance" 0 "MaintenanceUnit_EngineTime" ;
VAL_ 2147485065 MaintInfoGrp_MaintOption33 15 "MaintOption_NotAvailable" 14 "MaintOption_Error" 13 "MaintOption_13" 12 "MaintOption_12" 11 "MaintOption_11" 10 "MaintOption_10" 9 "MaintOption_9" 8 "MaintOption_8" 7 "MaintOption_7" 6 "MaintOption_6" 5 "MaintOption_5" 4 "MaintOption_4" 3 "MaintOption_3" 2 "MaintOption_2" 1 "MaintOption_1" 0 "MaintOption_0" ;
VAL_ 2147485065 MaintInfoGrp_ResetAuthorized32 3 "NoYes_NotAvailable" 2 "NoYes_Error" 1 "NoYes_Yes" 0 "NoYes_No" ;
VAL_ 2147485065 MaintInfoGrp_Status10 7 "MaintenanceStatus_NotAvailable" 6 "MaintenanceStatus_Error" 5 "MaintenanceStatus_Spare_01" 4 "MaintenanceStatus_InProgress" 3 "MaintenanceStatus_Spare" 2 "MaintenanceStatus_Warning" 1 "MaintenanceStatus_PreWarning" 0 "MaintenanceStatus_OK" ;
VAL_ 2147485065 MaintInfoGrp_Unit2 7 "MaintenanceUnit_NotAvailable" 6 "MaintenanceUnit_Error" 5 "MaintenanceUnit_None" 4 "MaintenanceUnit_AxleNumber" 3 "MaintenanceUnit_Percentage" 2 "MaintenanceUnit_Date" 1 "MaintenanceUnit_Distance" 0 "MaintenanceUnit_EngineTime" ;
VAL_ 2147485065 MaintInfoGrp_Unit14 7 "MaintenanceUnit_NotAvailable" 6 "MaintenanceUnit_Error" 5 "MaintenanceUnit_None" 4 "MaintenanceUnit_AxleNumber" 3 "MaintenanceUnit_Percentage" 2 "MaintenanceUnit_Date" 1 "MaintenanceUnit_Distance" 0 "MaintenanceUnit_EngineTime" ;
VAL_ 2147485065 MaintInfoGrp_ResetAuthorized28 3 "NoYes_NotAvailable" 2 "NoYes_Error" 1 "NoYes_Yes" 0 "NoYes_No" ;
VAL_ 2147485065 MaintInfoGrp_ResetAuthorized10 3 "NoYes_NotAvailable" 2 "NoYes_Error" 1 "NoYes_Yes" 0 "NoYes_No" ;
VAL_ 2147485065 MaintInfoGrp_Status31 7 "MaintenanceStatus_NotAvailable" 6 "MaintenanceStatus_Error" 5 "MaintenanceStatus_Spare_01" 4 "MaintenanceStatus_InProgress" 3 "MaintenanceStatus_Spare" 2 "MaintenanceStatus_Warning" 1 "MaintenanceStatus_PreWarning" 0 "MaintenanceStatus_OK" ;
VAL_ 2147485065 MaintInfoGrp_Unit32 7 "MaintenanceUnit_NotAvailable" 6 "MaintenanceUnit_Error" 5 "MaintenanceUnit_None" 4 "MaintenanceUnit_AxleNumber" 3 "MaintenanceUnit_Percentage" 2 "MaintenanceUnit_Date" 1 "MaintenanceUnit_Distance" 0 "MaintenanceUnit_EngineTime" ;
VAL_ 2147485065 MaintInfoGrp_Status15 7 "MaintenanceStatus_NotAvailable" 6 "MaintenanceStatus_Error" 5 "MaintenanceStatus_Spare_01" 4 "MaintenanceStatus_InProgress" 3 "MaintenanceStatus_Spare" 2 "MaintenanceStatus_Warning" 1 "MaintenanceStatus_PreWarning" 0 "MaintenanceStatus_OK" ;
VAL_ 2147485065 MaintInfoGrp_Supported19 3 "NoYes_NotAvailable" 2 "NoYes_Error" 1 "NoYes_Yes" 0 "NoYes_No" ;
VAL_ 2147485065 MaintInfoGrp_Unit34 7 "MaintenanceUnit_NotAvailable" 6 "MaintenanceUnit_Error" 5 "MaintenanceUnit_None" 4 "MaintenanceUnit_AxleNumber" 3 "MaintenanceUnit_Percentage" 2 "MaintenanceUnit_Date" 1 "MaintenanceUnit_Distance" 0 "MaintenanceUnit_EngineTime" ;
VAL_ 2147485065 MaintInfoGrp_Unit26 7 "MaintenanceUnit_NotAvailable" 6 "MaintenanceUnit_Error" 5 "MaintenanceUnit_None" 4 "MaintenanceUnit_AxleNumber" 3 "MaintenanceUnit_Percentage" 2 "MaintenanceUnit_Date" 1 "MaintenanceUnit_Distance" 0 "MaintenanceUnit_EngineTime" ;
VAL_ 2147485065 MaintInfoGrp_ResetAuthorized24 3 "NoYes_NotAvailable" 2 "NoYes_Error" 1 "NoYes_Yes" 0 "NoYes_No" ;
VAL_ 2147485065 MaintInfoGrp_ResetAuthorized34 3 "NoYes_NotAvailable" 2 "NoYes_Error" 1 "NoYes_Yes" 0 "NoYes_No" ;
VAL_ 2147485065 MaintInfoGrp_Unit28 7 "MaintenanceUnit_NotAvailable" 6 "MaintenanceUnit_Error" 5 "MaintenanceUnit_None" 4 "MaintenanceUnit_AxleNumber" 3 "MaintenanceUnit_Percentage" 2 "MaintenanceUnit_Date" 1 "MaintenanceUnit_Distance" 0 "MaintenanceUnit_EngineTime" ;
VAL_ 2147485065 MaintInfoGrp_Status26 7 "MaintenanceStatus_NotAvailable" 6 "MaintenanceStatus_Error" 5 "MaintenanceStatus_Spare_01" 4 "MaintenanceStatus_InProgress" 3 "MaintenanceStatus_Spare" 2 "MaintenanceStatus_Warning" 1 "MaintenanceStatus_PreWarning" 0 "MaintenanceStatus_OK" ;
VAL_ 2147485065 MaintInfoGrp_Unit10 7 "MaintenanceUnit_NotAvailable" 6 "MaintenanceUnit_Error" 5 "MaintenanceUnit_None" 4 "MaintenanceUnit_AxleNumber" 3 "MaintenanceUnit_Percentage" 2 "MaintenanceUnit_Date" 1 "MaintenanceUnit_Distance" 0 "MaintenanceUnit_EngineTime" ;
VAL_ 2147485065 MaintInfoGrp_ResetAuthorized38 3 "NoYes_NotAvailable" 2 "NoYes_Error" 1 "NoYes_Yes" 0 "NoYes_No" ;
VAL_ 2147485065 MaintInfoGrp_MaintOption14 15 "MaintOption_NotAvailable" 14 "MaintOption_Error" 13 "MaintOption_13" 12 "MaintOption_12" 11 "MaintOption_11" 10 "MaintOption_10" 9 "MaintOption_9" 8 "MaintOption_8" 7 "MaintOption_7" 6 "MaintOption_6" 5 "MaintOption_5" 4 "MaintOption_4" 3 "MaintOption_3" 2 "MaintOption_2" 1 "MaintOption_1" 0 "MaintOption_0" ;
VAL_ 2147485065 MaintInfoGrp_MaintOption17 15 "MaintOption_NotAvailable" 14 "MaintOption_Error" 13 "MaintOption_13" 12 "MaintOption_12" 11 "MaintOption_11" 10 "MaintOption_10" 9 "MaintOption_9" 8 "MaintOption_8" 7 "MaintOption_7" 6 "MaintOption_6" 5 "MaintOption_5" 4 "MaintOption_4" 3 "MaintOption_3" 2 "MaintOption_2" 1 "MaintOption_1" 0 "MaintOption_0" ;
VAL_ 2147485065 MaintInfoGrp_Status33 7 "MaintenanceStatus_NotAvailable" 6 "MaintenanceStatus_Error" 5 "MaintenanceStatus_Spare_01" 4 "MaintenanceStatus_InProgress" 3 "MaintenanceStatus_Spare" 2 "MaintenanceStatus_Warning" 1 "MaintenanceStatus_PreWarning" 0 "MaintenanceStatus_OK" ;
VAL_ 2147485065 MaintInfoGrp_Unit6 7 "MaintenanceUnit_NotAvailable" 6 "MaintenanceUnit_Error" 5 "MaintenanceUnit_None" 4 "MaintenanceUnit_AxleNumber" 3 "MaintenanceUnit_Percentage" 2 "MaintenanceUnit_Date" 1 "MaintenanceUnit_Distance" 0 "MaintenanceUnit_EngineTime" ;
VAL_ 2147485065 MaintInfoGrp_Supported7 3 "NoYes_NotAvailable" 2 "NoYes_Error" 1 "NoYes_Yes" 0 "NoYes_No" ;
VAL_ 2147485065 MaintInfoGrp_Status7 7 "MaintenanceStatus_NotAvailable" 6 "MaintenanceStatus_Error" 5 "MaintenanceStatus_Spare_01" 4 "MaintenanceStatus_InProgress" 3 "MaintenanceStatus_Spare" 2 "MaintenanceStatus_Warning" 1 "MaintenanceStatus_PreWarning" 0 "MaintenanceStatus_OK" ;
VAL_ 2147485065 MaintInfoGrp_ResetAuthorized2 3 "NoYes_NotAvailable" 2 "NoYes_Error" 1 "NoYes_Yes" 0 "NoYes_No" ;
VAL_ 2147485065 MaintInfoGrp_MaintOption27 15 "MaintOption_NotAvailable" 14 "MaintOption_Error" 13 "MaintOption_13" 12 "MaintOption_12" 11 "MaintOption_11" 10 "MaintOption_10" 9 "MaintOption_9" 8 "MaintOption_8" 7 "MaintOption_7" 6 "MaintOption_6" 5 "MaintOption_5" 4 "MaintOption_4" 3 "MaintOption_3" 2 "MaintOption_2" 1 "MaintOption_1" 0 "MaintOption_0" ;
VAL_ 2147485065 MaintInfoGrp_Supported36 3 "NoYes_NotAvailable" 2 "NoYes_Error" 1 "NoYes_Yes" 0 "NoYes_No" ;
VAL_ 2147485065 MaintInfoGrp_Unit22 7 "MaintenanceUnit_NotAvailable" 6 "MaintenanceUnit_Error" 5 "MaintenanceUnit_None" 4 "MaintenanceUnit_AxleNumber" 3 "MaintenanceUnit_Percentage" 2 "MaintenanceUnit_Date" 1 "MaintenanceUnit_Distance" 0 "MaintenanceUnit_EngineTime" ;
VAL_ 2147485065 MaintInfoGrp_Unit18 7 "MaintenanceUnit_NotAvailable" 6 "MaintenanceUnit_Error" 5 "MaintenanceUnit_None" 4 "MaintenanceUnit_AxleNumber" 3 "MaintenanceUnit_Percentage" 2 "MaintenanceUnit_Date" 1 "MaintenanceUnit_Distance" 0 "MaintenanceUnit_EngineTime" ;
VAL_ 2147485065 MaintInfoGrp_MaintOption28 15 "MaintOption_NotAvailable" 14 "MaintOption_Error" 13 "MaintOption_13" 12 "MaintOption_12" 11 "MaintOption_11" 10 "MaintOption_10" 9 "MaintOption_9" 8 "MaintOption_8" 7 "MaintOption_7" 6 "MaintOption_6" 5 "MaintOption_5" 4 "MaintOption_4" 3 "MaintOption_3" 2 "MaintOption_2" 1 "MaintOption_1" 0 "MaintOption_0" ;
VAL_ 2147485065 MaintInfoGrp_Supported18 3 "NoYes_NotAvailable" 2 "NoYes_Error" 1 "NoYes_Yes" 0 "NoYes_No" ;
VAL_ 2147485065 MaintInfoGrp_Status22 7 "MaintenanceStatus_NotAvailable" 6 "MaintenanceStatus_Error" 5 "MaintenanceStatus_Spare_01" 4 "MaintenanceStatus_InProgress" 3 "MaintenanceStatus_Spare" 2 "MaintenanceStatus_Warning" 1 "MaintenanceStatus_PreWarning" 0 "MaintenanceStatus_OK" ;
VAL_ 2147485065 MaintInfoGrp_Status30 7 "MaintenanceStatus_NotAvailable" 6 "MaintenanceStatus_Error" 5 "MaintenanceStatus_Spare_01" 4 "MaintenanceStatus_InProgress" 3 "MaintenanceStatus_Spare" 2 "MaintenanceStatus_Warning" 1 "MaintenanceStatus_PreWarning" 0 "MaintenanceStatus_OK" ;
VAL_ 2147485065 MaintInfoGrp_Status20 7 "MaintenanceStatus_NotAvailable" 6 "MaintenanceStatus_Error" 5 "MaintenanceStatus_Spare_01" 4 "MaintenanceStatus_InProgress" 3 "MaintenanceStatus_Spare" 2 "MaintenanceStatus_Warning" 1 "MaintenanceStatus_PreWarning" 0 "MaintenanceStatus_OK" ;
VAL_ 2147485065 MaintInfoGrp_Status38 7 "MaintenanceStatus_NotAvailable" 6 "MaintenanceStatus_Error" 5 "MaintenanceStatus_Spare_01" 4 "MaintenanceStatus_InProgress" 3 "MaintenanceStatus_Spare" 2 "MaintenanceStatus_Warning" 1 "MaintenanceStatus_PreWarning" 0 "MaintenanceStatus_OK" ;
VAL_ 2147485065 MaintInfoGrp_ResetAuthorized7 3 "NoYes_NotAvailable" 2 "NoYes_Error" 1 "NoYes_Yes" 0 "NoYes_No" ;
VAL_ 2147485065 MaintInfoGrp_ResetAuthorized19 3 "NoYes_NotAvailable" 2 "NoYes_Error" 1 "NoYes_Yes" 0 "NoYes_No" ;
VAL_ 2147485065 MaintInfoGrp_ResetAuthorized12 3 "NoYes_NotAvailable" 2 "NoYes_Error" 1 "NoYes_Yes" 0 "NoYes_No" ;
VAL_ 2147485065 MaintInfoGrp_MaintOption8 15 "MaintOption_NotAvailable" 14 "MaintOption_Error" 13 "MaintOption_13" 12 "MaintOption_12" 11 "MaintOption_11" 10 "MaintOption_10" 9 "MaintOption_9" 8 "MaintOption_8" 7 "MaintOption_7" 6 "MaintOption_6" 5 "MaintOption_5" 4 "MaintOption_4" 3 "MaintOption_3" 2 "MaintOption_2" 1 "MaintOption_1" 0 "MaintOption_0" ;
VAL_ 2147485065 MaintInfoGrp_MaintOption9 15 "MaintOption_NotAvailable" 14 "MaintOption_Error" 13 "MaintOption_13" 12 "MaintOption_12" 11 "MaintOption_11" 10 "MaintOption_10" 9 "MaintOption_9" 8 "MaintOption_8" 7 "MaintOption_7" 6 "MaintOption_6" 5 "MaintOption_5" 4 "MaintOption_4" 3 "MaintOption_3" 2 "MaintOption_2" 1 "MaintOption_1" 0 "MaintOption_0" ;
VAL_ 2147485065 MaintInfoGrp_ResetAuthorized13 3 "NoYes_NotAvailable" 2 "NoYes_Error" 1 "NoYes_Yes" 0 "NoYes_No" ;
VAL_ 2147485065 MaintInfoGrp_Unit31 7 "MaintenanceUnit_NotAvailable" 6 "MaintenanceUnit_Error" 5 "MaintenanceUnit_None" 4 "MaintenanceUnit_AxleNumber" 3 "MaintenanceUnit_Percentage" 2 "MaintenanceUnit_Date" 1 "MaintenanceUnit_Distance" 0 "MaintenanceUnit_EngineTime" ;
VAL_ 2147485065 MaintInfoGrp_Status2 7 "MaintenanceStatus_NotAvailable" 6 "MaintenanceStatus_Error" 5 "MaintenanceStatus_Spare_01" 4 "MaintenanceStatus_InProgress" 3 "MaintenanceStatus_Spare" 2 "MaintenanceStatus_Warning" 1 "MaintenanceStatus_PreWarning" 0 "MaintenanceStatus_OK" ;
VAL_ 2147485065 MaintInfoGrp_ResetAuthorized5 3 "NoYes_NotAvailable" 2 "NoYes_Error" 1 "NoYes_Yes" 0 "NoYes_No" ;
VAL_ 2147485065 MaintInfoGrp_Supported33 3 "NoYes_NotAvailable" 2 "NoYes_Error" 1 "NoYes_Yes" 0 "NoYes_No" ;
VAL_ 2147485065 MaintInfoGrp_Unit7 7 "MaintenanceUnit_NotAvailable" 6 "MaintenanceUnit_Error" 5 "MaintenanceUnit_None" 4 "MaintenanceUnit_AxleNumber" 3 "MaintenanceUnit_Percentage" 2 "MaintenanceUnit_Date" 1 "MaintenanceUnit_Distance" 0 "MaintenanceUnit_EngineTime" ;
VAL_ 2147485065 MaintInfoGrp_Supported34 3 "NoYes_NotAvailable" 2 "NoYes_Error" 1 "NoYes_Yes" 0 "NoYes_No" ;
VAL_ 2147485065 MaintInfoGrp_Unit19 7 "MaintenanceUnit_NotAvailable" 6 "MaintenanceUnit_Error" 5 "MaintenanceUnit_None" 4 "MaintenanceUnit_AxleNumber" 3 "MaintenanceUnit_Percentage" 2 "MaintenanceUnit_Date" 1 "MaintenanceUnit_Distance" 0 "MaintenanceUnit_EngineTime" ;
VAL_ 2147485065 MaintInfoGrp_ResetAuthorized21 3 "NoYes_NotAvailable" 2 "NoYes_Error" 1 "NoYes_Yes" 0 "NoYes_No" ;
VAL_ 2147485065 MaintInfoGrp_ResetAuthorized31 3 "NoYes_NotAvailable" 2 "NoYes_Error" 1 "NoYes_Yes" 0 "NoYes_No" ;
VAL_ 2147485065 MaintInfoGrp_ResetAuthorized3 3 "NoYes_NotAvailable" 2 "NoYes_Error" 1 "NoYes_Yes" 0 "NoYes_No" ;
VAL_ 2147485065 MaintInfoGrp_MaintOption34 15 "MaintOption_NotAvailable" 14 "MaintOption_Error" 13 "MaintOption_13" 12 "MaintOption_12" 11 "MaintOption_11" 10 "MaintOption_10" 9 "MaintOption_9" 8 "MaintOption_8" 7 "MaintOption_7" 6 "MaintOption_6" 5 "MaintOption_5" 4 "MaintOption_4" 3 "MaintOption_3" 2 "MaintOption_2" 1 "MaintOption_1" 0 "MaintOption_0" ;
VAL_ 2147485065 MaintInfoGrp_Status21 7 "MaintenanceStatus_NotAvailable" 6 "MaintenanceStatus_Error" 5 "MaintenanceStatus_Spare_01" 4 "MaintenanceStatus_InProgress" 3 "MaintenanceStatus_Spare" 2 "MaintenanceStatus_Warning" 1 "MaintenanceStatus_PreWarning" 0 "MaintenanceStatus_OK" ;
VAL_ 2147485065 MaintInfoGrp_Unit21 7 "MaintenanceUnit_NotAvailable" 6 "MaintenanceUnit_Error" 5 "MaintenanceUnit_None" 4 "MaintenanceUnit_AxleNumber" 3 "MaintenanceUnit_Percentage" 2 "MaintenanceUnit_Date" 1 "MaintenanceUnit_Distance" 0 "MaintenanceUnit_EngineTime" ;
VAL_ 2147485065 MaintInfoGrp_MaintOption24 15 "MaintOption_NotAvailable" 14 "MaintOption_Error" 13 "MaintOption_13" 12 "MaintOption_12" 11 "MaintOption_11" 10 "MaintOption_10" 9 "MaintOption_9" 8 "MaintOption_8" 7 "MaintOption_7" 6 "MaintOption_6" 5 "MaintOption_5" 4 "MaintOption_4" 3 "MaintOption_3" 2 "MaintOption_2" 1 "MaintOption_1" 0 "MaintOption_0" ;
VAL_ 2147485065 MaintInfoGrp_Supported17 3 "NoYes_NotAvailable" 2 "NoYes_Error" 1 "NoYes_Yes" 0 "NoYes_No" ;
VAL_ 2147485065 MaintInfoGrp_ResetAuthorized17 3 "NoYes_NotAvailable" 2 "NoYes_Error" 1 "NoYes_Yes" 0 "NoYes_No" ;
VAL_ 2147485065 MaintInfoGrp_Unit25 7 "MaintenanceUnit_NotAvailable" 6 "MaintenanceUnit_Error" 5 "MaintenanceUnit_None" 4 "MaintenanceUnit_AxleNumber" 3 "MaintenanceUnit_Percentage" 2 "MaintenanceUnit_Date" 1 "MaintenanceUnit_Distance" 0 "MaintenanceUnit_EngineTime" ;
VAL_ 2147485065 MaintInfoGrp_Unit37 7 "MaintenanceUnit_NotAvailable" 6 "MaintenanceUnit_Error" 5 "MaintenanceUnit_None" 4 "MaintenanceUnit_AxleNumber" 3 "MaintenanceUnit_Percentage" 2 "MaintenanceUnit_Date" 1 "MaintenanceUnit_Distance" 0 "MaintenanceUnit_EngineTime" ;
VAL_ 2147485065 MaintInfoGrp_MaintOption2 15 "MaintOption_NotAvailable" 14 "MaintOption_Error" 13 "MaintOption_13" 12 "MaintOption_12" 11 "MaintOption_11" 10 "MaintOption_10" 9 "MaintOption_9" 8 "MaintOption_8" 7 "MaintOption_7" 6 "MaintOption_6" 5 "MaintOption_5" 4 "MaintOption_4" 3 "MaintOption_3" 2 "MaintOption_2" 1 "MaintOption_1" 0 "MaintOption_0" ;
VAL_ 2147485065 MaintInfoGrp_Supported21 3 "NoYes_NotAvailable" 2 "NoYes_Error" 1 "NoYes_Yes" 0 "NoYes_No" ;
VAL_ 2147485065 MaintInfoGrp_ResetAuthorized16 3 "NoYes_NotAvailable" 2 "NoYes_Error" 1 "NoYes_Yes" 0 "NoYes_No" ;
VAL_ 2147485065 MaintInfoGrp_Supported15 3 "NoYes_NotAvailable" 2 "NoYes_Error" 1 "NoYes_Yes" 0 "NoYes_No" ;
VAL_ 2147485065 MaintInfoGrp_ResetAuthorized9 3 "NoYes_NotAvailable" 2 "NoYes_Error" 1 "NoYes_Yes" 0 "NoYes_No" ;
VAL_ 2147485065 MaintInfoGrp_MaintOption18 15 "MaintOption_NotAvailable" 14 "MaintOption_Error" 13 "MaintOption_13" 12 "MaintOption_12" 11 "MaintOption_11" 10 "MaintOption_10" 9 "MaintOption_9" 8 "MaintOption_8" 7 "MaintOption_7" 6 "MaintOption_6" 5 "MaintOption_5" 4 "MaintOption_4" 3 "MaintOption_3" 2 "MaintOption_2" 1 "MaintOption_1" 0 "MaintOption_0" ;
VAL_ 2147485065 MaintInfoGrp_Supported29 3 "NoYes_NotAvailable" 2 "NoYes_Error" 1 "NoYes_Yes" 0 "NoYes_No" ;
VAL_ 2147485065 MaintInfoGrp_ResetAuthorized39 3 "NoYes_NotAvailable" 2 "NoYes_Error" 1 "NoYes_Yes" 0 "NoYes_No" ;
VAL_ 2147485065 MaintInfoGrp_Supported32 3 "NoYes_NotAvailable" 2 "NoYes_Error" 1 "NoYes_Yes" 0 "NoYes_No" ;
VAL_ 2147485065 MaintInfoGrp_ResetAuthorized35 3 "NoYes_NotAvailable" 2 "NoYes_Error" 1 "NoYes_Yes" 0 "NoYes_No" ;
VAL_ 2147485065 MaintInfoGrp_ResetAuthorized29 3 "NoYes_NotAvailable" 2 "NoYes_Error" 1 "NoYes_Yes" 0 "NoYes_No" ;
VAL_ 2147485065 MaintInfoGrp_Supported35 3 "NoYes_NotAvailable" 2 "NoYes_Error" 1 "NoYes_Yes" 0 "NoYes_No" ;
VAL_ 2147485065 MaintInfoGrp_ResetAuthorized4 3 "NoYes_NotAvailable" 2 "NoYes_Error" 1 "NoYes_Yes" 0 "NoYes_No" ;
VAL_ 2147485065 MaintInfoGrp_Unit1 7 "MaintenanceUnit_NotAvailable" 6 "MaintenanceUnit_Error" 5 "MaintenanceUnit_None" 4 "MaintenanceUnit_AxleNumber" 3 "MaintenanceUnit_Percentage" 2 "MaintenanceUnit_Date" 1 "MaintenanceUnit_Distance" 0 "MaintenanceUnit_EngineTime" ;
VAL_ 2147485065 MaintInfoGrp_MaintOption7 15 "MaintOption_NotAvailable" 14 "MaintOption_Error" 13 "MaintOption_13" 12 "MaintOption_12" 11 "MaintOption_11" 10 "MaintOption_10" 9 "MaintOption_9" 8 "MaintOption_8" 7 "MaintOption_7" 6 "MaintOption_6" 5 "MaintOption_5" 4 "MaintOption_4" 3 "MaintOption_3" 2 "MaintOption_2" 1 "MaintOption_1" 0 "MaintOption_0" ;
VAL_ 2147485065 MaintInfoGrp_Supported24 3 "NoYes_NotAvailable" 2 "NoYes_Error" 1 "NoYes_Yes" 0 "NoYes_No" ;
VAL_ 2147485065 MaintInfoGrp_Supported25 3 "NoYes_NotAvailable" 2 "NoYes_Error" 1 "NoYes_Yes" 0 "NoYes_No" ;
VAL_ 2147485065 MaintInfoGrp_Unit15 7 "MaintenanceUnit_NotAvailable" 6 "MaintenanceUnit_Error" 5 "MaintenanceUnit_None" 4 "MaintenanceUnit_AxleNumber" 3 "MaintenanceUnit_Percentage" 2 "MaintenanceUnit_Date" 1 "MaintenanceUnit_Distance" 0 "MaintenanceUnit_EngineTime" ;
VAL_ 2147485065 MaintInfoGrp_Supported1 3 "NoYes_NotAvailable" 2 "NoYes_Error" 1 "NoYes_Yes" 0 "NoYes_No" ;
VAL_ 2147485065 MaintInfoGrp_ResetAuthorized11 3 "NoYes_NotAvailable" 2 "NoYes_Error" 1 "NoYes_Yes" 0 "NoYes_No" ;
VAL_ 2147485065 MaintInfoGrp_Supported13 3 "NoYes_NotAvailable" 2 "NoYes_Error" 1 "NoYes_Yes" 0 "NoYes_No" ;
VAL_ 2147485065 MaintInfoGrp_Supported10 3 "NoYes_NotAvailable" 2 "NoYes_Error" 1 "NoYes_Yes" 0 "NoYes_No" ;
VAL_ 2147485065 MaintInfoGrp_Unit16 7 "MaintenanceUnit_NotAvailable" 6 "MaintenanceUnit_Error" 5 "MaintenanceUnit_None" 4 "MaintenanceUnit_AxleNumber" 3 "MaintenanceUnit_Percentage" 2 "MaintenanceUnit_Date" 1 "MaintenanceUnit_Distance" 0 "MaintenanceUnit_EngineTime" ;
VAL_ 2147485065 MaintInfoGrp_MaintOption35 15 "MaintOption_NotAvailable" 14 "MaintOption_Error" 13 "MaintOption_13" 12 "MaintOption_12" 11 "MaintOption_11" 10 "MaintOption_10" 9 "MaintOption_9" 8 "MaintOption_8" 7 "MaintOption_7" 6 "MaintOption_6" 5 "MaintOption_5" 4 "MaintOption_4" 3 "MaintOption_3" 2 "MaintOption_2" 1 "MaintOption_1" 0 "MaintOption_0" ;
VAL_ 2147485065 MaintInfoGrp_MaintOption22 15 "MaintOption_NotAvailable" 14 "MaintOption_Error" 13 "MaintOption_13" 12 "MaintOption_12" 11 "MaintOption_11" 10 "MaintOption_10" 9 "MaintOption_9" 8 "MaintOption_8" 7 "MaintOption_7" 6 "MaintOption_6" 5 "MaintOption_5" 4 "MaintOption_4" 3 "MaintOption_3" 2 "MaintOption_2" 1 "MaintOption_1" 0 "MaintOption_0" ;
VAL_ 2147485065 MaintInfoGrp_MaintOption12 15 "MaintOption_NotAvailable" 14 "MaintOption_Error" 13 "MaintOption_13" 12 "MaintOption_12" 11 "MaintOption_11" 10 "MaintOption_10" 9 "MaintOption_9" 8 "MaintOption_8" 7 "MaintOption_7" 6 "MaintOption_6" 5 "MaintOption_5" 4 "MaintOption_4" 3 "MaintOption_3" 2 "MaintOption_2" 1 "MaintOption_1" 0 "MaintOption_0" ;
VAL_ 2147485065 MaintInfoGrp_Supported9 3 "NoYes_NotAvailable" 2 "NoYes_Error" 1 "NoYes_Yes" 0 "NoYes_No" ;
VAL_ 2147485065 MaintInfoGrp_Supported31 3 "NoYes_NotAvailable" 2 "NoYes_Error" 1 "NoYes_Yes" 0 "NoYes_No" ;
VAL_ 2147485065 MaintInfoGrp_MaintOption37 15 "MaintOption_NotAvailable" 14 "MaintOption_Error" 13 "MaintOption_13" 12 "MaintOption_12" 11 "MaintOption_11" 10 "MaintOption_10" 9 "MaintOption_9" 8 "MaintOption_8" 7 "MaintOption_7" 6 "MaintOption_6" 5 "MaintOption_5" 4 "MaintOption_4" 3 "MaintOption_3" 2 "MaintOption_2" 1 "MaintOption_1" 0 "MaintOption_0" ;
VAL_ 2147485065 MaintInfoGrp_MaintOption13 15 "MaintOption_NotAvailable" 14 "MaintOption_Error" 13 "MaintOption_13" 12 "MaintOption_12" 11 "MaintOption_11" 10 "MaintOption_10" 9 "MaintOption_9" 8 "MaintOption_8" 7 "MaintOption_7" 6 "MaintOption_6" 5 "MaintOption_5" 4 "MaintOption_4" 3 "MaintOption_3" 2 "MaintOption_2" 1 "MaintOption_1" 0 "MaintOption_0" ;
VAL_ 2147485065 MaintInfoGrp_ResetAuthorized22 3 "NoYes_NotAvailable" 2 "NoYes_Error" 1 "NoYes_Yes" 0 "NoYes_No" ;
VAL_ 2147485065 MaintInfoGrp_Status14 7 "MaintenanceStatus_NotAvailable" 6 "MaintenanceStatus_Error" 5 "MaintenanceStatus_Spare_01" 4 "MaintenanceStatus_InProgress" 3 "MaintenanceStatus_Spare" 2 "MaintenanceStatus_Warning" 1 "MaintenanceStatus_PreWarning" 0 "MaintenanceStatus_OK" ;
VAL_ 2147485065 MaintInfoGrp_Status18 7 "MaintenanceStatus_NotAvailable" 6 "MaintenanceStatus_Error" 5 "MaintenanceStatus_Spare_01" 4 "MaintenanceStatus_InProgress" 3 "MaintenanceStatus_Spare" 2 "MaintenanceStatus_Warning" 1 "MaintenanceStatus_PreWarning" 0 "MaintenanceStatus_OK" ;
VAL_ 2147485065 MaintInfoGrp_Unit17 7 "MaintenanceUnit_NotAvailable" 6 "MaintenanceUnit_Error" 5 "MaintenanceUnit_None" 4 "MaintenanceUnit_AxleNumber" 3 "MaintenanceUnit_Percentage" 2 "MaintenanceUnit_Date" 1 "MaintenanceUnit_Distance" 0 "MaintenanceUnit_EngineTime" ;
VAL_ 2147485065 MaintInfoGrp_Unit12 7 "MaintenanceUnit_NotAvailable" 6 "MaintenanceUnit_Error" 5 "MaintenanceUnit_None" 4 "MaintenanceUnit_AxleNumber" 3 "MaintenanceUnit_Percentage" 2 "MaintenanceUnit_Date" 1 "MaintenanceUnit_Distance" 0 "MaintenanceUnit_EngineTime" ;
VAL_ 2147485065 MaintInfoGrp_Supported27 3 "NoYes_NotAvailable" 2 "NoYes_Error" 1 "NoYes_Yes" 0 "NoYes_No" ;
VAL_ 2147485065 MaintInfoGrp_Unit4 7 "MaintenanceUnit_NotAvailable" 6 "MaintenanceUnit_Error" 5 "MaintenanceUnit_None" 4 "MaintenanceUnit_AxleNumber" 3 "MaintenanceUnit_Percentage" 2 "MaintenanceUnit_Date" 1 "MaintenanceUnit_Distance" 0 "MaintenanceUnit_EngineTime" ;
VAL_ 2147485065 MaintInfoGrp_Status27 7 "MaintenanceStatus_NotAvailable" 6 "MaintenanceStatus_Error" 5 "MaintenanceStatus_Spare_01" 4 "MaintenanceStatus_InProgress" 3 "MaintenanceStatus_Spare" 2 "MaintenanceStatus_Warning" 1 "MaintenanceStatus_PreWarning" 0 "MaintenanceStatus_OK" ;
VAL_ 2147485065 MaintInfoGrp_MaintOption29 15 "MaintOption_NotAvailable" 14 "MaintOption_Error" 13 "MaintOption_13" 12 "MaintOption_12" 11 "MaintOption_11" 10 "MaintOption_10" 9 "MaintOption_9" 8 "MaintOption_8" 7 "MaintOption_7" 6 "MaintOption_6" 5 "MaintOption_5" 4 "MaintOption_4" 3 "MaintOption_3" 2 "MaintOption_2" 1 "MaintOption_1" 0 "MaintOption_0" ;
VAL_ 2147485065 MaintInfoGrp_Unit9 7 "MaintenanceUnit_NotAvailable" 6 "MaintenanceUnit_Error" 5 "MaintenanceUnit_None" 4 "MaintenanceUnit_AxleNumber" 3 "MaintenanceUnit_Percentage" 2 "MaintenanceUnit_Date" 1 "MaintenanceUnit_Distance" 0 "MaintenanceUnit_EngineTime" ;
VAL_ 2147485065 MaintInfoGrp_Unit13 7 "MaintenanceUnit_NotAvailable" 6 "MaintenanceUnit_Error" 5 "MaintenanceUnit_None" 4 "MaintenanceUnit_AxleNumber" 3 "MaintenanceUnit_Percentage" 2 "MaintenanceUnit_Date" 1 "MaintenanceUnit_Distance" 0 "MaintenanceUnit_EngineTime" ;
VAL_ 2147485065 MaintInfoGrp_Unit3 7 "MaintenanceUnit_NotAvailable" 6 "MaintenanceUnit_Error" 5 "MaintenanceUnit_None" 4 "MaintenanceUnit_AxleNumber" 3 "MaintenanceUnit_Percentage" 2 "MaintenanceUnit_Date" 1 "MaintenanceUnit_Distance" 0 "MaintenanceUnit_EngineTime" ;
VAL_ 2147485065 MaintInfoGrp_MaintOption15 15 "MaintOption_NotAvailable" 14 "MaintOption_Error" 13 "MaintOption_13" 12 "MaintOption_12" 11 "MaintOption_11" 10 "MaintOption_10" 9 "MaintOption_9" 8 "MaintOption_8" 7 "MaintOption_7" 6 "MaintOption_6" 5 "MaintOption_5" 4 "MaintOption_4" 3 "MaintOption_3" 2 "MaintOption_2" 1 "MaintOption_1" 0 "MaintOption_0" ;
VAL_ 2147485065 MaintInfoGrp_ResetAuthorized15 3 "NoYes_NotAvailable" 2 "NoYes_Error" 1 "NoYes_Yes" 0 "NoYes_No" ;
VAL_ 2147485065 MaintInfoGrp_MaintOption11 15 "MaintOption_NotAvailable" 14 "MaintOption_Error" 13 "MaintOption_13" 12 "MaintOption_12" 11 "MaintOption_11" 10 "MaintOption_10" 9 "MaintOption_9" 8 "MaintOption_8" 7 "MaintOption_7" 6 "MaintOption_6" 5 "MaintOption_5" 4 "MaintOption_4" 3 "MaintOption_3" 2 "MaintOption_2" 1 "MaintOption_1" 0 "MaintOption_0" ;
VAL_ 2147485065 MaintInfoGrp_MaintOption25 15 "MaintOption_NotAvailable" 14 "MaintOption_Error" 13 "MaintOption_13" 12 "MaintOption_12" 11 "MaintOption_11" 10 "MaintOption_10" 9 "MaintOption_9" 8 "MaintOption_8" 7 "MaintOption_7" 6 "MaintOption_6" 5 "MaintOption_5" 4 "MaintOption_4" 3 "MaintOption_3" 2 "MaintOption_2" 1 "MaintOption_1" 0 "MaintOption_0" ;
VAL_ 2147485065 MaintInfoGrp_Supported16 3 "NoYes_NotAvailable" 2 "NoYes_Error" 1 "NoYes_Yes" 0 "NoYes_No" ;
VAL_ 2147485065 MaintInfoGrp_Supported23 3 "NoYes_NotAvailable" 2 "NoYes_Error" 1 "NoYes_Yes" 0 "NoYes_No" ;
VAL_ 2147485065 MaintInfoGrp_Status13 7 "MaintenanceStatus_NotAvailable" 6 "MaintenanceStatus_Error" 5 "MaintenanceStatus_Spare_01" 4 "MaintenanceStatus_InProgress" 3 "MaintenanceStatus_Spare" 2 "MaintenanceStatus_Warning" 1 "MaintenanceStatus_PreWarning" 0 "MaintenanceStatus_OK" ;
VAL_ 2147485065 MaintInfoGrp_Status17 7 "MaintenanceStatus_NotAvailable" 6 "MaintenanceStatus_Error" 5 "MaintenanceStatus_Spare_01" 4 "MaintenanceStatus_InProgress" 3 "MaintenanceStatus_Spare" 2 "MaintenanceStatus_Warning" 1 "MaintenanceStatus_PreWarning" 0 "MaintenanceStatus_OK" ;
VAL_ 2147485065 MaintInfoGrp_Unit8 7 "MaintenanceUnit_NotAvailable" 6 "MaintenanceUnit_Error" 5 "MaintenanceUnit_None" 4 "MaintenanceUnit_AxleNumber" 3 "MaintenanceUnit_Percentage" 2 "MaintenanceUnit_Date" 1 "MaintenanceUnit_Distance" 0 "MaintenanceUnit_EngineTime" ;
VAL_ 2147485065 MaintInfoGrp_MaintOption38 15 "MaintOption_NotAvailable" 14 "MaintOption_Error" 13 "MaintOption_13" 12 "MaintOption_12" 11 "MaintOption_11" 10 "MaintOption_10" 9 "MaintOption_9" 8 "MaintOption_8" 7 "MaintOption_7" 6 "MaintOption_6" 5 "MaintOption_5" 4 "MaintOption_4" 3 "MaintOption_3" 2 "MaintOption_2" 1 "MaintOption_1" 0 "MaintOption_0" ;
VAL_ 2147485065 MaintInfoGrp_Supported2 3 "NoYes_NotAvailable" 2 "NoYes_Error" 1 "NoYes_Yes" 0 "NoYes_No" ;
VAL_ 2147485065 MaintInfoGrp_ResetAuthorized0 3 "NoYes_NotAvailable" 2 "NoYes_Error" 1 "NoYes_Yes" 0 "NoYes_No" ;
VAL_ 2147485065 MaintInfoGrp_Supported5 3 "NoYes_NotAvailable" 2 "NoYes_Error" 1 "NoYes_Yes" 0 "NoYes_No" ;
VAL_ 2147485065 MaintInfoGrp_Status6 7 "MaintenanceStatus_NotAvailable" 6 "MaintenanceStatus_Error" 5 "MaintenanceStatus_Spare_01" 4 "MaintenanceStatus_InProgress" 3 "MaintenanceStatus_Spare" 2 "MaintenanceStatus_Warning" 1 "MaintenanceStatus_PreWarning" 0 "MaintenanceStatus_OK" ;
VAL_ 2147485065 MaintInfoGrp_Unit5 7 "MaintenanceUnit_NotAvailable" 6 "MaintenanceUnit_Error" 5 "MaintenanceUnit_None" 4 "MaintenanceUnit_AxleNumber" 3 "MaintenanceUnit_Percentage" 2 "MaintenanceUnit_Date" 1 "MaintenanceUnit_Distance" 0 "MaintenanceUnit_EngineTime" ;
VAL_ 2147485065 MaintInfoGrp_Supported28 3 "NoYes_NotAvailable" 2 "NoYes_Error" 1 "NoYes_Yes" 0 "NoYes_No" ;
VAL_ 2147485065 MaintInfoGrp_Status32 7 "MaintenanceStatus_NotAvailable" 6 "MaintenanceStatus_Error" 5 "MaintenanceStatus_Spare_01" 4 "MaintenanceStatus_InProgress" 3 "MaintenanceStatus_Spare" 2 "MaintenanceStatus_Warning" 1 "MaintenanceStatus_PreWarning" 0 "MaintenanceStatus_OK" ;
VAL_ 2147485065 MaintInfoGrp_MaintOption0 15 "MaintOption_NotAvailable" 14 "MaintOption_Error" 13 "MaintOption_13" 12 "MaintOption_12" 11 "MaintOption_11" 10 "MaintOption_10" 9 "MaintOption_9" 8 "MaintOption_8" 7 "MaintOption_7" 6 "MaintOption_6" 5 "MaintOption_5" 4 "MaintOption_4" 3 "MaintOption_3" 2 "MaintOption_2" 1 "MaintOption_1" 0 "MaintOption_0" ;
VAL_ 2147485065 MaintInfoGrp_ResetAuthorized25 3 "NoYes_NotAvailable" 2 "NoYes_Error" 1 "NoYes_Yes" 0 "NoYes_No" ;
VAL_ 2147485065 MaintInfoGrp_MaintOption32 15 "MaintOption_NotAvailable" 14 "MaintOption_Error" 13 "MaintOption_13" 12 "MaintOption_12" 11 "MaintOption_11" 10 "MaintOption_10" 9 "MaintOption_9" 8 "MaintOption_8" 7 "MaintOption_7" 6 "MaintOption_6" 5 "MaintOption_5" 4 "MaintOption_4" 3 "MaintOption_3" 2 "MaintOption_2" 1 "MaintOption_1" 0 "MaintOption_0" ;
VAL_ 2147485065 MaintInfoGrp_Unit11 7 "MaintenanceUnit_NotAvailable" 6 "MaintenanceUnit_Error" 5 "MaintenanceUnit_None" 4 "MaintenanceUnit_AxleNumber" 3 "MaintenanceUnit_Percentage" 2 "MaintenanceUnit_Date" 1 "MaintenanceUnit_Distance" 0 "MaintenanceUnit_EngineTime" ;
VAL_ 2147485065 MaintInfoGrp_MaintOption4 15 "MaintOption_NotAvailable" 14 "MaintOption_Error" 13 "MaintOption_13" 12 "MaintOption_12" 11 "MaintOption_11" 10 "MaintOption_10" 9 "MaintOption_9" 8 "MaintOption_8" 7 "MaintOption_7" 6 "MaintOption_6" 5 "MaintOption_5" 4 "MaintOption_4" 3 "MaintOption_3" 2 "MaintOption_2" 1 "MaintOption_1" 0 "MaintOption_0" ;
VAL_ 2147485065 MaintInfoGrp_Supported38 3 "NoYes_NotAvailable" 2 "NoYes_Error" 1 "NoYes_Yes" 0 "NoYes_No" ;
VAL_ 2147485065 MaintInfoGrp_MaintOption1 15 "MaintOption_NotAvailable" 14 "MaintOption_Error" 13 "MaintOption_13" 12 "MaintOption_12" 11 "MaintOption_11" 10 "MaintOption_10" 9 "MaintOption_9" 8 "MaintOption_8" 7 "MaintOption_7" 6 "MaintOption_6" 5 "MaintOption_5" 4 "MaintOption_4" 3 "MaintOption_3" 2 "MaintOption_2" 1 "MaintOption_1" 0 "MaintOption_0" ;
VAL_ 2147485065 MaintInfoGrp_Supported30 3 "NoYes_NotAvailable" 2 "NoYes_Error" 1 "NoYes_Yes" 0 "NoYes_No" ;
VAL_ 2147485065 MaintInfoGrp_ResetAuthorized33 3 "NoYes_NotAvailable" 2 "NoYes_Error" 1 "NoYes_Yes" 0 "NoYes_No" ;
VAL_ 2147485065 MaintInfoGrp_Status0 7 "MaintenanceStatus_NotAvailable" 6 "MaintenanceStatus_Error" 5 "MaintenanceStatus_Spare_01" 4 "MaintenanceStatus_InProgress" 3 "MaintenanceStatus_Spare" 2 "MaintenanceStatus_Warning" 1 "MaintenanceStatus_PreWarning" 0 "MaintenanceStatus_OK" ;
VAL_ 2147485065 MaintInfoGrp_ResetAuthorized20 3 "NoYes_NotAvailable" 2 "NoYes_Error" 1 "NoYes_Yes" 0 "NoYes_No" ;
VAL_ 2147485065 MaintInfoGrp_Unit33 7 "MaintenanceUnit_NotAvailable" 6 "MaintenanceUnit_Error" 5 "MaintenanceUnit_None" 4 "MaintenanceUnit_AxleNumber" 3 "MaintenanceUnit_Percentage" 2 "MaintenanceUnit_Date" 1 "MaintenanceUnit_Distance" 0 "MaintenanceUnit_EngineTime" ;
VAL_ 2147485065 MaintInfoGrp_Supported26 3 "NoYes_NotAvailable" 2 "NoYes_Error" 1 "NoYes_Yes" 0 "NoYes_No" ;
VAL_ 2147485065 MaintInfoGrp_ResetAuthorized6 3 "NoYes_NotAvailable" 2 "NoYes_Error" 1 "NoYes_Yes" 0 "NoYes_No" ;
VAL_ 2147485065 MaintInfoGrp_Status16 7 "MaintenanceStatus_NotAvailable" 6 "MaintenanceStatus_Error" 5 "MaintenanceStatus_Spare_01" 4 "MaintenanceStatus_InProgress" 3 "MaintenanceStatus_Spare" 2 "MaintenanceStatus_Warning" 1 "MaintenanceStatus_PreWarning" 0 "MaintenanceStatus_OK" ;
VAL_ 2147485065 MaintInfoGrp_ResetAuthorized18 3 "NoYes_NotAvailable" 2 "NoYes_Error" 1 "NoYes_Yes" 0 "NoYes_No" ;
VAL_ 2147485065 MaintInfoGrp_Status4 7 "MaintenanceStatus_NotAvailable" 6 "MaintenanceStatus_Error" 5 "MaintenanceStatus_Spare_01" 4 "MaintenanceStatus_InProgress" 3 "MaintenanceStatus_Spare" 2 "MaintenanceStatus_Warning" 1 "MaintenanceStatus_PreWarning" 0 "MaintenanceStatus_OK" ;
VAL_ 2147485065 MaintInfoGrp_MaintOption20 15 "MaintOption_NotAvailable" 14 "MaintOption_Error" 13 "MaintOption_13" 12 "MaintOption_12" 11 "MaintOption_11" 10 "MaintOption_10" 9 "MaintOption_9" 8 "MaintOption_8" 7 "MaintOption_7" 6 "MaintOption_6" 5 "MaintOption_5" 4 "MaintOption_4" 3 "MaintOption_3" 2 "MaintOption_2" 1 "MaintOption_1" 0 "MaintOption_0" ;
VAL_ 2147485065 MaintInfoGrp_ResetAuthorized30 3 "NoYes_NotAvailable" 2 "NoYes_Error" 1 "NoYes_Yes" 0 "NoYes_No" ;
VAL_ 2147485065 MaintInfoGrp_ResetAuthorized23 3 "NoYes_NotAvailable" 2 "NoYes_Error" 1 "NoYes_Yes" 0 "NoYes_No" ;
VAL_ 2147485065 MaintInfoGrp_Unit30 7 "MaintenanceUnit_NotAvailable" 6 "MaintenanceUnit_Error" 5 "MaintenanceUnit_None" 4 "MaintenanceUnit_AxleNumber" 3 "MaintenanceUnit_Percentage" 2 "MaintenanceUnit_Date" 1 "MaintenanceUnit_Distance" 0 "MaintenanceUnit_EngineTime" ;
VAL_ 2147485065 MaintInfoGrp_MaintOption23 15 "MaintOption_NotAvailable" 14 "MaintOption_Error" 13 "MaintOption_13" 12 "MaintOption_12" 11 "MaintOption_11" 10 "MaintOption_10" 9 "MaintOption_9" 8 "MaintOption_8" 7 "MaintOption_7" 6 "MaintOption_6" 5 "MaintOption_5" 4 "MaintOption_4" 3 "MaintOption_3" 2 "MaintOption_2" 1 "MaintOption_1" 0 "MaintOption_0" ;
VAL_ 2147485065 MaintInfoGrp_Unit20 7 "MaintenanceUnit_NotAvailable" 6 "MaintenanceUnit_Error" 5 "MaintenanceUnit_None" 4 "MaintenanceUnit_AxleNumber" 3 "MaintenanceUnit_Percentage" 2 "MaintenanceUnit_Date" 1 "MaintenanceUnit_Distance" 0 "MaintenanceUnit_EngineTime" ;
VAL_ 2147485065 MaintInfoGrp_MaintOption10 15 "MaintOption_NotAvailable" 14 "MaintOption_Error" 13 "MaintOption_13" 12 "MaintOption_12" 11 "MaintOption_11" 10 "MaintOption_10" 9 "MaintOption_9" 8 "MaintOption_8" 7 "MaintOption_7" 6 "MaintOption_6" 5 "MaintOption_5" 4 "MaintOption_4" 3 "MaintOption_3" 2 "MaintOption_2" 1 "MaintOption_1" 0 "MaintOption_0" ;
VAL_ 2147485065 MaintInfoGrp_Status39 7 "MaintenanceStatus_NotAvailable" 6 "MaintenanceStatus_Error" 5 "MaintenanceStatus_Spare_01" 4 "MaintenanceStatus_InProgress" 3 "MaintenanceStatus_Spare" 2 "MaintenanceStatus_Warning" 1 "MaintenanceStatus_PreWarning" 0 "MaintenanceStatus_OK" ;
VAL_ 2147485065 MaintInfoGrp_Status3 7 "MaintenanceStatus_NotAvailable" 6 "MaintenanceStatus_Error" 5 "MaintenanceStatus_Spare_01" 4 "MaintenanceStatus_InProgress" 3 "MaintenanceStatus_Spare" 2 "MaintenanceStatus_Warning" 1 "MaintenanceStatus_PreWarning" 0 "MaintenanceStatus_OK" ;
VAL_ 2147485065 MaintInfoGrp_ResetAuthorized26 3 "NoYes_NotAvailable" 2 "NoYes_Error" 1 "NoYes_Yes" 0 "NoYes_No" ;
VAL_ 2147485065 MaintInfoGrp_Supported12 3 "NoYes_NotAvailable" 2 "NoYes_Error" 1 "NoYes_Yes" 0 "NoYes_No" ;
VAL_ 2147485065 MaintInfoGrp_Status29 7 "MaintenanceStatus_NotAvailable" 6 "MaintenanceStatus_Error" 5 "MaintenanceStatus_Spare_01" 4 "MaintenanceStatus_InProgress" 3 "MaintenanceStatus_Spare" 2 "MaintenanceStatus_Warning" 1 "MaintenanceStatus_PreWarning" 0 "MaintenanceStatus_OK" ;
VAL_ 2147485065 MaintInfoGrp_ResetAuthorized37 3 "NoYes_NotAvailable" 2 "NoYes_Error" 1 "NoYes_Yes" 0 "NoYes_No" ;
VAL_ 2147485065 MaintInfoGrp_Status36 7 "MaintenanceStatus_NotAvailable" 6 "MaintenanceStatus_Error" 5 "MaintenanceStatus_Spare_01" 4 "MaintenanceStatus_InProgress" 3 "MaintenanceStatus_Spare" 2 "MaintenanceStatus_Warning" 1 "MaintenanceStatus_PreWarning" 0 "MaintenanceStatus_OK" ;
VAL_ 2147485065 MaintInfoGrp_Supported22 3 "NoYes_NotAvailable" 2 "NoYes_Error" 1 "NoYes_Yes" 0 "NoYes_No" ;
VAL_ 2147485065 MaintInfoGrp_Status35 7 "MaintenanceStatus_NotAvailable" 6 "MaintenanceStatus_Error" 5 "MaintenanceStatus_Spare_01" 4 "MaintenanceStatus_InProgress" 3 "MaintenanceStatus_Spare" 2 "MaintenanceStatus_Warning" 1 "MaintenanceStatus_PreWarning" 0 "MaintenanceStatus_OK" ;
VAL_ 2147485065 MaintInfoGrp_MaintOption26 15 "MaintOption_NotAvailable" 14 "MaintOption_Error" 13 "MaintOption_13" 12 "MaintOption_12" 11 "MaintOption_11" 10 "MaintOption_10" 9 "MaintOption_9" 8 "MaintOption_8" 7 "MaintOption_7" 6 "MaintOption_6" 5 "MaintOption_5" 4 "MaintOption_4" 3 "MaintOption_3" 2 "MaintOption_2" 1 "MaintOption_1" 0 "MaintOption_0" ;
VAL_ 2147485065 MaintInfoGrp_Status23 7 "MaintenanceStatus_NotAvailable" 6 "MaintenanceStatus_Error" 5 "MaintenanceStatus_Spare_01" 4 "MaintenanceStatus_InProgress" 3 "MaintenanceStatus_Spare" 2 "MaintenanceStatus_Warning" 1 "MaintenanceStatus_PreWarning" 0 "MaintenanceStatus_OK" ;
VAL_ 2147485065 MaintInfoGrp_Unit35 7 "MaintenanceUnit_NotAvailable" 6 "MaintenanceUnit_Error" 5 "MaintenanceUnit_None" 4 "MaintenanceUnit_AxleNumber" 3 "MaintenanceUnit_Percentage" 2 "MaintenanceUnit_Date" 1 "MaintenanceUnit_Distance" 0 "MaintenanceUnit_EngineTime" ;
VAL_ 2147485065 MaintInfoGrp_Supported6 3 "NoYes_NotAvailable" 2 "NoYes_Error" 1 "NoYes_Yes" 0 "NoYes_No" ;
VAL_ 2147485065 MaintInfoGrp_Unit27 7 "MaintenanceUnit_NotAvailable" 6 "MaintenanceUnit_Error" 5 "MaintenanceUnit_None" 4 "MaintenanceUnit_AxleNumber" 3 "MaintenanceUnit_Percentage" 2 "MaintenanceUnit_Date" 1 "MaintenanceUnit_Distance" 0 "MaintenanceUnit_EngineTime" ;
VAL_ 2147485065 MaintInfoGrp_MaintOption19 15 "MaintOption_NotAvailable" 14 "MaintOption_Error" 13 "MaintOption_13" 12 "MaintOption_12" 11 "MaintOption_11" 10 "MaintOption_10" 9 "MaintOption_9" 8 "MaintOption_8" 7 "MaintOption_7" 6 "MaintOption_6" 5 "MaintOption_5" 4 "MaintOption_4" 3 "MaintOption_3" 2 "MaintOption_2" 1 "MaintOption_1" 0 "MaintOption_0" ;
VAL_ 2147485065 MaintInfoGrp_ResetAuthorized14 3 "NoYes_NotAvailable" 2 "NoYes_Error" 1 "NoYes_Yes" 0 "NoYes_No" ;
VAL_ 2147485065 MaintInfoGrp_Status34 7 "MaintenanceStatus_NotAvailable" 6 "MaintenanceStatus_Error" 5 "MaintenanceStatus_Spare_01" 4 "MaintenanceStatus_InProgress" 3 "MaintenanceStatus_Spare" 2 "MaintenanceStatus_Warning" 1 "MaintenanceStatus_PreWarning" 0 "MaintenanceStatus_OK" ;
VAL_ 2147485065 MaintInfoGrp_Supported37 3 "NoYes_NotAvailable" 2 "NoYes_Error" 1 "NoYes_Yes" 0 "NoYes_No" ;
VAL_ 2147485065 MaintInfoGrp_MaintOption3 15 "MaintOption_NotAvailable" 14 "MaintOption_Error" 13 "MaintOption_13" 12 "MaintOption_12" 11 "MaintOption_11" 10 "MaintOption_10" 9 "MaintOption_9" 8 "MaintOption_8" 7 "MaintOption_7" 6 "MaintOption_6" 5 "MaintOption_5" 4 "MaintOption_4" 3 "MaintOption_3" 2 "MaintOption_2" 1 "MaintOption_1" 0 "MaintOption_0" ;
VAL_ 2147485065 MaintInfoGrp_Status1 7 "MaintenanceStatus_NotAvailable" 6 "MaintenanceStatus_Error" 5 "MaintenanceStatus_Spare_01" 4 "MaintenanceStatus_InProgress" 3 "MaintenanceStatus_Spare" 2 "MaintenanceStatus_Warning" 1 "MaintenanceStatus_PreWarning" 0 "MaintenanceStatus_OK" ;
VAL_ 2147485065 MaintInfoGrp_Status25 7 "MaintenanceStatus_NotAvailable" 6 "MaintenanceStatus_Error" 5 "MaintenanceStatus_Spare_01" 4 "MaintenanceStatus_InProgress" 3 "MaintenanceStatus_Spare" 2 "MaintenanceStatus_Warning" 1 "MaintenanceStatus_PreWarning" 0 "MaintenanceStatus_OK" ;
VAL_ 2147485065 MaintInfoGrp_ResetAuthorized1 3 "NoYes_NotAvailable" 2 "NoYes_Error" 1 "NoYes_Yes" 0 "NoYes_No" ;
VAL_ 2147485065 MaintInfoGrp_ResetAuthorized27 3 "NoYes_NotAvailable" 2 "NoYes_Error" 1 "NoYes_Yes" 0 "NoYes_No" ;
VAL_ 2147485065 MaintInfoGrp_ResetAuthorized36 3 "NoYes_NotAvailable" 2 "NoYes_Error" 1 "NoYes_Yes" 0 "NoYes_No" ;
VAL_ 2147485065 MaintInfoGrp_Status28 7 "MaintenanceStatus_NotAvailable" 6 "MaintenanceStatus_Error" 5 "MaintenanceStatus_Spare_01" 4 "MaintenanceStatus_InProgress" 3 "MaintenanceStatus_Spare" 2 "MaintenanceStatus_Warning" 1 "MaintenanceStatus_PreWarning" 0 "MaintenanceStatus_OK" ;
VAL_ 2147485065 MaintInfoGrp_Status24 7 "MaintenanceStatus_NotAvailable" 6 "MaintenanceStatus_Error" 5 "MaintenanceStatus_Spare_01" 4 "MaintenanceStatus_InProgress" 3 "MaintenanceStatus_Spare" 2 "MaintenanceStatus_Warning" 1 "MaintenanceStatus_PreWarning" 0 "MaintenanceStatus_OK" ;
VAL_ 2147485065 MaintInfoGrp_MaintOption31 15 "MaintOption_NotAvailable" 14 "MaintOption_Error" 13 "MaintOption_13" 12 "MaintOption_12" 11 "MaintOption_11" 10 "MaintOption_10" 9 "MaintOption_9" 8 "MaintOption_8" 7 "MaintOption_7" 6 "MaintOption_6" 5 "MaintOption_5" 4 "MaintOption_4" 3 "MaintOption_3" 2 "MaintOption_2" 1 "MaintOption_1" 0 "MaintOption_0" ;
VAL_ 2147485065 MaintInfoGrp_Supported20 3 "NoYes_NotAvailable" 2 "NoYes_Error" 1 "NoYes_Yes" 0 "NoYes_No" ;
VAL_ 2147485065 MaintInfoGrp_Unit38 7 "MaintenanceUnit_NotAvailable" 6 "MaintenanceUnit_Error" 5 "MaintenanceUnit_None" 4 "MaintenanceUnit_AxleNumber" 3 "MaintenanceUnit_Percentage" 2 "MaintenanceUnit_Date" 1 "MaintenanceUnit_Distance" 0 "MaintenanceUnit_EngineTime" ;
VAL_ 2147485065 MaintInfoGrp_Unit24 7 "MaintenanceUnit_NotAvailable" 6 "MaintenanceUnit_Error" 5 "MaintenanceUnit_None" 4 "MaintenanceUnit_AxleNumber" 3 "MaintenanceUnit_Percentage" 2 "MaintenanceUnit_Date" 1 "MaintenanceUnit_Distance" 0 "MaintenanceUnit_EngineTime" ;
VAL_ 2147485065 MaintInfoGrp_Status37 7 "MaintenanceStatus_NotAvailable" 6 "MaintenanceStatus_Error" 5 "MaintenanceStatus_Spare_01" 4 "MaintenanceStatus_InProgress" 3 "MaintenanceStatus_Spare" 2 "MaintenanceStatus_Warning" 1 "MaintenanceStatus_PreWarning" 0 "MaintenanceStatus_OK" ;
VAL_ 2147485065 MaintInfoGrp_Supported39 3 "NoYes_NotAvailable" 2 "NoYes_Error" 1 "NoYes_Yes" 0 "NoYes_No" ;
VAL_ 2147485065 MaintInfoGrp_MaintOption39 15 "MaintOption_NotAvailable" 14 "MaintOption_Error" 13 "MaintOption_13" 12 "MaintOption_12" 11 "MaintOption_11" 10 "MaintOption_10" 9 "MaintOption_9" 8 "MaintOption_8" 7 "MaintOption_7" 6 "MaintOption_6" 5 "MaintOption_5" 4 "MaintOption_4" 3 "MaintOption_3" 2 "MaintOption_2" 1 "MaintOption_1" 0 "MaintOption_0" ;
VAL_ 2147485065 MaintInfoGrp_Supported4 3 "NoYes_NotAvailable" 2 "NoYes_Error" 1 "NoYes_Yes" 0 "NoYes_No" ;
VAL_ 2147485065 MaintInfoGrp_Supported3 3 "NoYes_NotAvailable" 2 "NoYes_Error" 1 "NoYes_Yes" 0 "NoYes_No" ;
VAL_ 2147485065 MaintInfoGrp_Unit39 7 "MaintenanceUnit_NotAvailable" 6 "MaintenanceUnit_Error" 5 "MaintenanceUnit_None" 4 "MaintenanceUnit_AxleNumber" 3 "MaintenanceUnit_Percentage" 2 "MaintenanceUnit_Date" 1 "MaintenanceUnit_Distance" 0 "MaintenanceUnit_EngineTime" ;
VAL_ 2147485065 MaintInfoGrp_Status5 7 "MaintenanceStatus_NotAvailable" 6 "MaintenanceStatus_Error" 5 "MaintenanceStatus_Spare_01" 4 "MaintenanceStatus_InProgress" 3 "MaintenanceStatus_Spare" 2 "MaintenanceStatus_Warning" 1 "MaintenanceStatus_PreWarning" 0 "MaintenanceStatus_OK" ;
VAL_ 2147485065 MaintInfoGrp_MaintOption6 15 "MaintOption_NotAvailable" 14 "MaintOption_Error" 13 "MaintOption_13" 12 "MaintOption_12" 11 "MaintOption_11" 10 "MaintOption_10" 9 "MaintOption_9" 8 "MaintOption_8" 7 "MaintOption_7" 6 "MaintOption_6" 5 "MaintOption_5" 4 "MaintOption_4" 3 "MaintOption_3" 2 "MaintOption_2" 1 "MaintOption_1" 0 "MaintOption_0" ;
VAL_ 2147485065 MaintInfoGrp_Status11 7 "MaintenanceStatus_NotAvailable" 6 "MaintenanceStatus_Error" 5 "MaintenanceStatus_Spare_01" 4 "MaintenanceStatus_InProgress" 3 "MaintenanceStatus_Spare" 2 "MaintenanceStatus_Warning" 1 "MaintenanceStatus_PreWarning" 0 "MaintenanceStatus_OK" ;
VAL_ 2147485065 MaintInfoGrp_Status19 7 "MaintenanceStatus_NotAvailable" 6 "MaintenanceStatus_Error" 5 "MaintenanceStatus_Spare_01" 4 "MaintenanceStatus_InProgress" 3 "MaintenanceStatus_Spare" 2 "MaintenanceStatus_Warning" 1 "MaintenanceStatus_PreWarning" 0 "MaintenanceStatus_OK" ;
VAL_ 2147485065 MaintInfoGrp_Status9 7 "MaintenanceStatus_NotAvailable" 6 "MaintenanceStatus_Error" 5 "MaintenanceStatus_Spare_01" 4 "MaintenanceStatus_InProgress" 3 "MaintenanceStatus_Spare" 2 "MaintenanceStatus_Warning" 1 "MaintenanceStatus_PreWarning" 0 "MaintenanceStatus_OK" ;
VAL_ 2147485065 MaintInfoGrp_Supported11 3 "NoYes_NotAvailable" 2 "NoYes_Error" 1 "NoYes_Yes" 0 "NoYes_No" ;
VAL_ 2147485065 MaintInfoGrp_MaintOption36 15 "MaintOption_NotAvailable" 14 "MaintOption_Error" 13 "MaintOption_13" 12 "MaintOption_12" 11 "MaintOption_11" 10 "MaintOption_10" 9 "MaintOption_9" 8 "MaintOption_8" 7 "MaintOption_7" 6 "MaintOption_6" 5 "MaintOption_5" 4 "MaintOption_4" 3 "MaintOption_3" 2 "MaintOption_2" 1 "MaintOption_1" 0 "MaintOption_0" ;
VAL_ 2147485065 MaintInfoGrp_ResetAuthorized8 3 "NoYes_NotAvailable" 2 "NoYes_Error" 1 "NoYes_Yes" 0 "NoYes_No" ;
VAL_ 2147485065 MaintInfoGrp_MaintOption21 15 "MaintOption_NotAvailable" 14 "MaintOption_Error" 13 "MaintOption_13" 12 "MaintOption_12" 11 "MaintOption_11" 10 "MaintOption_10" 9 "MaintOption_9" 8 "MaintOption_8" 7 "MaintOption_7" 6 "MaintOption_6" 5 "MaintOption_5" 4 "MaintOption_4" 3 "MaintOption_3" 2 "MaintOption_2" 1 "MaintOption_1" 0 "MaintOption_0" ;
VAL_ 2147485065 MaintInfoGrp_Unit23 7 "MaintenanceUnit_NotAvailable" 6 "MaintenanceUnit_Error" 5 "MaintenanceUnit_None" 4 "MaintenanceUnit_AxleNumber" 3 "MaintenanceUnit_Percentage" 2 "MaintenanceUnit_Date" 1 "MaintenanceUnit_Distance" 0 "MaintenanceUnit_EngineTime" ;
VAL_ 2147485065 MaintInfoGrp_MaintOption5 15 "MaintOption_NotAvailable" 14 "MaintOption_Error" 13 "MaintOption_13" 12 "MaintOption_12" 11 "MaintOption_11" 10 "MaintOption_10" 9 "MaintOption_9" 8 "MaintOption_8" 7 "MaintOption_7" 6 "MaintOption_6" 5 "MaintOption_5" 4 "MaintOption_4" 3 "MaintOption_3" 2 "MaintOption_2" 1 "MaintOption_1" 0 "MaintOption_0" ;
VAL_ 2147485065 MaintInfoGrp_MaintOption16 15 "MaintOption_NotAvailable" 14 "MaintOption_Error" 13 "MaintOption_13" 12 "MaintOption_12" 11 "MaintOption_11" 10 "MaintOption_10" 9 "MaintOption_9" 8 "MaintOption_8" 7 "MaintOption_7" 6 "MaintOption_6" 5 "MaintOption_5" 4 "MaintOption_4" 3 "MaintOption_3" 2 "MaintOption_2" 1 "MaintOption_1" 0 "MaintOption_0" ;
VAL_ 2147485065 MaintInfoGrp_Unit29 7 "MaintenanceUnit_NotAvailable" 6 "MaintenanceUnit_Error" 5 "MaintenanceUnit_None" 4 "MaintenanceUnit_AxleNumber" 3 "MaintenanceUnit_Percentage" 2 "MaintenanceUnit_Date" 1 "MaintenanceUnit_Distance" 0 "MaintenanceUnit_EngineTime" ;
VAL_ 2147485065 MaintInfoGrp_Status12 7 "MaintenanceStatus_NotAvailable" 6 "MaintenanceStatus_Error" 5 "MaintenanceStatus_Spare_01" 4 "MaintenanceStatus_InProgress" 3 "MaintenanceStatus_Spare" 2 "MaintenanceStatus_Warning" 1 "MaintenanceStatus_PreWarning" 0 "MaintenanceStatus_OK" ;
VAL_ 2147485065 MaintInfoGrp_Supported0 3 "NoYes_NotAvailable" 2 "NoYes_Error" 1 "NoYes_Yes" 0 "NoYes_No" ;
VAL_ 2147485065 MaintInfoGrp_Status8 7 "MaintenanceStatus_NotAvailable" 6 "MaintenanceStatus_Error" 5 "MaintenanceStatus_Spare_01" 4 "MaintenanceStatus_InProgress" 3 "MaintenanceStatus_Spare" 2 "MaintenanceStatus_Warning" 1 "MaintenanceStatus_PreWarning" 0 "MaintenanceStatus_OK" ;
VAL_ 2147485065 MaintInfoGrp_Unit0 7 "MaintenanceUnit_NotAvailable" 6 "MaintenanceUnit_Error" 5 "MaintenanceUnit_None" 4 "MaintenanceUnit_AxleNumber" 3 "MaintenanceUnit_Percentage" 2 "MaintenanceUnit_Date" 1 "MaintenanceUnit_Distance" 0 "MaintenanceUnit_EngineTime" ;
VAL_ 2147485065 MaintInfoGrp_Supported14 3 "NoYes_NotAvailable" 2 "NoYes_Error" 1 "NoYes_Yes" 0 "NoYes_No" ;
VAL_ 2147485065 MaintInfoGrp_Supported8 3 "NoYes_NotAvailable" 2 "NoYes_Error" 1 "NoYes_Yes" 0 "NoYes_No" ;
VAL_ 2147484987 MaintInfo_Status 7 "MaintenanceStatus_NotAvailable" 6 "MaintenanceStatus_Error" 5 "MaintenanceStatus_Spare_01" 4 "MaintenanceStatus_InProgress" 3 "MaintenanceStatus_Spare" 2 "MaintenanceStatus_Warning" 1 "MaintenanceStatus_PreWarning" 0 "MaintenanceStatus_OK" ;
VAL_ 2147484987 MaintInfo_Unit 7 "MaintenanceUnit_NotAvailable" 6 "MaintenanceUnit_Error" 5 "MaintenanceUnit_None" 4 "MaintenanceUnit_AxleNumber" 3 "MaintenanceUnit_Percentage" 2 "MaintenanceUnit_Date" 1 "MaintenanceUnit_Distance" 0 "MaintenanceUnit_EngineTime" ;
VAL_ 2147484987 MaintInfo_MaintID 63 "MaintID_NotAvailable" 62 "MaintID_Error" 39 "MaintID_Monitor39" 38 "MaintID_Monitor38" 37 "MaintID_Monitor37" 36 "MaintID_Monitor36" 35 "MaintID_Monitor35" 34 "MaintID_Monitor34" 33 "MaintID_Monitor33" 32 "MaintID_Monitor32" 31 "MaintID_Monitor31" 30 "MaintID_Monitor30" 29 "MaintID_Monitor29" 28 "MaintID_Monitor28" 27 "MaintID_Monitor27" 26 "MaintID_Monitor26" 25 "MaintID_Monitor25" 24 "MaintID_Monitor24" 23 "MaintID_Monitor23" 22 "MaintID_Monitor22" 21 "MaintID_Monitor21" 20 "MaintID_Monitor20" 19 "MaintID_Monitor19" 18 "MaintID_Monitor18" 17 "MaintID_Monitor17" 16 "MaintID_Monitor16" 15 "MaintID_Monitor15" 14 "MaintID_Monitor14" 13 "MaintID_Monitor13" 12 "MaintID_Monitor12" 11 "MaintID_Monitor11" 10 "MaintID_Monitor10" 9 "MaintID_Monitor9" 8 "MaintID_Monitor8" 7 "MaintID_Monitor7" 6 "MaintID_Monitor6" 5 "MaintID_Monitor5" 4 "MaintID_Monitor4" 3 "MaintID_Monitor3" 2 "MaintID_Monitor2" 1 "MaintID_Monitor1" 0 "MaintID_Monitor0" ;
VAL_ 2147484987 MaintInfo_Supported 3 "NoYes_NotAvailable" 2 "NoYes_Error" 1 "NoYes_Yes" 0 "NoYes_No" ;
VAL_ 2147484987 MaintInfo_ResetAuthorized 3 "NoYes_NotAvailable" 2 "NoYes_Error" 1 "NoYes_Yes" 0 "NoYes_No" ;
VAL_ 2147484987 MaintInfo_MaintOption 15 "MaintOption_NotAvailable" 14 "MaintOption_Error" 13 "MaintOption_13" 12 "MaintOption_12" 11 "MaintOption_11" 10 "MaintOption_10" 9 "MaintOption_9" 8 "MaintOption_8" 7 "MaintOption_7" 6 "MaintOption_6" 5 "MaintOption_5" 4 "MaintOption_4" 3 "MaintOption_3" 2 "MaintOption_2" 1 "MaintOption_1" 0 "MaintOption_0" ;
VAL_ 2147484888 TransferCasePTOEngaged_ISig_4 3 "NotEngagedEngaged_NotAvailable" 2 "NotEngagedEngaged_Error" 1 "NotEngagedEngaged_Engaged" 0 "NotEngagedEngaged_NotEngaged" ;
VAL_ 2147485078 DrawerState 3 "DrawerState_NotAvailable" 2 "DrawerState_Error" 1 "DrawerState_Close" 0 "DrawerState_Open" ;
VAL_ 2147485078 EndofLifeDriver1Card 3 "Alert_NotAvailable" 2 "Alert_Error" 1 "Alert_Alert" 0 "Alert_NoAlert" ;
VAL_ 2147485078 Driver1CardUnload 3 "Alert_NotAvailable" 2 "Alert_Error" 1 "Alert_Alert" 0 "Alert_NoAlert" ;
VAL_ 2147485059 MIStatusExtVMCU 3 "MIStatusExt_NotAvailable" 2 "MIStatusExt_Error" 1 "MIStatusExt_Ready" 0 "MIStatusExt_NotReady5Flash" ;
VAL_ 2147485059 MIDistinctWarningExtVMCU 15 "MIDistinctWarningExt_NotAvailable" 14 "MIDistinctWarningExt_Error" 3 "MIDistinctWarningExt_ContinuousMISteady" 2 "MIDistinctWarningExt_ShortMI3Flash" 1 "MIDistinctWarningExt_OnDemandMI2Flash" 0 "MIDistinctWarningExt_Off1Flash" ;
VAL_ 2147484915 StaticCornerLightLamp_stat_ISig_ 7 "LampCheckLeftRight_stat_NotAvailable" 6 "LampCheckLeftRight_stat_Error" 5 "LampCheckLeftRight_stat_Spare" 4 "LampCheckLeftRight_stat_TestedLeftAndRightLampNOK" 3 "LampCheckLeftRight_stat_TestedRightLampNOK" 2 "LampCheckLeftRight_stat_TestedLeftLampNOK" 1 "LampCheckLeftRight_stat_TestedLampOK" 0 "LampCheckLeftRight_stat_NotTested" ;
VAL_ 2147484915 DRLLamp_stat_ISig_4 7 "LampCheckLeftRight_stat_NotAvailable" 6 "LampCheckLeftRight_stat_Error" 5 "LampCheckLeftRight_stat_Spare" 4 "LampCheckLeftRight_stat_TestedLeftAndRightLampNOK" 3 "LampCheckLeftRight_stat_TestedRightLampNOK" 2 "LampCheckLeftRight_stat_TestedLeftLampNOK" 1 "LampCheckLeftRight_stat_TestedLampOK" 0 "LampCheckLeftRight_stat_NotTested" ;
VAL_ 2147484915 DirInd_Front_Status_ISig_4 7 "DirIndFaultStatus_NotAvailable" 6 "DirIndFaultStatus_Error" 5 "DirIndFaultStatus_SpareValue_01" 4 "DirIndFaultStatus_SpareValue" 3 "DirIndFaultStatus_BothLeftAndRightDirectionIndicatorsFault" 2 "DirIndFaultStatus_RightDirectionIndicatorLampFault" 1 "DirIndFaultStatus_LeftDirectionIndicatorLampFault" 0 "DirIndFaultStatus_NoError" ;
VAL_ 2147484915 ChassiInstepLightsLamp_stat_ISig 7 "LampCheck_stat_NotAvailable" 6 "LampCheck_stat_Error" 5 "LampCheck_stat_Spare_02" 4 "LampCheck_stat_Spare_01" 3 "LampCheck_stat_Spare" 2 "LampCheck_stat_TestedLampNOK" 1 "LampCheck_stat_TestedLampOK" 0 "LampCheck_stat_NotTested" ;
VAL_ 2147484915 PositionLightLamp_stat_ISig_4 7 "LampCheckLeftRight_stat_NotAvailable" 6 "LampCheckLeftRight_stat_Error" 5 "LampCheckLeftRight_stat_Spare" 4 "LampCheckLeftRight_stat_TestedLeftAndRightLampNOK" 3 "LampCheckLeftRight_stat_TestedRightLampNOK" 2 "LampCheckLeftRight_stat_TestedLeftLampNOK" 1 "LampCheckLeftRight_stat_TestedLampOK" 0 "LampCheckLeftRight_stat_NotTested" ;
VAL_ 2147484915 BrakeLightLamp_stat_ISig_4 7 "LampCheckLeftRight_stat_NotAvailable" 6 "LampCheckLeftRight_stat_Error" 5 "LampCheckLeftRight_stat_Spare" 4 "LampCheckLeftRight_stat_TestedLeftAndRightLampNOK" 3 "LampCheckLeftRight_stat_TestedRightLampNOK" 2 "LampCheckLeftRight_stat_TestedLeftLampNOK" 1 "LampCheckLeftRight_stat_TestedLampOK" 0 "LampCheckLeftRight_stat_NotTested" ;
VAL_ 2147484915 RevLightLamp_stat_ISig_4 7 "LampCheckLeftRight_stat_NotAvailable" 6 "LampCheckLeftRight_stat_Error" 5 "LampCheckLeftRight_stat_Spare" 4 "LampCheckLeftRight_stat_TestedLeftAndRightLampNOK" 3 "LampCheckLeftRight_stat_TestedRightLampNOK" 2 "LampCheckLeftRight_stat_TestedLeftLampNOK" 1 "LampCheckLeftRight_stat_TestedLampOK" 0 "LampCheckLeftRight_stat_NotTested" ;
VAL_ 2147484915 AuxFogLightLamp_stat_ISig_4 7 "LampCheckLeftRight_stat_NotAvailable" 6 "LampCheckLeftRight_stat_Error" 5 "LampCheckLeftRight_stat_Spare" 4 "LampCheckLeftRight_stat_TestedLeftAndRightLampNOK" 3 "LampCheckLeftRight_stat_TestedRightLampNOK" 2 "LampCheckLeftRight_stat_TestedLeftLampNOK" 1 "LampCheckLeftRight_stat_TestedLampOK" 0 "LampCheckLeftRight_stat_NotTested" ;
VAL_ 2147484915 AirCleanerUnderPressure 3 "AirCleanerUnderPressure_NotAvailable" 2 "AirCleanerUnderPressure_Spare" 1 "AirCleanerUnderPressure_UnderPressure" 0 "AirCleanerUnderPressure_OK" ;
VAL_ 2147484915 DirIndSideLamp_stat 7 "LampCheckLeftRight_stat_NotAvailable" 6 "LampCheckLeftRight_stat_Error" 5 "LampCheckLeftRight_stat_Spare" 4 "LampCheckLeftRight_stat_TestedLeftAndRightLampNOK" 3 "LampCheckLeftRight_stat_TestedRightLampNOK" 2 "LampCheckLeftRight_stat_TestedLeftLampNOK" 1 "LampCheckLeftRight_stat_TestedLampOK" 0 "LampCheckLeftRight_stat_NotTested" ;
VAL_ 2147484915 TrailerRevAndFogOutput_stat_ISig 3 "LightOutput_stat_NotAvailable" 2 "LightOutput_stat_OCOnAllActiveOutputs" 1 "LightOutput_stat_AtLeastOneOutputActive" 0 "LightOutput_stat_AllOutputsInactive" ;
VAL_ 2147484915 MainBeamLamp_stat_ISig_4 7 "LampCheckLeftRight_stat_NotAvailable" 6 "LampCheckLeftRight_stat_Error" 5 "LampCheckLeftRight_stat_Spare" 4 "LampCheckLeftRight_stat_TestedLeftAndRightLampNOK" 3 "LampCheckLeftRight_stat_TestedRightLampNOK" 2 "LampCheckLeftRight_stat_TestedLeftLampNOK" 1 "LampCheckLeftRight_stat_TestedLampOK" 0 "LampCheckLeftRight_stat_NotTested" ;
VAL_ 2147484915 ExtraMainBeamLamp_stat_ISig_4 7 "LampCheckLeftRight_stat_NotAvailable" 6 "LampCheckLeftRight_stat_Error" 5 "LampCheckLeftRight_stat_Spare" 4 "LampCheckLeftRight_stat_TestedLeftAndRightLampNOK" 3 "LampCheckLeftRight_stat_TestedRightLampNOK" 2 "LampCheckLeftRight_stat_TestedLeftLampNOK" 1 "LampCheckLeftRight_stat_TestedLampOK" 0 "LampCheckLeftRight_stat_NotTested" ;
VAL_ 2147484915 FogLightFrontLamp_stat_ISig_4 7 "LampCheck_stat_NotAvailable" 6 "LampCheck_stat_Error" 5 "LampCheck_stat_Spare_02" 4 "LampCheck_stat_Spare_01" 3 "LampCheck_stat_Spare" 2 "LampCheck_stat_TestedLampNOK" 1 "LampCheck_stat_TestedLampOK" 0 "LampCheck_stat_NotTested" ;
VAL_ 2147484915 DippedBeamLamp_stat_ISig_4 7 "LampCheckLeftRight_stat_NotAvailable" 6 "LampCheckLeftRight_stat_Error" 5 "LampCheckLeftRight_stat_Spare" 4 "LampCheckLeftRight_stat_TestedLeftAndRightLampNOK" 3 "LampCheckLeftRight_stat_TestedRightLampNOK" 2 "LampCheckLeftRight_stat_TestedLeftLampNOK" 1 "LampCheckLeftRight_stat_TestedLampOK" 0 "LampCheckLeftRight_stat_NotTested" ;
VAL_ 2147484915 FogLightRearLamp_stat_ISig_4 7 "LampCheck_stat_NotAvailable" 6 "LampCheck_stat_Error" 5 "LampCheck_stat_Spare_02" 4 "LampCheck_stat_Spare_01" 3 "LampCheck_stat_Spare" 2 "LampCheck_stat_TestedLampNOK" 1 "LampCheck_stat_TestedLampOK" 0 "LampCheck_stat_NotTested" ;
SIG_GROUP_ 2147485065 MaintInfoGrp_sg 1 : MaintInfoGrp_MaintOption30 MaintInfoGrp_Unit36 MaintInfoGrp_MaintOption33 MaintInfoGrp_ResetAuthorized32 MaintInfoGrp_Status10 MaintInfoGrp_Unit2 MaintInfoGrp_Unit14 MaintInfoGrp_ResetAuthorized28 MaintInfoGrp_ResetAuthorized10 MaintInfoGrp_Status31 MaintInfoGrp_Unit32 MaintInfoGrp_Status15 MaintInfoGrp_Supported19 MaintInfoGrp_Unit34 MaintInfoGrp_Data17 MaintInfoGrp_Unit26 MaintInfoGrp_Data24 MaintInfoGrp_ResetAuthorized24 MaintInfoGrp_ResetAuthorized34 MaintInfoGrp_Unit28 MaintInfoGrp_Status26 MaintInfoGrp_Unit10 MaintInfoGrp_Data12 MaintInfoGrp_ResetAuthorized38 MaintInfoGrp_MaintOption14 MaintInfoGrp_MaintOption17 MaintInfoGrp_Status33 MaintInfoGrp_Unit6 MaintInfoGrp_Supported7 MaintInfoGrp_Status7 MaintInfoGrp_ResetAuthorized2 MaintInfoGrp_MaintOption27 MaintInfoGrp_Supported36 MaintInfoGrp_Unit22 MaintInfoGrp_Unit18 MaintInfoGrp_MaintOption28 MaintInfoGrp_Supported18 MaintInfoGrp_Status22 MaintInfoGrp_Status30 MaintInfoGrp_Status20 MaintInfoGrp_Status38 MaintInfoGrp_Data38 MaintInfoGrp_ResetAuthorized7 MaintInfoGrp_Data19 MaintInfoGrp_ResetAuthorized19 MaintInfoGrp_ResetAuthorized12 MaintInfoGrp_MaintOption8 MaintInfoGrp_MaintOption9 MaintInfoGrp_ResetAuthorized13 MaintInfoGrp_Unit31 MaintInfoGrp_Status2 MaintInfoGrp_ResetAuthorized5 MaintInfoGrp_Supported33 MaintInfoGrp_Unit7 MaintInfoGrp_Supported34 MaintInfoGrp_Data16 MaintInfoGrp_Unit19 MaintInfoGrp_ResetAuthorized21 MaintInfoGrp_ResetAuthorized31 MaintInfoGrp_Data28 MaintInfoGrp_ResetAuthorized3 MaintInfoGrp_MaintOption34 MaintInfoGrp_Status21 MaintInfoGrp_Unit21 MaintInfoGrp_MaintOption24 MaintInfoGrp_Data26 MaintInfoGrp_Data37 MaintInfoGrp_Data35 MaintInfoGrp_Supported17 MaintInfoGrp_ResetAuthorized17 MaintInfoGrp_Unit25 MaintInfoGrp_Unit37 MaintInfoGrp_MaintOption2 MaintInfoGrp_Supported21 MaintInfoGrp_ResetAuthorized16 MaintInfoGrp_Supported15 MaintInfoGrp_ResetAuthorized9 MaintInfoGrp_MaintOption18 MaintInfoGrp_Data14 MaintInfoGrp_Data8 MaintInfoGrp_Supported29 MaintInfoGrp_ResetAuthorized39 MaintInfoGrp_Supported32 MaintInfoGrp_Data33 MaintInfoGrp_ResetAuthorized35 MaintInfoGrp_Data30 MaintInfoGrp_ResetAuthorized29 MaintInfoGrp_Supported35 MaintInfoGrp_ResetAuthorized4 MaintInfoGrp_Data10 MaintInfoGrp_Data9 MaintInfoGrp_Unit1 MaintInfoGrp_MaintOption7 MaintInfoGrp_Supported24 MaintInfoGrp_Supported25 MaintInfoGrp_Unit15 MaintInfoGrp_Supported1 MaintInfoGrp_ResetAuthorized11 MaintInfoGrp_Supported13 MaintInfoGrp_Supported10 MaintInfoGrp_Data2 MaintInfoGrp_Unit16 MaintInfoGrp_MaintOption35 MaintInfoGrp_MaintOption22 MaintInfoGrp_MaintOption12 MaintInfoGrp_Supported9 MaintInfoGrp_Supported31 MaintInfoGrp_MaintOption37 MaintInfoGrp_MaintOption13 MaintInfoGrp_ResetAuthorized22 MaintInfoGrp_Status14 MaintInfoGrp_Status18 MaintInfoGrp_Unit17 MaintInfoGrp_Unit12 MaintInfoGrp_Data22 MaintInfoGrp_Supported27 MaintInfoGrp_Unit4 MaintInfoGrp_Data13 MaintInfoGrp_Status27 MaintInfoGrp_MaintOption29 MaintInfoGrp_Unit9 MaintInfoGrp_Unit13 MaintInfoGrp_Data25 MaintInfoGrp_Unit3 MaintInfoGrp_MaintOption15 MaintInfoGrp_ResetAuthorized15 MaintInfoGrp_MaintOption11 MaintInfoGrp_MaintOption25 MaintInfoGrp_Supported16 MaintInfoGrp_Supported23 MaintInfoGrp_Status13 MaintInfoGrp_Status17 MaintInfoGrp_Unit8 MaintInfoGrp_MaintOption38 MaintInfoGrp_Data4 MaintInfoGrp_Supported2 MaintInfoGrp_ResetAuthorized0 MaintInfoGrp_Supported5 MaintInfoGrp_Status6 MaintInfoGrp_Unit5 MaintInfoGrp_Data0 MaintInfoGrp_Data29 MaintInfoGrp_Supported28 MaintInfoGrp_Status32 MaintInfoGrp_MaintOption0 MaintInfoGrp_ResetAuthorized25 MaintInfoGrp_MaintOption32 MaintInfoGrp_Unit11 MaintInfoGrp_Data39 MaintInfoGrp_MaintOption4 MaintInfoGrp_Supported38 MaintInfoGrp_MaintOption1 MaintInfoGrp_Supported30 MaintInfoGrp_ResetAuthorized33 MaintInfoGrp_Status0 MaintInfoGrp_ResetAuthorized20 MaintInfoGrp_Unit33 MaintInfoGrp_Supported26 MaintInfoGrp_ResetAuthorized6 MaintInfoGrp_Data18 MaintInfoGrp_Status16 MaintInfoGrp_ResetAuthorized18 MaintInfoGrp_Status4 MaintInfoGrp_Data3 MaintInfoGrp_MaintOption20 MaintInfoGrp_ResetAuthorized30 MaintInfoGrp_ResetAuthorized23 MaintInfoGrp_Unit30 MaintInfoGrp_Data20 MaintInfoGrp_MaintOption23 MaintInfoGrp_Data23 MaintInfoGrp_Unit20 MaintInfoGrp_MaintOption10 MaintInfoGrp_Status39 MaintInfoGrp_Data21 MaintInfoGrp_Status3 MaintInfoGrp_Data5 MaintInfoGrp_ResetAuthorized26 MaintInfoGrp_Supported12 MaintInfoGrp_Data32 MaintInfoGrp_Status29 MaintInfoGrp_ResetAuthorized37 MaintInfoGrp_Status36 MaintInfoGrp_Supported22 MaintInfoGrp_Status35 MaintInfoGrp_Data7 MaintInfoGrp_MaintOption26 MaintInfoGrp_Status23 MaintInfoGrp_Unit35 MaintInfoGrp_Supported6 MaintInfoGrp_Data34 MaintInfoGrp_Unit27 MaintInfoGrp_MaintOption19 MaintInfoGrp_ResetAuthorized14 MaintInfoGrp_Status34 MaintInfoGrp_Supported37 MaintInfoGrp_MaintOption3 MaintInfoGrp_Status1 MaintInfoGrp_Data1 MaintInfoGrp_Status25 MaintInfoGrp_ResetAuthorized1 MaintInfoGrp_ResetAuthorized27 MaintInfoGrp_ResetAuthorized36 MaintInfoGrp_Status28 MaintInfoGrp_Status24 MaintInfoGrp_MaintOption31 MaintInfoGrp_Supported20 MaintInfoGrp_Unit38 MaintInfoGrp_Unit24 MaintInfoGrp_Data15 MaintInfoGrp_Status37 MaintInfoGrp_Supported39 MaintInfoGrp_MaintOption39 MaintInfoGrp_Supported4 MaintInfoGrp_Supported3 MaintInfoGrp_Data6 MaintInfoGrp_Unit39 MaintInfoGrp_Status5 MaintInfoGrp_Data36 MaintInfoGrp_MaintOption6 MaintInfoGrp_Status11 MaintInfoGrp_Status19 MaintInfoGrp_Status9 MaintInfoGrp_Supported11 MaintInfoGrp_Data27 MaintInfoGrp_Data31 MaintInfoGrp_MaintOption36 MaintInfoGrp_ResetAuthorized8 MaintInfoGrp_MaintOption21 MaintInfoGrp_Unit23 MaintInfoGrp_MaintOption5 MaintInfoGrp_MaintOption16 MaintInfoGrp_Unit29 MaintInfoGrp_Status12 MaintInfoGrp_Supported0 MaintInfoGrp_Status8 MaintInfoGrp_Data11 MaintInfoGrp_Unit0 MaintInfoGrp_Supported14 MaintInfoGrp_Supported8;
SIG_GROUP_ 2147484987 MaintInfo_sg 1 : MaintInfo_Status MaintInfo_Unit MaintInfo_MaintID MaintInfo_Supported MaintInfo_ResetAuthorized MaintInfo_MaintOption MaintInfo_Data;
